VERSION "dbc-export 1 2025.20.8"

NS_ :

BS_:

BU_: APP APS DAS EPAS3S ESP GTW IBST PARK RADC RCM RCM3 TPMS USM

BO_ 586 DAS_visualDebug: 8 DAS
 SG_ DAS_autosteerVehiclesUsage : 4|2@1+ (1,0) [0|3] "" Vector__XXX
 SG_ DAS_autosteerHPPUsage : 6|2@1+ (1,0) [0|3] "" Vector__XXX
 SG_ DAS_autosteerNavigationUsage : 8|2@1+ (1,0) [0|3] "" Vector__XXX
 SG_ DAS_autosteerModelUsage : 10|2@1+ (1,0) [0|3] "" Vector__XXX
 SG_ DAS_autosteerBottsDotsUsage : 12|2@1+ (1,0) [0|3] "" Vector__XXX
 SG_ DAS_offsetSide : 14|2@1+ (1,0) [0|3] "" Vector__XXX
 SG_ DAS_roadSurfaceType : 16|2@1+ (1,0) [1|3] "" Vector__XXX
 SG_ DAS_autosteerHealthAnomalyLevel : 18|3@1+ (1,0) [0|7] "" Vector__XXX
 SG_ DAS_autosteerHealthState : 21|3@1+ (1,0) [0|7] "" Vector__XXX
 SG_ DAS_lastLinePreferenceReason : 24|4@1+ (1,0) [0|15] "" Vector__XXX
 SG_ DAS_plannerState : 28|4@1+ (1,0) [0|15] "" Vector__XXX
 SG_ DAS_lastAutosteerAbortReason : 32|6@1+ (1,0) [0|63] "" Vector__XXX
 SG_ DAS_devAppInterfaceEnabled : 38|1@1+ (1,0) [0|1] "" Vector__XXX
 SG_ DAS_navAvailable : 39|1@1+ (1,0) [0|1] "" Vector__XXX
 SG_ DAS_navDistance : 40|8@1+ (100,0) [0|25500] "km" Vector__XXX
 SG_ DAS_accSmartSpeedActive : 48|1@1+ (1,0) [0|1] "" Vector__XXX
 SG_ DAS_accSmartSpeedState : 49|3@1+ (1,0) [0|6] "" Vector__XXX
 SG_ DAS_ulcInProgress : 52|1@1+ (1,0) [0|1] "" Vector__XXX
 SG_ DAS_trafficAwareSetSpeedInUse : 53|1@1+ (1,0) [0|1] "" Vector__XXX
 SG_ DAS_isaSystemState : 54|2@1+ (1,0) [0|3] "" Vector__XXX
 SG_ DAS_behaviorType : 56|2@1+ (1,0) [0|3] "" Vector__XXX
 SG_ DAS_ulcType : 58|2@1+ (1,0) [0|3] "" Vector__XXX
 SG_ DAS_rearVehDetectedThisCycle : 60|1@1+ (1,0) [0|1] "" Vector__XXX
 SG_ DAS_rearLeftVehDetectedCurrent : 61|1@1+ (1,0) [0|1] "" Vector__XXX
 SG_ DAS_rearRightVehDetectedTrip : 62|1@1+ (1,0) [0|1] "" Vector__XXX
 SG_ DAS_rearLeftVehDetectedTrip : 63|1@1+ (1,0) [0|1] "" Vector__XXX

BO_ 810 DAS_warningMatrix0: 8 DAS
 SG_ DAS_w002_ldwDisabled : 1|1@1+ (1,0) [0|1] "" Vector__XXX
 SG_ DAS_w003_isaDisabled : 2|1@1+ (1,0) [0|1] "" Vector__XXX
 SG_ DAS_w004_accDisabled : 3|1@1+ (1,0) [0|1] "" Vector__XXX
 SG_ DAS_w005_fcwCancelled : 4|1@1+ (1,0) [0|1] "" Vector__XXX
 SG_ DAS_w006_aebCancelled : 5|1@1+ (1,0) [0|1] "" Vector__XXX
 SG_ DAS_w007_ahlbDisabled : 6|1@1+ (1,0) [0|1] "" Vector__XXX
 SG_ DAS_w008_parkDisabled : 7|1@1+ (1,0) [0|1] "" Vector__XXX
 SG_ DAS_w009_aebFault : 8|1@1+ (1,0) [0|1] "" Vector__XXX
 SG_ DAS_w010_radcCalibIssue : 9|1@1+ (1,0) [0|1] "" Vector__XXX
 SG_ DAS_w011_scaEvent : 10|1@1+ (1,0) [0|1] "" Vector__XXX
 SG_ DAS_w012_Cam_BootFailure : 11|1@1+ (1,0) [0|1] "" Vector__XXX
 SG_ DAS_w013_Cam_Watchdog : 12|1@1+ (1,0) [0|1] "" Vector__XXX
 SG_ DAS_w014_swAssert : 13|1@1+ (1,0) [0|1] "" Vector__XXX
 SG_ DAS_w015_Camera_Failsafes : 14|1@1+ (1,0) [0|1] "" Vector__XXX
 SG_ DAS_w016_aeb_e_event : 15|1@1+ (1,0) [0|1] "" Vector__XXX
 SG_ DAS_w017_Cam_Msg_MIA : 16|1@1+ (1,0) [0|1] "" Vector__XXX
 SG_ DAS_w018_ECU_Power_Issue : 17|1@1+ (1,0) [0|1] "" Vector__XXX
 SG_ DAS_w019_ECU_Stack_Overflow : 18|1@1+ (1,0) [0|1] "" Vector__XXX
 SG_ DAS_w020_ECU_checkstopError : 19|1@1+ (1,0) [0|1] "" Vector__XXX
 SG_ DAS_w021_ECU_Temperature_Issue : 20|1@1+ (1,0) [0|1] "" Vector__XXX
 SG_ DAS_w022_ECU_EEPROM_Failure : 21|1@1+ (1,0) [0|1] "" Vector__XXX
 SG_ DAS_w023_ECU_Cam_Statemismatc : 22|1@1+ (1,0) [0|1] "" Vector__XXX
 SG_ DAS_w024_ECU_Watchdog_Reset : 23|1@1+ (1,0) [0|1] "" Vector__XXX
 SG_ DAS_w025_LC_Steering_Override : 24|1@1+ (1,0) [0|1] "" Vector__XXX
 SG_ DAS_w026_ECU_timingIssue : 25|1@1+ (1,0) [0|1] "" Vector__XXX
 SG_ DAS_w027_ECU_Reset_Fault : 26|1@1+ (1,0) [0|1] "" Vector__XXX
 SG_ DAS_w028_spi_rx_error : 27|1@1+ (1,0) [0|1] "" Vector__XXX
 SG_ DAS_w029_spi_tx_error : 28|1@1+ (1,0) [0|1] "" Vector__XXX
 SG_ DAS_w030_Heater_Issue : 29|1@1+ (1,0) [0|1] "" Vector__XXX
 SG_ DAS_w031_canRxError : 30|1@1+ (1,0) [0|1] "" Vector__XXX
 SG_ DAS_w032_canTxError : 31|1@1+ (1,0) [0|1] "" Vector__XXX
 SG_ DAS_w033_gtwMia : 32|1@1+ (1,0) [0|1] "" Vector__XXX
 SG_ DAS_w034_sccmMia : 33|1@1+ (1,0) [0|1] "" Vector__XXX
 SG_ DAS_w035_espMia : 34|1@1+ (1,0) [0|1] "" Vector__XXX
 SG_ DAS_w036_bdyMia : 35|1@1+ (1,0) [0|1] "" Vector__XXX
 SG_ DAS_w037_camTacIssue : 36|1@1+ (1,0) [0|1] "" Vector__XXX
 SG_ DAS_w038_camFailure : 37|1@1+ (1,0) [0|1] "" Vector__XXX
 SG_ DAS_w039_sdm_rcm_Mia : 38|1@1+ (1,0) [0|1] "" Vector__XXX
 SG_ DAS_w040_autopilotAngleSaturated : 39|1@1+ (1,0) [0|1] "" Vector__XXX
 SG_ DAS_w041_autopilotRateSaturated : 40|1@1+ (1,0) [0|1] "" Vector__XXX
 SG_ DAS_w042_autopilotAborting : 41|1@1+ (1,0) [0|1] "" Vector__XXX
 SG_ DAS_w043_camLongRunTime : 42|1@1+ (1,0) [0|1] "" Vector__XXX
 SG_ DAS_w044_appMobileyeFailure : 43|1@1+ (1,0) [0|1] "" Vector__XXX
 SG_ DAS_w045_radMia : 44|1@1+ (1,0) [0|1] "" Vector__XXX
 SG_ DAS_w046_eepromRecordAbsent : 45|1@1+ (1,0) [0|1] "" Vector__XXX
 SG_ DAS_w047_edrEvent : 46|1@1+ (1,0) [0|1] "" Vector__XXX
 SG_ DAS_w048_DAS_Features_Disabled : 47|1@1+ (1,0) [0|1] "" Vector__XXX
 SG_ DAS_w049_eyeqVersionMismatch : 48|1@1+ (1,0) [0|1] "" Vector__XXX
 SG_ DAS_w050_aeb_event : 49|1@1+ (1,0) [0|1] "" Vector__XXX
 SG_ DAS_w051_radcEcuIssue : 50|1@1+ (1,0) [0|1] "" Vector__XXX
 SG_ DAS_w052_radcSensorIssue : 51|1@1+ (1,0) [0|1] "" Vector__XXX
 SG_ DAS_w053_radcCommIssue : 52|1@1+ (1,0) [0|1] "" Vector__XXX
 SG_ DAS_w054_camAutofix : 53|1@1+ (1,0) [0|1] "" Vector__XXX
 SG_ DAS_w055_radcVersionMismatch : 54|1@1+ (1,0) [0|1] "" Vector__XXX
 SG_ DAS_w056_diMia : 55|1@1+ (1,0) [0|1] "" Vector__XXX
 SG_ DAS_w057_mcuMia : 56|1@1+ (1,0) [0|1] "" Vector__XXX
 SG_ DAS_w058_epbMia : 57|1@1+ (1,0) [0|1] "" Vector__XXX
 SG_ DAS_w059_parkMia : 58|1@1+ (1,0) [0|1] "" Vector__XXX
 SG_ DAS_w060_fcw_event : 59|1@1+ (1,0) [0|1] "" Vector__XXX
 SG_ DAS_w061_airSuspensionMia : 60|1@1+ (1,0) [0|1] "" Vector__XXX
 SG_ DAS_w062_radcAlignment : 61|1@1+ (1,0) [0|1] "" Vector__XXX
 SG_ DAS_w063_parkVersionMismatch : 62|1@1+ (1,0) [0|1] "" Vector__XXX
 SG_ DAS_w064_epasMia : 63|1@1+ (1,0) [0|1] "" Vector__XXX

BO_ 874 DAS_warningMatrix1: 8 DAS
 SG_ DAS_w065_deserializerOvercurrent : 0|1@1+ (1,0) [0|1] "" Vector__XXX
 SG_ DAS_w066_deserializerLockLost : 1|1@1+ (1,0) [0|1] "" Vector__XXX
 SG_ DAS_w067_steeringAlignment : 2|1@1+ (1,0) [0|1] "" Vector__XXX
 SG_ DAS_w068_vlInconsistency : 3|1@1+ (1,0) [0|1] "" Vector__XXX
 SG_ DAS_w069_apcSpaceMasked : 4|1@1+ (1,0) [0|1] "" Vector__XXX
 SG_ DAS_w070_apcIncompleteCal : 5|1@1+ (1,0) [0|1] "" Vector__XXX
 SG_ DAS_w071_selfparkStarted : 6|1@1+ (1,0) [0|1] "" Vector__XXX
 SG_ DAS_w072_selfparkComplete : 7|1@1+ (1,0) [0|1] "" Vector__XXX
 SG_ DAS_w073_issueEscalatedLDW : 8|1@1+ (1,0) [0|1] "" Vector__XXX
 SG_ DAS_w074_inPathStationaryObst : 9|1@1+ (1,0) [0|1] "" Vector__XXX
 SG_ DAS_w075_scMia : 10|1@1+ (1,0) [0|1] "" Vector__XXX
 SG_ DAS_w076_mobilEyeSetC : 11|1@1+ (1,0) [0|1] "" Vector__XXX
 SG_ DAS_w077_pmmActive : 12|1@1+ (1,0) [0|1] "" Vector__XXX
 SG_ DAS_w078_pmmActive2 : 13|1@1+ (1,0) [0|1] "" Vector__XXX
 SG_ DAS_w079_edrAvailable : 14|1@1+ (1,0) [0|1] "" Vector__XXX
 SG_ DAS_w080_accFailedActivation : 15|1@1+ (1,0) [0|1] "" Vector__XXX
 SG_ DAS_w081_pmmActiveBraking : 16|1@1+ (1,0) [0|1] "" Vector__XXX
 SG_ DAS_w082_inPathFSviolation : 17|1@1+ (1,0) [0|1] "" Vector__XXX
 SG_ DAS_w083_inPathRADObject : 18|1@1+ (1,0) [0|1] "" Vector__XXX
 SG_ DAS_w084_pmmIPSO : 19|1@1+ (1,0) [0|1] "" Vector__XXX
 SG_ DAS_w085_pmmSteering : 20|1@1+ (1,0) [0|1] "" Vector__XXX
 SG_ DAS_w086_robCollision : 21|1@1+ (1,0) [0|1] "" Vector__XXX
 SG_ DAS_w087_DEPRECATED : 22|1@1+ (1,0) [0|1] "" Vector__XXX
 SG_ DAS_w088_DEPRECATED : 23|1@1+ (1,0) [0|1] "" Vector__XXX
 SG_ DAS_w089_DEPRECATED : 24|1@1+ (1,0) [0|1] "" Vector__XXX
 SG_ DAS_w090_DEPRECATED : 25|1@1+ (1,0) [0|1] "" Vector__XXX
 SG_ DAS_w091_DEPRECATED : 26|1@1+ (1,0) [0|1] "" Vector__XXX
 SG_ DAS_w092_DEPRECATED : 27|1@1+ (1,0) [0|1] "" Vector__XXX
 SG_ DAS_w093_DEPRECATED : 28|1@1+ (1,0) [0|1] "" Vector__XXX
 SG_ DAS_w094_DEPRECATED : 29|1@1+ (1,0) [0|1] "" Vector__XXX
 SG_ DAS_w095_DEPRECATED : 30|1@1+ (1,0) [0|1] "" Vector__XXX
 SG_ DAS_w096_DEPRECATED : 31|1@1+ (1,0) [0|1] "" Vector__XXX
 SG_ DAS_w097_DEPRECATED : 32|1@1+ (1,0) [0|1] "" Vector__XXX
 SG_ DAS_w098_DEPRECATED : 33|1@1+ (1,0) [0|1] "" Vector__XXX
 SG_ DAS_w099_DEPRECATED : 34|1@1+ (1,0) [0|1] "" Vector__XXX
 SG_ DAS_w100_DEPRECATED : 35|1@1+ (1,0) [0|1] "" Vector__XXX
 SG_ DAS_w101_DEPRECATED : 36|1@1+ (1,0) [0|1] "" Vector__XXX
 SG_ DAS_w102_DEPRECATED : 37|1@1+ (1,0) [0|1] "" Vector__XXX
 SG_ DAS_w103_robExperimentalAEB : 38|1@1+ (1,0) [0|1] "" Vector__XXX
 SG_ DAS_w104_DEPRECATED : 39|1@1+ (1,0) [0|1] "" Vector__XXX
 SG_ DAS_w105_DEPRECATED : 40|1@1+ (1,0) [0|1] "" Vector__XXX
 SG_ DAS_w106_torsionBarCalibrated : 41|1@1+ (1,0) [0|1] "" Vector__XXX

BO_ 841 DAS_warningMatrix2: 8 DAS
 SG_ DAS_w129_mainCamExtNotCal : 0|1@1+ (1,0) [0|1] "" Vector__XXX
 SG_ DAS_w130_narrowCamExtNotCal : 1|1@1+ (1,0) [0|1] "" Vector__XXX
 SG_ DAS_w131_mainCamCalSaved : 2|1@1+ (1,0) [0|1] "" Vector__XXX
 SG_ DAS_w132_narrowCamCalSaved : 3|1@1+ (1,0) [0|1] "" Vector__XXX
 SG_ DAS_w133_mainCamInitFault : 4|1@1+ (1,0) [0|1] "" Vector__XXX
 SG_ DAS_w134_narrowCamInitFault : 5|1@1+ (1,0) [0|1] "" Vector__XXX
 SG_ DAS_w135_fisheyeCamInitFault : 6|1@1+ (1,0) [0|1] "" Vector__XXX
 SG_ DAS_w136_lPillarCamInitFault : 7|1@1+ (1,0) [0|1] "" Vector__XXX
 SG_ DAS_w137_rPillarCamInitFault : 8|1@1+ (1,0) [0|1] "" Vector__XXX
 SG_ DAS_w138_lRepeatCamInitFault : 9|1@1+ (1,0) [0|1] "" Vector__XXX
 SG_ DAS_w139_rRepeatCamInitFault : 10|1@1+ (1,0) [0|1] "" Vector__XXX
 SG_ DAS_w140_backupCamInitFault : 11|1@1+ (1,0) [0|1] "" Vector__XXX
 SG_ DAS_w141_ECU_Thermal_Issue : 12|1@1+ (1,0) [0|1] "" Vector__XXX
 SG_ DAS_w142_fwdCamPitchProblem : 13|1@1+ (1,0) [0|1] "" Vector__XXX
 SG_ DAS_w143_IDF_event : 14|1@1+ (1,0) [0|1] "" Vector__XXX
 SG_ DAS_w144_selfieCamInitFault : 15|1@1+ (1,0) [0|1] "" Vector__XXX
 SG_ DAS_w171_fisheyeCamExtNotCal : 42|1@1+ (1,0) [0|1] "" Vector__XXX
 SG_ DAS_w172_lPillarCamExtNotCal : 43|1@1+ (1,0) [0|1] "" Vector__XXX
 SG_ DAS_w173_rPillarCamExtNotCal : 44|1@1+ (1,0) [0|1] "" Vector__XXX
 SG_ DAS_w174_lRepeatCamExtNotCal : 45|1@1+ (1,0) [0|1] "" Vector__XXX
 SG_ DAS_w175_rRepeatCamExtNotCal : 46|1@1+ (1,0) [0|1] "" Vector__XXX
 SG_ DAS_w177_fisheyeCamCalSaved : 48|1@1+ (1,0) [0|1] "" Vector__XXX
 SG_ DAS_w178_lPillarCamCalSaved : 49|1@1+ (1,0) [0|1] "" Vector__XXX
 SG_ DAS_w179_rPillarCamCalSaved : 50|1@1+ (1,0) [0|1] "" Vector__XXX
 SG_ DAS_w180_lRepeatCamCalSaved : 51|1@1+ (1,0) [0|1] "" Vector__XXX
 SG_ DAS_w181_rRepeatCamCalSaved : 52|1@1+ (1,0) [0|1] "" Vector__XXX

BO_ 1082 DAS_warningMatrix3: 8 DAS
 SG_ DAS_w193_camWindshieldUnclean : 0|1@1+ (1,0) [0|1] "" Vector__XXX
 SG_ DAS_w194_accDriverResumeRqrd : 1|1@1+ (1,0) [0|1] "" Vector__XXX
 SG_ DAS_w195_scwUnavailable : 2|1@1+ (1,0) [0|1] "" Vector__XXX
 SG_ DAS_w196_stopSignWarning : 3|1@1+ (1,0) [0|1] "" Vector__XXX
 SG_ DAS_w197_redLightWarning : 4|1@1+ (1,0) [0|1] "" Vector__XXX
 SG_ DAS_w198_tsrUnavailable : 5|1@1+ (1,0) [0|1] "" Vector__XXX
 SG_ DAS_w199_apcAbort : 6|1@1+ (1,0) [0|1] "" Vector__XXX
 SG_ DAS_w200_lcSlowdown : 7|1@1+ (1,0) [0|1] "" Vector__XXX
 SG_ DAS_w201_lcAborting : 8|1@1+ (1,0) [0|1] "" Vector__XXX
 SG_ DAS_w202_scwNoisyEnvironment : 9|1@1+ (1,0) [0|1] "" Vector__XXX
 SG_ DAS_w203_apcActivation : 10|1@1+ (1,0) [0|1] "" Vector__XXX
 SG_ DAS_w204_apcFinalFront : 11|1@1+ (1,0) [0|1] "" Vector__XXX
 SG_ DAS_w205_apcFinalRear : 12|1@1+ (1,0) [0|1] "" Vector__XXX
 SG_ DAS_w206_autosteerNotEnabled : 13|1@1+ (1,0) [0|1] "" Vector__XXX
 SG_ DAS_w207_autosteerUnavailable : 14|1@1+ (1,0) [0|1] "" Vector__XXX
 SG_ DAS_w208_rackDetected : 15|1@1+ (1,0) [0|1] "" Vector__XXX
 SG_ DAS_w209_autoSummonRequest : 16|1@1+ (1,0) [0|1] "" Vector__XXX
 SG_ DAS_w210_camObstrcted : 17|1@1+ (1,0) [0|1] "" Vector__XXX
 SG_ DAS_w211_accNoSeatBelt : 18|1@1+ (1,0) [0|1] "" Vector__XXX
 SG_ DAS_w212_lcUnavailableStrikeOut : 19|1@1+ (1,0) [0|1] "" Vector__XXX
 SG_ DAS_w213_autosteerStruckOut : 20|1@1+ (1,0) [0|1] "" Vector__XXX
 SG_ DAS_w214_driverNotIntracting : 21|1@1+ (1,0) [0|1] "" Vector__XXX
 SG_ DAS_w215_contDriverNotIntracting : 22|1@1+ (1,0) [0|1] "" Vector__XXX
 SG_ DAS_w216_driverOverriding : 23|1@1+ (1,0) [0|1] "" Vector__XXX
 SG_ DAS_w217_lcUnavailableSpeeding : 24|1@1+ (1,0) [0|1] "" Vector__XXX
 SG_ DAS_w218_lcSpeedExceededLimit : 25|1@1+ (1,0) [0|1] "" Vector__XXX
 SG_ DAS_w219_lcTempUnavailableSpeed : 26|1@1+ (1,0) [0|1] "" Vector__XXX
 SG_ DAS_w220_lcTempUnavailableRoad : 27|1@1+ (1,0) [0|1] "" Vector__XXX
 SG_ DAS_w221_accRadarBlind : 28|1@1+ (1,0) [0|1] "" Vector__XXX
 SG_ DAS_w222_accCameraBlind : 29|1@1+ (1,0) [0|1] "" Vector__XXX
 SG_ DAS_w223_accObjectInPath : 30|1@1+ (1,0) [0|1] "" Vector__XXX
 SG_ DAS_w224_accCameraCalibration : 31|1@1+ (1,0) [0|1] "" Vector__XXX
 SG_ DAS_w225_lcDegradedVisSpeedLmt : 32|1@1+ (1,0) [0|1] "" Vector__XXX
 SG_ DAS_w226_lcCamCalNeededSpeedLmt : 33|1@1+ (1,0) [0|1] "" Vector__XXX
 SG_ DAS_w227_virtualWallBlocked : 34|1@1+ (1,0) [0|1] "" Vector__XXX
 SG_ DAS_w228_DEPRECATED : 35|1@1+ (1,0) [0|1] "" Vector__XXX
 SG_ DAS_w229_alcUltrasoundDamaged : 36|1@1+ (1,0) [0|1] "" Vector__XXX
 SG_ DAS_w230_alcUltrasoundBlocked : 37|1@1+ (1,0) [0|1] "" Vector__XXX
 SG_ DAS_w231_idfEvent : 38|1@1+ (1,0) [0|1] "" Vector__XXX
 SG_ DAS_w232_laneChangeRequested : 39|1@1+ (1,0) [0|1] "" Vector__XXX

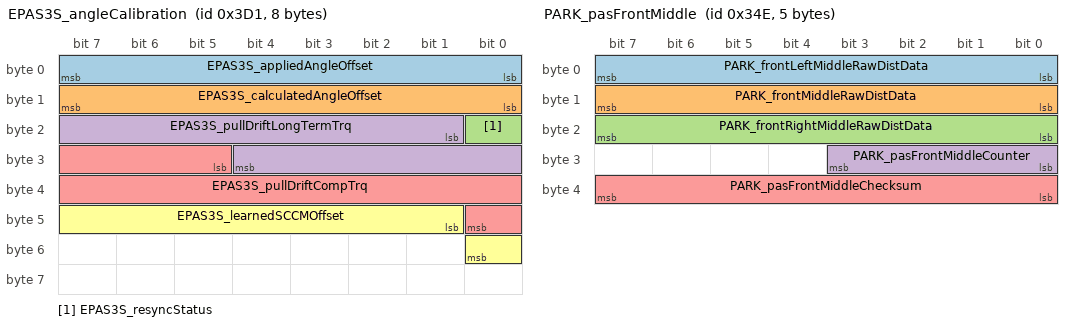
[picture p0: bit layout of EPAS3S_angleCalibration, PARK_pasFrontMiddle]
BO_ 977 EPAS3S_angleCalibration: 8 EPAS3S
 SG_ EPAS3S_appliedAngleOffset : 0|8@1+ (0.1,-12.8) [-12.8|12.7] "deg" Vector__XXX
 SG_ EPAS3S_calculatedAngleOffset : 8|8@1+ (0.1,-12.8) [-12.8|12.7] "deg" Vector__XXX
 SG_ EPAS3S_resyncStatus : 16|1@1+ (1,0) [0|1] "" Vector__XXX
 SG_ EPAS3S_pullDriftLongTermTrq : 17|12@1+ (0.01,-10) [-10|10] "Nm" Vector__XXX
 SG_ EPAS3S_pullDriftCompTrq : 29|12@1+ (0.01,-10) [-10|10] "Nm" Vector__XXX
 SG_ EPAS3S_learnedSCCMOffset : 41|8@1+ (0.1,-12.8) [-12.8|12.7] "deg" Vector__XXX

BO_ 785 EPAS3S_info: 8 EPAS3S
 SG_ EPAS3S_infoIndex M : 0|8@1+ (1,0) [0|255] "" Vector__XXX
 SG_ EPAS3S_infoBuildType m10 : 8|8@1+ (1,0) [0|255] "" Vector__XXX
 SG_ EPAS3S_infoComponentID m10 : 48|16@1+ (1,0) [0|65535] "" Vector__XXX
 SG_ EPAS3S_infoPcbaID m11 : 16|8@1+ (1,0) [0|255] "" Vector__XXX
 SG_ EPAS3S_infoAssemblyID m11 : 24|8@1+ (1,0) [0|255] "" Vector__XXX
 SG_ EPAS3S_infoUsageID m11 : 32|16@1+ (1,0) [0|65535] "" Vector__XXX
 SG_ EPAS3S_infoApplicationCRC m13 : 32|32@1+ (1,0) [0|4294967295] "" Vector__XXX
 SG_ EPAS3S_infoBootUdsProtoVersion m20 : 8|8@1+ (1,0) [0|255] "" Vector__XXX
 SG_ EPAS3S_infoBootloaderCRC m20 : 32|32@1+ (1,0) [0|4294967295] "" Vector__XXX
 SG_ EPAS3S_infoSubcomponent2 m23 : 32|32@1+ (1,0) [0|4294967295] "" Vector__XXX

BO_ 805 ESP_info: 8 ESP
 SG_ ESP_infoIndex M : 0|8@1+ (1,0) [0|255] "" Vector__XXX
 SG_ ESP_infoBuildType m10 : 8|8@1+ (1,0) [0|255] "" Vector__XXX
 SG_ ESP_vehFlashMode m10 : 24|1@1+ (1,0) [0|1] "" Vector__XXX
 SG_ ESP_infoComponentID m10 : 48|16@1+ (1,0) [0|65535] "" Vector__XXX
 SG_ ESP_infoPcbaID m11 : 16|8@1+ (1,0) [0|255] "" Vector__XXX
 SG_ ESP_infoAssemblyID m11 : 24|8@1+ (1,0) [0|255] "" Vector__XXX
 SG_ ESP_infoUsageID m11 : 32|16@1+ (1,0) [0|65535] "" Vector__XXX
 SG_ ESP_infoSubUsageID m11 : 48|16@1+ (1,0) [0|65535] "" Vector__XXX
 SG_ ESP_infoApplicationCRC m13 : 39|32@0+ (1,0) [0|4294967295] "" Vector__XXX
 SG_ ESP_infoVehicleVariant m16 : 16|8@1+ (1,0) [0|255] "" Vector__XXX
 SG_ ESP_infoSubcomponent1 m16 : 32|32@1+ (1,0) [0|4294967295] "" Vector__XXX
 SG_ ESP_infoBootUdsProtoVersion m20 : 8|8@1+ (1,0) [0|255] "" Vector__XXX
 SG_ ESP_infoBootloaderCRC m20 : 32|32@1+ (1,0) [0|4294967295] "" Vector__XXX
 SG_ ESP_infoVariantCRC m22 : 39|32@0+ (1,0) [0|4294967295] "" Vector__XXX

BO_ 813 IBST_info: 8 IBST
 SG_ IBST_infoIndex M : 0|8@1+ (1,0) [0|255] "" Vector__XXX
 SG_ IBST_infoBuildType m10 : 8|8@1+ (1,0) [0|255] "" Vector__XXX
 SG_ IBST_infoComponentID m10 : 55|16@0+ (1,0) [0|65535] "" Vector__XXX
 SG_ IBST_infoPcbaID m11 : 16|8@1+ (1,0) [0|255] "" Vector__XXX
 SG_ IBST_infoAssemblyID m11 : 24|8@1+ (1,0) [0|255] "" Vector__XXX
 SG_ IBST_infoUsageID m11 : 32|16@1+ (1,0) [0|65535] "" Vector__XXX
 SG_ IBST_infoSubUsageID m11 : 48|16@1+ (1,0) [0|65535] "" Vector__XXX
 SG_ IBST_infoApplicationCRC m13 : 32|32@1+ (1,0) [0|4294967295] "" Vector__XXX
 SG_ IBST_infoBootUdsProtoVersion m20 : 8|8@1+ (1,0) [0|255] "" Vector__XXX
 SG_ IBST_infoBootloaderCRC m20 : 32|32@1+ (1,0) [0|4294967295] "" Vector__XXX
 SG_ IBST_infoVariantCRC m22 : 32|32@1+ (1,0) [0|4294967295] "" Vector__XXX

BO_ 1486 PARK_alertLog: 8 PARK
 SG_ PARK_alertID M : 0|7@1+ (1,0) [0|127] "" Vector__XXX
 SG_ PARK_alertState : 15|1@1+ (1,0) [0|1] "" Vector__XXX
 SG_ PARK_sw001_sensorTemperature m1 : 16|16@1+ (0.1,-40) [-40|6513.5] "deg" Vector__XXX
 SG_ PARK_sw002_membraneDisconct m2 : 16|1@1+ (1,0) [0|1] "" Vector__XXX
 SG_ PARK_sw002_dampResistorFail m2 : 17|1@1+ (1,0) [0|1] "" Vector__XXX
 SG_ PARK_sw002_resonanceDrift m2 : 18|1@1+ (1,0) [0|1] "" Vector__XXX
 SG_ PARK_sw002_sensorCRC m2 : 19|1@1+ (1,0) [0|1] "" Vector__XXX
 SG_ PARK_sw002_recieveFailure m2 : 20|1@1+ (1,0) [0|1] "" Vector__XXX
 SG_ PARK_sw002_diagnosticTransferErr m2 : 21|1@1+ (1,0) [0|1] "" Vector__XXX
 SG_ PARK_sw003_linError m3 : 16|1@1+ (1,0) [0|1] "" Vector__XXX
 SG_ PARK_sw003_linBusError m3 : 17|1@1+ (1,0) [0|1] "" Vector__XXX
 SG_ PARK_sw003_linFrameCountError m3 : 18|1@1+ (1,0) [0|1] "" Vector__XXX
 SG_ PARK_sw004_reverbPeriod m4 : 16|16@1+ (1,0) [0|65535] "microseconds" Vector__XXX
 SG_ PARK_sw004_reverbTime m4 : 32|16@1+ (1,0) [0|65535] "microseconds" Vector__XXX
 SG_ PARK_sw004_highAttenTime m4 : 48|1@1+ (1,0) [0|1] "" Vector__XXX
 SG_ PARK_sw004_closeConstEcho m4 : 49|1@1+ (1,0) [0|1] "" Vector__XXX
 SG_ PARK_sw004_lowAttenTime m4 : 50|1@1+ (1,0) [0|1] "" Vector__XXX
 SG_ PARK_sw004_attenTimeJitter m4 : 51|1@1+ (1,0) [0|1] "" Vector__XXX
 SG_ PARK_sw004_reverbFreqJitter m4 : 52|1@1+ (1,0) [0|1] "" Vector__XXX
 SG_ PARK_sw006_sensorTemperature m6 : 16|16@1+ (0.1,-40) [-40|6513.5] "deg" Vector__XXX
 SG_ PARK_sw007_membraneDisconct m7 : 16|1@1+ (1,0) [0|1] "" Vector__XXX
 SG_ PARK_sw007_dampResistorFail m7 : 17|1@1+ (1,0) [0|1] "" Vector__XXX
 SG_ PARK_sw007_resonanceDrift m7 : 18|1@1+ (1,0) [0|1] "" Vector__XXX
 SG_ PARK_sw007_sensorCRC m7 : 19|1@1+ (1,0) [0|1] "" Vector__XXX
 SG_ PARK_sw007_recieveFailure m7 : 20|1@1+ (1,0) [0|1] "" Vector__XXX
 SG_ PARK_sw007_diagnosticTransferErr m7 : 21|1@1+ (1,0) [0|1] "" Vector__XXX
 SG_ PARK_sw008_linError m8 : 16|1@1+ (1,0) [0|1] "" Vector__XXX
 SG_ PARK_sw008_linBusError m8 : 17|1@1+ (1,0) [0|1] "" Vector__XXX
 SG_ PARK_sw008_linFrameCountError m8 : 18|1@1+ (1,0) [0|1] "" Vector__XXX
 SG_ PARK_sw009_reverbPeriod m9 : 16|16@1+ (1,0) [0|65535] "microseconds" Vector__XXX
 SG_ PARK_sw009_reverbTime m9 : 32|16@1+ (1,0) [0|65535] "microseconds" Vector__XXX
 SG_ PARK_sw009_highAttenTime m9 : 48|1@1+ (1,0) [0|1] "" Vector__XXX
 SG_ PARK_sw009_closeConstEcho m9 : 49|1@1+ (1,0) [0|1] "" Vector__XXX
 SG_ PARK_sw009_lowAttenTime m9 : 50|1@1+ (1,0) [0|1] "" Vector__XXX
 SG_ PARK_sw009_attenTimeJitter m9 : 51|1@1+ (1,0) [0|1] "" Vector__XXX
 SG_ PARK_sw009_reverbFreqJitter m9 : 52|1@1+ (1,0) [0|1] "" Vector__XXX
 SG_ PARK_sw011_sensorTemperature m11 : 16|16@1+ (0.1,-40) [-40|6513.5] "deg" Vector__XXX
 SG_ PARK_sw012_membraneDisconct m12 : 16|1@1+ (1,0) [0|1] "" Vector__XXX
 SG_ PARK_sw012_dampResistorFail m12 : 17|1@1+ (1,0) [0|1] "" Vector__XXX
 SG_ PARK_sw012_resonanceDrift m12 : 18|1@1+ (1,0) [0|1] "" Vector__XXX
 SG_ PARK_sw012_sensorCRC m12 : 19|1@1+ (1,0) [0|1] "" Vector__XXX
 SG_ PARK_sw012_recieveFailure m12 : 20|1@1+ (1,0) [0|1] "" Vector__XXX
 SG_ PARK_sw012_diagnosticTransferErr m12 : 21|1@1+ (1,0) [0|1] "" Vector__XXX
 SG_ PARK_sw013_linError m13 : 16|1@1+ (1,0) [0|1] "" Vector__XXX
 SG_ PARK_sw013_linBusError m13 : 17|1@1+ (1,0) [0|1] "" Vector__XXX
 SG_ PARK_sw013_linFrameCountError m13 : 18|1@1+ (1,0) [0|1] "" Vector__XXX
 SG_ PARK_sw014_reverbPeriod m14 : 16|16@1+ (1,0) [0|65535] "microseconds" Vector__XXX
 SG_ PARK_sw014_reverbTime m14 : 32|16@1+ (1,0) [0|65535] "microseconds" Vector__XXX
 SG_ PARK_sw014_highAttenTime m14 : 48|1@1+ (1,0) [0|1] "" Vector__XXX
 SG_ PARK_sw014_closeConstEcho m14 : 49|1@1+ (1,0) [0|1] "" Vector__XXX
 SG_ PARK_sw014_lowAttenTime m14 : 50|1@1+ (1,0) [0|1] "" Vector__XXX
 SG_ PARK_sw014_attenTimeJitter m14 : 51|1@1+ (1,0) [0|1] "" Vector__XXX
 SG_ PARK_sw014_reverbFreqJitter m14 : 52|1@1+ (1,0) [0|1] "" Vector__XXX
 SG_ PARK_sw016_sensorTemperature m16 : 16|16@1+ (0.1,-40) [-40|6513.5] "deg" Vector__XXX
 SG_ PARK_sw017_membraneDisconct m17 : 16|1@1+ (1,0) [0|1] "" Vector__XXX
 SG_ PARK_sw017_dampResistorFail m17 : 17|1@1+ (1,0) [0|1] "" Vector__XXX
 SG_ PARK_sw017_resonanceDrift m17 : 18|1@1+ (1,0) [0|1] "" Vector__XXX
 SG_ PARK_sw017_sensorCRC m17 : 19|1@1+ (1,0) [0|1] "" Vector__XXX
 SG_ PARK_sw017_recieveFailure m17 : 20|1@1+ (1,0) [0|1] "" Vector__XXX
 SG_ PARK_sw017_diagnosticTransferErr m17 : 21|1@1+ (1,0) [0|1] "" Vector__XXX
 SG_ PARK_sw018_linError m18 : 16|1@1+ (1,0) [0|1] "" Vector__XXX
 SG_ PARK_sw018_linBusError m18 : 17|1@1+ (1,0) [0|1] "" Vector__XXX
 SG_ PARK_sw018_linFrameCountError m18 : 18|1@1+ (1,0) [0|1] "" Vector__XXX
 SG_ PARK_sw019_reverbPeriod m19 : 16|16@1+ (1,0) [0|65535] "microseconds" Vector__XXX
 SG_ PARK_sw019_reverbTime m19 : 32|16@1+ (1,0) [0|65535] "microseconds" Vector__XXX
 SG_ PARK_sw019_highAttenTime m19 : 48|1@1+ (1,0) [0|1] "" Vector__XXX
 SG_ PARK_sw019_closeConstEcho m19 : 49|1@1+ (1,0) [0|1] "" Vector__XXX
 SG_ PARK_sw019_lowAttenTime m19 : 50|1@1+ (1,0) [0|1] "" Vector__XXX
 SG_ PARK_sw019_attenTimeJitter m19 : 51|1@1+ (1,0) [0|1] "" Vector__XXX
 SG_ PARK_sw019_reverbFreqJitter m19 : 52|1@1+ (1,0) [0|1] "" Vector__XXX
 SG_ PARK_sw021_sensorTemperature m21 : 16|16@1+ (0.1,-40) [-40|6513.5] "deg" Vector__XXX
 SG_ PARK_sw022_membraneDisconct m22 : 16|1@1+ (1,0) [0|1] "" Vector__XXX
 SG_ PARK_sw022_dampResistorFail m22 : 17|1@1+ (1,0) [0|1] "" Vector__XXX
 SG_ PARK_sw022_resonanceDrift m22 : 18|1@1+ (1,0) [0|1] "" Vector__XXX
 SG_ PARK_sw022_sensorCRC m22 : 19|1@1+ (1,0) [0|1] "" Vector__XXX
 SG_ PARK_sw022_recieveFailure m22 : 20|1@1+ (1,0) [0|1] "" Vector__XXX
 SG_ PARK_sw022_diagnosticTransferErr m22 : 21|1@1+ (1,0) [0|1] "" Vector__XXX
 SG_ PARK_sw023_linError m23 : 16|1@1+ (1,0) [0|1] "" Vector__XXX
 SG_ PARK_sw023_linBusError m23 : 17|1@1+ (1,0) [0|1] "" Vector__XXX
 SG_ PARK_sw023_linFrameCountError m23 : 18|1@1+ (1,0) [0|1] "" Vector__XXX
 SG_ PARK_sw024_reverbPeriod m24 : 16|16@1+ (1,0) [0|65535] "microseconds" Vector__XXX
 SG_ PARK_sw024_reverbTime m24 : 32|16@1+ (1,0) [0|65535] "microseconds" Vector__XXX
 SG_ PARK_sw024_highAttenTime m24 : 48|1@1+ (1,0) [0|1] "" Vector__XXX
 SG_ PARK_sw024_closeConstEcho m24 : 49|1@1+ (1,0) [0|1] "" Vector__XXX
 SG_ PARK_sw024_lowAttenTime m24 : 50|1@1+ (1,0) [0|1] "" Vector__XXX
 SG_ PARK_sw024_attenTimeJitter m24 : 51|1@1+ (1,0) [0|1] "" Vector__XXX
 SG_ PARK_sw024_reverbFreqJitter m24 : 52|1@1+ (1,0) [0|1] "" Vector__XXX
 SG_ PARK_sw026_sensorTemperature m26 : 16|16@1+ (0.1,-40) [-40|6513.5] "deg" Vector__XXX
 SG_ PARK_sw027_membraneDisconct m27 : 16|1@1+ (1,0) [0|1] "" Vector__XXX
 SG_ PARK_sw027_dampResistorFail m27 : 17|1@1+ (1,0) [0|1] "" Vector__XXX
 SG_ PARK_sw027_resonanceDrift m27 : 18|1@1+ (1,0) [0|1] "" Vector__XXX
 SG_ PARK_sw027_sensorCRC m27 : 19|1@1+ (1,0) [0|1] "" Vector__XXX
 SG_ PARK_sw027_recieveFailure m27 : 20|1@1+ (1,0) [0|1] "" Vector__XXX
 SG_ PARK_sw027_diagnosticTransferErr m27 : 21|1@1+ (1,0) [0|1] "" Vector__XXX
 SG_ PARK_sw028_linError m28 : 16|1@1+ (1,0) [0|1] "" Vector__XXX
 SG_ PARK_sw028_linBusError m28 : 17|1@1+ (1,0) [0|1] "" Vector__XXX
 SG_ PARK_sw028_linFrameCountError m28 : 18|1@1+ (1,0) [0|1] "" Vector__XXX
 SG_ PARK_sw029_reverbPeriod m29 : 16|16@1+ (1,0) [0|65535] "microseconds" Vector__XXX
 SG_ PARK_sw029_reverbTime m29 : 32|16@1+ (1,0) [0|65535] "microseconds" Vector__XXX
 SG_ PARK_sw029_highAttenTime m29 : 48|1@1+ (1,0) [0|1] "" Vector__XXX
 SG_ PARK_sw029_closeConstEcho m29 : 49|1@1+ (1,0) [0|1] "" Vector__XXX
 SG_ PARK_sw029_lowAttenTime m29 : 50|1@1+ (1,0) [0|1] "" Vector__XXX
 SG_ PARK_sw029_attenTimeJitter m29 : 51|1@1+ (1,0) [0|1] "" Vector__XXX
 SG_ PARK_sw029_reverbFreqJitter m29 : 52|1@1+ (1,0) [0|1] "" Vector__XXX
 SG_ PARK_sw031_sensorTemperature m31 : 16|16@1+ (0.1,-40) [-40|6513.5] "deg" Vector__XXX
 SG_ PARK_sw032_membraneDisconct m32 : 16|1@1+ (1,0) [0|1] "" Vector__XXX
 SG_ PARK_sw032_dampResistorFail m32 : 17|1@1+ (1,0) [0|1] "" Vector__XXX
 SG_ PARK_sw032_resonanceDrift m32 : 18|1@1+ (1,0) [0|1] "" Vector__XXX
 SG_ PARK_sw032_sensorCRC m32 : 19|1@1+ (1,0) [0|1] "" Vector__XXX
 SG_ PARK_sw032_recieveFailure m32 : 20|1@1+ (1,0) [0|1] "" Vector__XXX
 SG_ PARK_sw032_diagnosticTransferErr m32 : 21|1@1+ (1,0) [0|1] "" Vector__XXX
 SG_ PARK_sw033_linError m33 : 16|1@1+ (1,0) [0|1] "" Vector__XXX
 SG_ PARK_sw033_linBusError m33 : 17|1@1+ (1,0) [0|1] "" Vector__XXX
 SG_ PARK_sw033_linFrameCountError m33 : 18|1@1+ (1,0) [0|1] "" Vector__XXX
 SG_ PARK_sw034_reverbPeriod m34 : 16|16@1+ (1,0) [0|65535] "microseconds" Vector__XXX
 SG_ PARK_sw034_reverbTime m34 : 32|16@1+ (1,0) [0|65535] "microseconds" Vector__XXX
 SG_ PARK_sw034_highAttenTime m34 : 48|1@1+ (1,0) [0|1] "" Vector__XXX
 SG_ PARK_sw034_closeConstEcho m34 : 49|1@1+ (1,0) [0|1] "" Vector__XXX
 SG_ PARK_sw034_lowAttenTime m34 : 50|1@1+ (1,0) [0|1] "" Vector__XXX
 SG_ PARK_sw034_attenTimeJitter m34 : 51|1@1+ (1,0) [0|1] "" Vector__XXX
 SG_ PARK_sw034_reverbFreqJitter m34 : 52|1@1+ (1,0) [0|1] "" Vector__XXX
 SG_ PARK_sw036_sensorTemperature m36 : 16|16@1+ (0.1,-40) [-40|6513.5] "deg" Vector__XXX
 SG_ PARK_sw037_membraneDisconct m37 : 16|1@1+ (1,0) [0|1] "" Vector__XXX
 SG_ PARK_sw037_dampResistorFail m37 : 17|1@1+ (1,0) [0|1] "" Vector__XXX
 SG_ PARK_sw037_resonanceDrift m37 : 18|1@1+ (1,0) [0|1] "" Vector__XXX
 SG_ PARK_sw037_sensorCRC m37 : 19|1@1+ (1,0) [0|1] "" Vector__XXX
 SG_ PARK_sw037_recieveFailure m37 : 20|1@1+ (1,0) [0|1] "" Vector__XXX
 SG_ PARK_sw037_diagnosticTransferErr m37 : 21|1@1+ (1,0) [0|1] "" Vector__XXX
 SG_ PARK_sw038_linError m38 : 16|1@1+ (1,0) [0|1] "" Vector__XXX
 SG_ PARK_sw038_linBusError m38 : 17|1@1+ (1,0) [0|1] "" Vector__XXX
 SG_ PARK_sw038_linFrameCountError m38 : 18|1@1+ (1,0) [0|1] "" Vector__XXX
 SG_ PARK_sw039_reverbPeriod m39 : 16|16@1+ (1,0) [0|65535] "microseconds" Vector__XXX
 SG_ PARK_sw039_reverbTime m39 : 32|16@1+ (1,0) [0|65535] "microseconds" Vector__XXX
 SG_ PARK_sw039_highAttenTime m39 : 48|1@1+ (1,0) [0|1] "" Vector__XXX
 SG_ PARK_sw039_closeConstEcho m39 : 49|1@1+ (1,0) [0|1] "" Vector__XXX
 SG_ PARK_sw039_lowAttenTime m39 : 50|1@1+ (1,0) [0|1] "" Vector__XXX
 SG_ PARK_sw039_attenTimeJitter m39 : 51|1@1+ (1,0) [0|1] "" Vector__XXX
 SG_ PARK_sw039_reverbFreqJitter m39 : 52|1@1+ (1,0) [0|1] "" Vector__XXX
 SG_ PARK_sw041_sensorTemperature m41 : 16|16@1+ (0.1,-40) [-40|6513.5] "deg" Vector__XXX
 SG_ PARK_sw042_membraneDisconct m42 : 16|1@1+ (1,0) [0|1] "" Vector__XXX
 SG_ PARK_sw042_dampResistorFail m42 : 17|1@1+ (1,0) [0|1] "" Vector__XXX
 SG_ PARK_sw042_resonanceDrift m42 : 18|1@1+ (1,0) [0|1] "" Vector__XXX
 SG_ PARK_sw042_sensorCRC m42 : 19|1@1+ (1,0) [0|1] "" Vector__XXX
 SG_ PARK_sw042_recieveFailure m42 : 20|1@1+ (1,0) [0|1] "" Vector__XXX
 SG_ PARK_sw042_diagnosticTransferErr m42 : 21|1@1+ (1,0) [0|1] "" Vector__XXX
 SG_ PARK_sw043_linError m43 : 16|1@1+ (1,0) [0|1] "" Vector__XXX
 SG_ PARK_sw043_linBusError m43 : 17|1@1+ (1,0) [0|1] "" Vector__XXX
 SG_ PARK_sw043_linFrameCountError m43 : 18|1@1+ (1,0) [0|1] "" Vector__XXX
 SG_ PARK_sw044_reverbPeriod m44 : 16|16@1+ (1,0) [0|65535] "microseconds" Vector__XXX
 SG_ PARK_sw044_reverbTime m44 : 32|16@1+ (1,0) [0|65535] "microseconds" Vector__XXX
 SG_ PARK_sw044_highAttenTime m44 : 48|1@1+ (1,0) [0|1] "" Vector__XXX
 SG_ PARK_sw044_closeConstEcho m44 : 49|1@1+ (1,0) [0|1] "" Vector__XXX
 SG_ PARK_sw044_lowAttenTime m44 : 50|1@1+ (1,0) [0|1] "" Vector__XXX
 SG_ PARK_sw044_attenTimeJitter m44 : 51|1@1+ (1,0) [0|1] "" Vector__XXX
 SG_ PARK_sw044_reverbFreqJitter m44 : 52|1@1+ (1,0) [0|1] "" Vector__XXX
 SG_ PARK_sw046_sensorTemperature m46 : 16|16@1+ (0.1,-40) [-40|6513.5] "deg" Vector__XXX
 SG_ PARK_sw047_membraneDisconct m47 : 16|1@1+ (1,0) [0|1] "" Vector__XXX
 SG_ PARK_sw047_dampResistorFail m47 : 17|1@1+ (1,0) [0|1] "" Vector__XXX
 SG_ PARK_sw047_resonanceDrift m47 : 18|1@1+ (1,0) [0|1] "" Vector__XXX
 SG_ PARK_sw047_sensorCRC m47 : 19|1@1+ (1,0) [0|1] "" Vector__XXX
 SG_ PARK_sw047_recieveFailure m47 : 20|1@1+ (1,0) [0|1] "" Vector__XXX
 SG_ PARK_sw047_diagnosticTransferErr m47 : 21|1@1+ (1,0) [0|1] "" Vector__XXX
 SG_ PARK_sw048_linError m48 : 16|1@1+ (1,0) [0|1] "" Vector__XXX
 SG_ PARK_sw048_linBusError m48 : 17|1@1+ (1,0) [0|1] "" Vector__XXX
 SG_ PARK_sw048_linFrameCountError m48 : 18|1@1+ (1,0) [0|1] "" Vector__XXX
 SG_ PARK_sw049_reverbPeriod m49 : 16|16@1+ (1,0) [0|65535] "microseconds" Vector__XXX
 SG_ PARK_sw049_reverbTime m49 : 32|16@1+ (1,0) [0|65535] "microseconds" Vector__XXX
 SG_ PARK_sw049_highAttenTime m49 : 48|1@1+ (1,0) [0|1] "" Vector__XXX
 SG_ PARK_sw049_closeConstEcho m49 : 49|1@1+ (1,0) [0|1] "" Vector__XXX
 SG_ PARK_sw049_lowAttenTime m49 : 50|1@1+ (1,0) [0|1] "" Vector__XXX
 SG_ PARK_sw049_attenTimeJitter m49 : 51|1@1+ (1,0) [0|1] "" Vector__XXX
 SG_ PARK_sw049_reverbFreqJitter m49 : 52|1@1+ (1,0) [0|1] "" Vector__XXX
 SG_ PARK_sw051_sensorTemperature m51 : 16|16@1+ (0.1,-40) [-40|6513.5] "deg" Vector__XXX
 SG_ PARK_sw052_membraneDisconct m52 : 16|1@1+ (1,0) [0|1] "" Vector__XXX
 SG_ PARK_sw052_dampResistorFail m52 : 17|1@1+ (1,0) [0|1] "" Vector__XXX
 SG_ PARK_sw052_resonanceDrift m52 : 18|1@1+ (1,0) [0|1] "" Vector__XXX
 SG_ PARK_sw052_sensorCRC m52 : 19|1@1+ (1,0) [0|1] "" Vector__XXX
 SG_ PARK_sw052_recieveFailure m52 : 20|1@1+ (1,0) [0|1] "" Vector__XXX
 SG_ PARK_sw052_diagnosticTransferErr m52 : 21|1@1+ (1,0) [0|1] "" Vector__XXX
 SG_ PARK_sw053_linError m53 : 16|1@1+ (1,0) [0|1] "" Vector__XXX
 SG_ PARK_sw053_linBusError m53 : 17|1@1+ (1,0) [0|1] "" Vector__XXX
 SG_ PARK_sw053_linFrameCountError m53 : 18|1@1+ (1,0) [0|1] "" Vector__XXX
 SG_ PARK_sw054_reverbPeriod m54 : 16|16@1+ (1,0) [0|65535] "microseconds" Vector__XXX
 SG_ PARK_sw054_reverbTime m54 : 32|16@1+ (1,0) [0|65535] "microseconds" Vector__XXX
 SG_ PARK_sw054_highAttenTime m54 : 48|1@1+ (1,0) [0|1] "" Vector__XXX
 SG_ PARK_sw054_closeConstEcho m54 : 49|1@1+ (1,0) [0|1] "" Vector__XXX
 SG_ PARK_sw054_lowAttenTime m54 : 50|1@1+ (1,0) [0|1] "" Vector__XXX
 SG_ PARK_sw054_attenTimeJitter m54 : 51|1@1+ (1,0) [0|1] "" Vector__XXX
 SG_ PARK_sw054_reverbFreqJitter m54 : 52|1@1+ (1,0) [0|1] "" Vector__XXX
 SG_ PARK_sw056_sensorTemperature m56 : 16|16@1+ (0.1,-40) [-40|6513.5] "deg" Vector__XXX
 SG_ PARK_sw057_membraneDisconct m57 : 16|1@1+ (1,0) [0|1] "" Vector__XXX
 SG_ PARK_sw057_dampResistorFail m57 : 17|1@1+ (1,0) [0|1] "" Vector__XXX
 SG_ PARK_sw057_resonanceDrift m57 : 18|1@1+ (1,0) [0|1] "" Vector__XXX
 SG_ PARK_sw057_sensorCRC m57 : 19|1@1+ (1,0) [0|1] "" Vector__XXX
 SG_ PARK_sw057_recieveFailure m57 : 20|1@1+ (1,0) [0|1] "" Vector__XXX
 SG_ PARK_sw057_diagnosticTransferErr m57 : 21|1@1+ (1,0) [0|1] "" Vector__XXX
 SG_ PARK_sw058_linError m58 : 16|1@1+ (1,0) [0|1] "" Vector__XXX
 SG_ PARK_sw058_linBusError m58 : 17|1@1+ (1,0) [0|1] "" Vector__XXX
 SG_ PARK_sw058_linFrameCountError m58 : 18|1@1+ (1,0) [0|1] "" Vector__XXX
 SG_ PARK_sw059_reverbPeriod m59 : 16|16@1+ (1,0) [0|65535] "microseconds" Vector__XXX
 SG_ PARK_sw059_reverbTime m59 : 32|16@1+ (1,0) [0|65535] "microseconds" Vector__XXX
 SG_ PARK_sw059_highAttenTime m59 : 48|1@1+ (1,0) [0|1] "" Vector__XXX
 SG_ PARK_sw059_closeConstEcho m59 : 49|1@1+ (1,0) [0|1] "" Vector__XXX
 SG_ PARK_sw059_lowAttenTime m59 : 50|1@1+ (1,0) [0|1] "" Vector__XXX
 SG_ PARK_sw059_attenTimeJitter m59 : 51|1@1+ (1,0) [0|1] "" Vector__XXX
 SG_ PARK_sw059_reverbFreqJitter m59 : 52|1@1+ (1,0) [0|1] "" Vector__XXX
 SG_ PARK_sw061_voltage m61 : 16|16@1+ (0.1,0) [0|6553.5] "volts" Vector__XXX
 SG_ PARK_sw063_voltage m63 : 16|16@1+ (0.1,0) [0|6553.5] "volts" Vector__XXX
 SG_ PARK_sw064_faultCode m64 : 16|8@1+ (1,0) [0|255] "" Vector__XXX
 SG_ PARK_sw065_expectedCRC m65 : 16|16@1+ (1,0) [0|65535] "" Vector__XXX
 SG_ PARK_sw065_calculatedCRC m65 : 32|16@1+ (1,0) [0|65535] "" Vector__XXX
 SG_ PARK_sw066_placeHolder m66 : 16|1@1+ (1,0) [0|1] "" Vector__XXX
 SG_ PARK_sw068_placeHolder m68 : 16|1@1+ (1,0) [0|1] "" Vector__XXX
 SG_ PARK_sw069_messageID m69 : 16|16@1+ (1,0) [0|65535] "" Vector__XXX
 SG_ PARK_sw070_messageID m70 : 16|16@1+ (1,0) [0|65535] "" Vector__XXX
 SG_ PARK_sw071_messageID m71 : 16|16@1+ (1,0) [0|65535] "" Vector__XXX
 SG_ PARK_sw072_messageID m72 : 16|16@1+ (1,0) [0|65535] "" Vector__XXX
 SG_ PARK_sw073_messageID m73 : 16|16@1+ (1,0) [0|65535] "" Vector__XXX
 SG_ PARK_sw074_messageID m74 : 16|16@1+ (1,0) [0|65535] "" Vector__XXX
 SG_ PARK_sw075_messageID m75 : 16|16@1+ (1,0) [0|65535] "" Vector__XXX
 SG_ PARK_sw076_messageID m76 : 16|16@1+ (1,0) [0|65535] "" Vector__XXX
 SG_ PARK_sw077_errorExp m77 : 16|8@1+ (1,0) [0|255] "" Vector__XXX
 SG_ PARK_sw077_errorRx m77 : 24|8@1+ (1,0) [0|255] "" Vector__XXX
 SG_ PARK_sw077_messageID m77 : 32|12@1+ (1,0) [0|4095] "" Vector__XXX
 SG_ PARK_sw077_errorType m77 : 44|3@1+ (1,0) [0|7] "" Vector__XXX
 SG_ PARK_sw078_errorExp m78 : 16|8@1+ (1,0) [0|255] "" Vector__XXX
 SG_ PARK_sw078_errorRx m78 : 24|8@1+ (1,0) [0|255] "" Vector__XXX
 SG_ PARK_sw078_messageID m78 : 32|12@1+ (1,0) [0|4095] "" Vector__XXX
 SG_ PARK_sw078_errorType m78 : 44|3@1+ (1,0) [0|7] "" Vector__XXX
 SG_ PARK_sw079_errorExp m79 : 16|8@1+ (1,0) [0|255] "" Vector__XXX
 SG_ PARK_sw079_errorRx m79 : 24|8@1+ (1,0) [0|255] "" Vector__XXX
 SG_ PARK_sw079_messageID m79 : 32|12@1+ (1,0) [0|4095] "" Vector__XXX
 SG_ PARK_sw079_errorType m79 : 44|3@1+ (1,0) [0|7] "" Vector__XXX
 SG_ PARK_sw080_errorExp m80 : 16|8@1+ (1,0) [0|255] "" Vector__XXX
 SG_ PARK_sw080_errorRx m80 : 24|8@1+ (1,0) [0|255] "" Vector__XXX
 SG_ PARK_sw080_messageID m80 : 32|12@1+ (1,0) [0|4095] "" Vector__XXX
 SG_ PARK_sw080_errorType m80 : 44|3@1+ (1,0) [0|7] "" Vector__XXX
 SG_ PARK_sw081_errorExp m81 : 16|8@1+ (1,0) [0|255] "" Vector__XXX
 SG_ PARK_sw081_errorRx m81 : 24|8@1+ (1,0) [0|255] "" Vector__XXX
 SG_ PARK_sw081_messageID m81 : 32|12@1+ (1,0) [0|4095] "" Vector__XXX
 SG_ PARK_sw081_errorType m81 : 44|3@1+ (1,0) [0|7] "" Vector__XXX
 SG_ PARK_sw082_errorExp m82 : 16|8@1+ (1,0) [0|255] "" Vector__XXX
 SG_ PARK_sw082_errorRx m82 : 24|8@1+ (1,0) [0|255] "" Vector__XXX
 SG_ PARK_sw082_messageID m82 : 32|12@1+ (1,0) [0|4095] "" Vector__XXX
 SG_ PARK_sw082_errorType m82 : 44|3@1+ (1,0) [0|7] "" Vector__XXX
 SG_ PARK_sw083_errorExp m83 : 16|8@1+ (1,0) [0|255] "" Vector__XXX
 SG_ PARK_sw083_errorRx m83 : 24|8@1+ (1,0) [0|255] "" Vector__XXX
 SG_ PARK_sw083_messageID m83 : 32|12@1+ (1,0) [0|4095] "" Vector__XXX
 SG_ PARK_sw083_errorType m83 : 44|3@1+ (1,0) [0|7] "" Vector__XXX
 SG_ PARK_sw084_errorExp m84 : 16|8@1+ (1,0) [0|255] "" Vector__XXX
 SG_ PARK_sw084_errorRx m84 : 24|8@1+ (1,0) [0|255] "" Vector__XXX
 SG_ PARK_sw084_messageID m84 : 32|12@1+ (1,0) [0|4095] "" Vector__XXX
 SG_ PARK_sw084_errorType m84 : 44|3@1+ (1,0) [0|7] "" Vector__XXX
 SG_ PARK_sw086_writeRetryCounter m86 : 16|8@1+ (1,0) [0|255] "" Vector__XXX
 SG_ PARK_sw086_readRetryCounter m86 : 24|8@1+ (1,0) [0|255] "" Vector__XXX
 SG_ PARK_sw086_currentErrorCode m86 : 32|8@1+ (1,0) [0|255] "" Vector__XXX
 SG_ PARK_sw087_s1_sensorType m87 : 16|2@1+ (1,0) [0|2] "" Vector__XXX
 SG_ PARK_sw087_s2_sensorType m87 : 18|2@1+ (1,0) [0|2] "" Vector__XXX
 SG_ PARK_sw087_s3_sensorType m87 : 20|2@1+ (1,0) [0|2] "" Vector__XXX
 SG_ PARK_sw087_s4_sensorType m87 : 22|2@1+ (1,0) [0|2] "" Vector__XXX
 SG_ PARK_sw087_s5_sensorType m87 : 24|2@1+ (1,0) [0|2] "" Vector__XXX
 SG_ PARK_sw087_s6_sensorType m87 : 26|2@1+ (1,0) [0|2] "" Vector__XXX
 SG_ PARK_sw087_s7_sensorType m87 : 28|2@1+ (1,0) [0|2] "" Vector__XXX
 SG_ PARK_sw087_s8_sensorType m87 : 30|2@1+ (1,0) [0|2] "" Vector__XXX
 SG_ PARK_sw087_s9_sensorType m87 : 32|2@1+ (1,0) [0|2] "" Vector__XXX
 SG_ PARK_sw087_s10_sensorType m87 : 34|2@1+ (1,0) [0|2] "" Vector__XXX
 SG_ PARK_sw087_s11_sensorType m87 : 36|2@1+ (1,0) [0|2] "" Vector__XXX
 SG_ PARK_sw087_s12_sensorType m87 : 38|2@1+ (1,0) [0|2] "" Vector__XXX

BO_ 806 PARK_info: 8 PARK
 SG_ PARK_infoIndex M : 0|8@1+ (1,0) [0|255] "" Vector__XXX
 SG_ PARK_infoBuildType m10 : 8|8@1+ (1,0) [0|255] "" Vector__XXX
 SG_ PARK_infoComponentID m10 : 48|16@1+ (1,0) [0|65535] "" Vector__XXX
 SG_ PARK_infoPcbaID m11 : 16|8@1+ (1,0) [0|255] "" Vector__XXX
 SG_ PARK_infoAssemblyID m11 : 24|8@1+ (1,0) [0|255] "" Vector__XXX
 SG_ PARK_infoUsageID m11 : 32|16@1+ (1,0) [0|65535] "" Vector__XXX
 SG_ PARK_infoApplicationCRC m13 : 32|32@1+ (1,0) [0|4294967295] "" Vector__XXX
 SG_ PARK_infoBootUdsProtoVersion m20 : 8|8@1+ (1,0) [0|255] "" Vector__XXX
 SG_ PARK_infoBootloaderCRC m20 : 32|32@1+ (1,0) [0|4294967295] "" Vector__XXX

BO_ 846 PARK_pasFrontMiddle: 5 PARK
 SG_ PARK_frontLeftMiddleRawDistData : 0|8@1+ (1,0) [0|254] "cm" Vector__XXX
 SG_ PARK_frontMiddleRawDistData : 8|8@1+ (1,0) [0|254] "cm" Vector__XXX
 SG_ PARK_frontRightMiddleRawDistData : 16|8@1+ (1,0) [0|254] "cm" Vector__XXX
 SG_ PARK_pasFrontMiddleCounter : 24|4@1+ (1,0) [0|15] "" Vector__XXX
 SG_ PARK_pasFrontMiddleChecksum : 32|8@1+ (1,0) [0|255] "" Vector__XXX

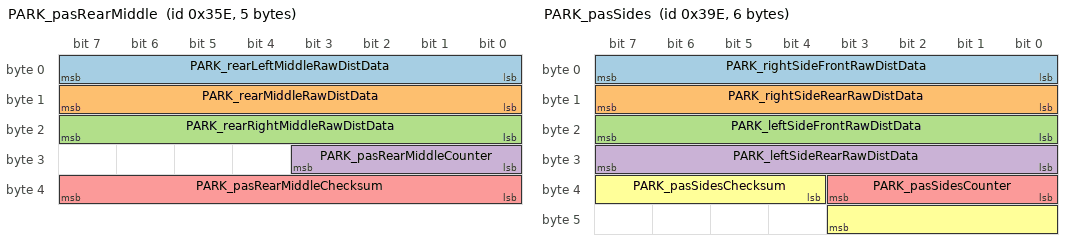
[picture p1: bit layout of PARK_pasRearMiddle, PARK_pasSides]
BO_ 862 PARK_pasRearMiddle: 5 PARK
 SG_ PARK_rearLeftMiddleRawDistData : 0|8@1+ (1,0) [0|254] "cm" Vector__XXX
 SG_ PARK_rearMiddleRawDistData : 8|8@1+ (1,0) [0|254] "cm" Vector__XXX
 SG_ PARK_rearRightMiddleRawDistData : 16|8@1+ (1,0) [0|254] "cm" Vector__XXX
 SG_ PARK_pasRearMiddleCounter : 24|4@1+ (1,0) [0|15] "" Vector__XXX
 SG_ PARK_pasRearMiddleChecksum : 32|8@1+ (1,0) [0|255] "" Vector__XXX

BO_ 926 PARK_pasSides: 6 PARK
 SG_ PARK_rightSideFrontRawDistData : 0|8@1+ (1,0) [0|254] "cm" Vector__XXX
 SG_ PARK_rightSideRearRawDistData : 8|8@1+ (1,0) [0|254] "cm" Vector__XXX
 SG_ PARK_leftSideFrontRawDistData : 16|8@1+ (1,0) [0|254] "cm" Vector__XXX
 SG_ PARK_leftSideRearRawDistData : 24|8@1+ (1,0) [0|254] "cm" Vector__XXX
 SG_ PARK_pasSidesCounter : 32|4@1+ (1,0) [0|15] "" Vector__XXX
 SG_ PARK_pasSidesChecksum : 36|8@1+ (1,0) [0|255] "" Vector__XXX

BO_ 606 PARK_pscEnvSlot: 8 PARK
 SG_ PARK_pscEnvSlotType M : 0|2@1+ (1,0) [0|3] "" Vector__XXX
 SG_ PARK_pscLeftParallelObj1X m0 : 3|11@1+ (2,-2048) [-2048|2044] "cm" Vector__XXX
 SG_ PARK_pscLeftParallelObj1Y m0 : 14|11@1+ (2,-2048) [-2048|2044] "cm" Vector__XXX
 SG_ PARK_pscLeftParallelObj1Alpha m0 : 25|7@1+ (2,-128) [-128|124] "deg" Vector__XXX
 SG_ PARK_pscLeftParallelObj2Y m0 : 35|11@1+ (2,-2048) [-2048|2044] "cm" Vector__XXX
 SG_ PARK_pscLeftParallelObj2X m0 : 46|11@1+ (2,-2048) [-2048|2044] "cm" Vector__XXX
 SG_ PARK_pscLeftParallelObj2Alpha m0 : 57|7@1+ (2,-128) [-128|124] "deg" Vector__XXX
 SG_ PARK_pscLeftCrossObj1X m1 : 3|11@1+ (2,-2048) [-2048|2044] "cm" Vector__XXX
 SG_ PARK_pscLeftCrossObj1Y m1 : 14|11@1+ (2,-2048) [-2048|2044] "cm" Vector__XXX
 SG_ PARK_pscLeftCrossObj1Alpha m1 : 25|7@1+ (2,-128) [-128|124] "deg" Vector__XXX
 SG_ PARK_pscLeftCrossObj2Y m1 : 35|11@1+ (2,-2048) [-2048|2044] "cm" Vector__XXX
 SG_ PARK_pscLeftCrossObj2X m1 : 46|11@1+ (2,-2048) [-2048|2044] "cm" Vector__XXX
 SG_ PARK_pscLeftCrossObj2Alpha m1 : 57|7@1+ (2,-128) [-128|124] "deg" Vector__XXX
 SG_ PARK_pscRightParallelObj1X m2 : 3|11@1+ (2,-2048) [-2048|2044] "cm" Vector__XXX
 SG_ PARK_pscRightParallelObj1Y m2 : 14|11@1+ (2,-2048) [-2048|2044] "cm" Vector__XXX
 SG_ PARK_pscRightParallelObj1Alpha m2 : 25|7@1+ (2,-128) [-128|124] "deg" Vector__XXX
 SG_ PARK_pscRightParallelObj2Y m2 : 35|11@1+ (2,-2048) [-2048|2044] "cm" Vector__XXX
 SG_ PARK_pscRightParallelObj2X m2 : 46|11@1+ (2,-2048) [-2048|2044] "cm" Vector__XXX
 SG_ PARK_pscRightParallelObj2Alpha m2 : 57|7@1+ (2,-128) [-128|124] "deg" Vector__XXX
 SG_ PARK_pscRightCrossObj1X m3 : 3|11@1+ (2,-2048) [-2048|2044] "cm" Vector__XXX
 SG_ PARK_pscRightCrossObj1Y m3 : 14|11@1+ (2,-2048) [-2048|2044] "cm" Vector__XXX
 SG_ PARK_pscRightCrossObj1Alpha m3 : 25|7@1+ (2,-128) [-128|124] "deg" Vector__XXX
 SG_ PARK_pscRightCrossObj2Y m3 : 35|11@1+ (2,-2048) [-2048|2044] "cm" Vector__XXX
 SG_ PARK_pscRightCrossObj2X m3 : 46|11@1+ (2,-2048) [-2048|2044] "cm" Vector__XXX
 SG_ PARK_pscRightCrossObj2Alpha m3 : 57|7@1+ (2,-128) [-128|124] "deg" Vector__XXX

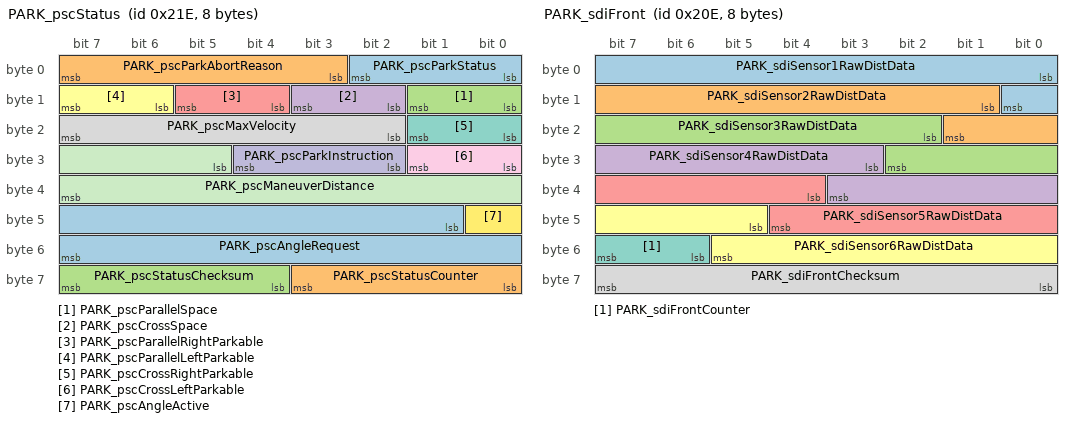
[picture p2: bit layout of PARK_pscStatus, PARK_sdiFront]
BO_ 542 PARK_pscStatus: 8 PARK
 SG_ PARK_pscParkStatus : 0|3@1+ (1,0) [0|6] "" Vector__XXX
 SG_ PARK_pscParkAbortReason : 3|5@1+ (1,0) [0|30] "" Vector__XXX
 SG_ PARK_pscParallelSpace : 8|2@1+ (1,0) [0|3] "" Vector__XXX
 SG_ PARK_pscCrossSpace : 10|2@1+ (1,0) [0|3] "" Vector__XXX
 SG_ PARK_pscParallelRightParkable : 12|2@1+ (1,0) [0|2] "" Vector__XXX
 SG_ PARK_pscParallelLeftParkable : 14|2@1+ (1,0) [0|2] "" Vector__XXX
 SG_ PARK_pscCrossRightParkable : 16|2@1+ (1,0) [0|2] "" Vector__XXX
 SG_ PARK_pscMaxVelocity : 18|6@1+ (0.1,0) [0|6.2] "kph" Vector__XXX
 SG_ PARK_pscCrossLeftParkable : 24|2@1+ (1,0) [0|2] "" Vector__XXX
 SG_ PARK_pscParkInstruction : 26|3@1+ (1,0) [0|6] "" Vector__XXX
 SG_ PARK_pscManeuverDistance : 29|11@1+ (1,0) [0|2046] "cm" Vector__XXX
 SG_ PARK_pscAngleActive : 40|1@1+ (1,0) [0|1] "" Vector__XXX
 SG_ PARK_pscAngleRequest : 41|15@1+ (0.1,-1638.4) [-1638.4|1638.3] "deg" Vector__XXX
 SG_ PARK_pscStatusCounter : 56|4@1+ (1,0) [0|15] "" Vector__XXX
 SG_ PARK_pscStatusChecksum : 60|4@1+ (1,0) [0|15] "" Vector__XXX

BO_ 590 PARK_pscVehSlot: 8 PARK
 SG_ PARK_pscVehSlotType M : 0|2@1+ (1,0) [0|3] "" Vector__XXX
 SG_ PARK_pscLeftParallelVehX m0 : 5|11@1+ (2,-2048) [-2048|2044] "cm" Vector__XXX
 SG_ PARK_pscLeftParallelVehY m0 : 16|11@1+ (2,-2048) [-2048|2044] "cm" Vector__XXX
 SG_ PARK_pscLeftParallelPsi m0 : 32|13@1+ (0.0009765625,0) [0|7.998046875] "radians" Vector__XXX
 SG_ PARK_pscLeftParallelSizeX m0 : 48|8@1+ (4,0) [0|1016] "cm" Vector__XXX
 SG_ PARK_pscLeftParallelSizeY m0 : 56|8@1+ (4,0) [0|1016] "cm" Vector__XXX
 SG_ PARK_pscLeftCrossVehX m1 : 5|11@1+ (2,-2048) [-2048|2044] "cm" Vector__XXX
 SG_ PARK_pscLeftCrossVehY m1 : 16|11@1+ (2,-2048) [-2048|2044] "cm" Vector__XXX
 SG_ PARK_pscLeftCrossPsi m1 : 32|13@1+ (0.0009765625,0) [0|7.998046875] "radians" Vector__XXX
 SG_ PARK_pscLeftCrossSizeX m1 : 48|8@1+ (4,0) [0|1016] "cm" Vector__XXX
 SG_ PARK_pscLeftCrossSizeY m1 : 56|8@1+ (4,0) [0|1016] "cm" Vector__XXX
 SG_ PARK_pscRightParallelVehX m2 : 5|11@1+ (2,-2048) [-2048|2044] "cm" Vector__XXX
 SG_ PARK_pscRightParallelVehY m2 : 16|11@1+ (2,-2048) [-2048|2044] "cm" Vector__XXX
 SG_ PARK_pscRightParallelPsi m2 : 32|13@1+ (0.0009765625,0) [0|7.998046875] "radians" Vector__XXX
 SG_ PARK_pscRightParallelSizeX m2 : 48|8@1+ (4,0) [0|1016] "cm" Vector__XXX
 SG_ PARK_pscRightParallelSizeY m2 : 56|8@1+ (4,0) [0|1016] "cm" Vector__XXX
 SG_ PARK_pscRightCrossVehX m3 : 5|11@1+ (2,-2048) [-2048|2044] "cm" Vector__XXX
 SG_ PARK_pscRightCrossVehY m3 : 16|11@1+ (2,-2048) [-2048|2044] "cm" Vector__XXX
 SG_ PARK_pscRightCrossPsi m3 : 32|13@1+ (0.0009765625,0) [0|7.998046875] "radians" Vector__XXX
 SG_ PARK_pscRightCrossSizeX m3 : 48|8@1+ (4,0) [0|1016] "cm" Vector__XXX
 SG_ PARK_pscRightCrossSizeY m3 : 56|8@1+ (4,0) [0|1016] "cm" Vector__XXX

BO_ 526 PARK_sdiFront: 8 PARK
 SG_ PARK_sdiSensor1RawDistData : 0|9@1+ (1,0) [0|510] "cm" Vector__XXX
 SG_ PARK_sdiSensor2RawDistData : 9|9@1+ (1,0) [0|510] "cm" Vector__XXX
 SG_ PARK_sdiSensor3RawDistData : 18|9@1+ (1,0) [0|510] "cm" Vector__XXX
 SG_ PARK_sdiSensor4RawDistData : 27|9@1+ (1,0) [0|510] "cm" Vector__XXX
 SG_ PARK_sdiSensor5RawDistData : 36|9@1+ (1,0) [0|510] "cm" Vector__XXX
 SG_ PARK_sdiSensor6RawDistData : 45|9@1+ (1,0) [0|510] "cm" Vector__XXX
 SG_ PARK_sdiFrontCounter : 54|2@1+ (1,0) [0|3] "" Vector__XXX
 SG_ PARK_sdiFrontChecksum : 56|8@1+ (1,0) [0|255] "" Vector__XXX

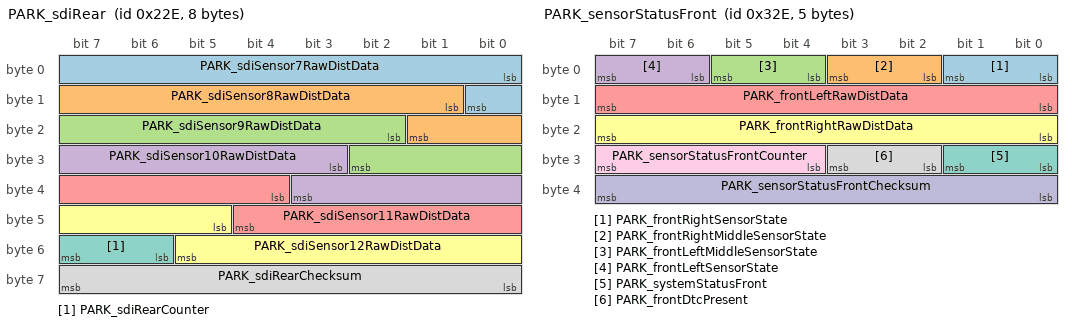
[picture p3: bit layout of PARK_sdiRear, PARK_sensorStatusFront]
BO_ 558 PARK_sdiRear: 8 PARK
 SG_ PARK_sdiSensor7RawDistData : 0|9@1+ (1,0) [0|510] "cm" Vector__XXX
 SG_ PARK_sdiSensor8RawDistData : 9|9@1+ (1,0) [0|510] "cm" Vector__XXX
 SG_ PARK_sdiSensor9RawDistData : 18|9@1+ (1,0) [0|510] "cm" Vector__XXX
 SG_ PARK_sdiSensor10RawDistData : 27|9@1+ (1,0) [0|510] "cm" Vector__XXX
 SG_ PARK_sdiSensor11RawDistData : 36|9@1+ (1,0) [0|510] "cm" Vector__XXX
 SG_ PARK_sdiSensor12RawDistData : 45|9@1+ (1,0) [0|510] "cm" Vector__XXX
 SG_ PARK_sdiRearCounter : 54|2@1+ (1,0) [0|3] "" Vector__XXX
 SG_ PARK_sdiRearChecksum : 56|8@1+ (1,0) [0|255] "" Vector__XXX

BO_ 814 PARK_sensorStatusFront: 5 PARK
 SG_ PARK_frontRightSensorState : 0|2@1+ (1,0) [0|2] "" Vector__XXX
 SG_ PARK_frontRightMiddleSensorState : 2|2@1+ (1,0) [0|2] "" Vector__XXX
 SG_ PARK_frontLeftMiddleSensorState : 4|2@1+ (1,0) [0|2] "" Vector__XXX
 SG_ PARK_frontLeftSensorState : 6|2@1+ (1,0) [0|2] "" Vector__XXX
 SG_ PARK_frontLeftRawDistData : 8|8@1+ (1,0) [0|254] "cm" Vector__XXX
 SG_ PARK_frontRightRawDistData : 16|8@1+ (1,0) [0|254] "cm" Vector__XXX
 SG_ PARK_systemStatusFront : 24|2@1+ (1,0) [0|2] "" Vector__XXX
 SG_ PARK_frontDtcPresent : 26|2@1+ (1,0) [0|2] "" Vector__XXX
 SG_ PARK_sensorStatusFrontCounter : 28|4@1+ (1,0) [0|15] "" Vector__XXX
 SG_ PARK_sensorStatusFrontChecksum : 32|8@1+ (1,0) [0|255] "" Vector__XXX

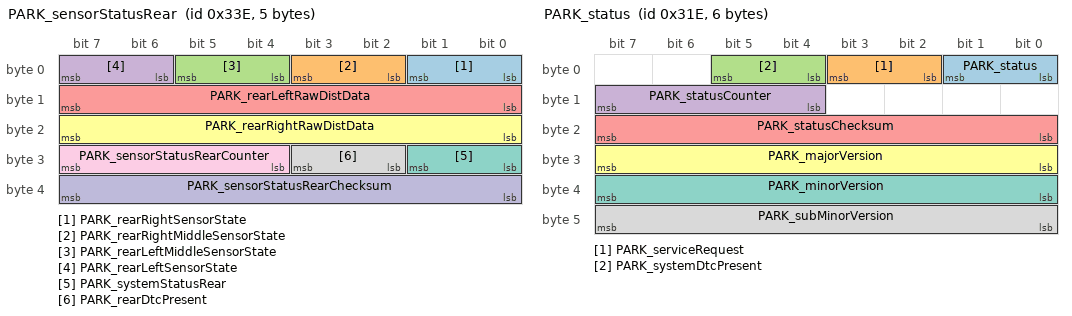
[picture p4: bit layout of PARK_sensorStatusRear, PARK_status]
BO_ 830 PARK_sensorStatusRear: 5 PARK
 SG_ PARK_rearRightSensorState : 0|2@1+ (1,0) [0|2] "" Vector__XXX
 SG_ PARK_rearRightMiddleSensorState : 2|2@1+ (1,0) [0|2] "" Vector__XXX
 SG_ PARK_rearLeftMiddleSensorState : 4|2@1+ (1,0) [0|2] "" Vector__XXX
 SG_ PARK_rearLeftSensorState : 6|2@1+ (1,0) [0|2] "" Vector__XXX
 SG_ PARK_rearLeftRawDistData : 8|8@1+ (1,0) [0|254] "cm" Vector__XXX
 SG_ PARK_rearRightRawDistData : 16|8@1+ (1,0) [0|254] "cm" Vector__XXX
 SG_ PARK_systemStatusRear : 24|2@1+ (1,0) [0|2] "" Vector__XXX
 SG_ PARK_rearDtcPresent : 26|2@1+ (1,0) [0|2] "" Vector__XXX
 SG_ PARK_sensorStatusRearCounter : 28|4@1+ (1,0) [0|15] "" Vector__XXX
 SG_ PARK_sensorStatusRearChecksum : 32|8@1+ (1,0) [0|255] "" Vector__XXX

BO_ 798 PARK_status: 6 PARK
 SG_ PARK_status : 0|2@1+ (1,0) [0|2] "" Vector__XXX
 SG_ PARK_serviceRequest : 2|2@1+ (1,0) [0|2] "" Vector__XXX
 SG_ PARK_systemDtcPresent : 4|2@1+ (1,0) [0|2] "" Vector__XXX
 SG_ PARK_statusCounter : 12|4@1+ (1,0) [0|15] "" Vector__XXX
 SG_ PARK_statusChecksum : 16|8@1+ (1,0) [0|255] "" Vector__XXX
 SG_ PARK_majorVersion : 24|8@1+ (1,0) [0|254] "" Vector__XXX
 SG_ PARK_minorVersion : 32|8@1+ (1,0) [0|254] "" Vector__XXX
 SG_ PARK_subMinorVersion : 40|8@1+ (1,0) [0|254] "" Vector__XXX

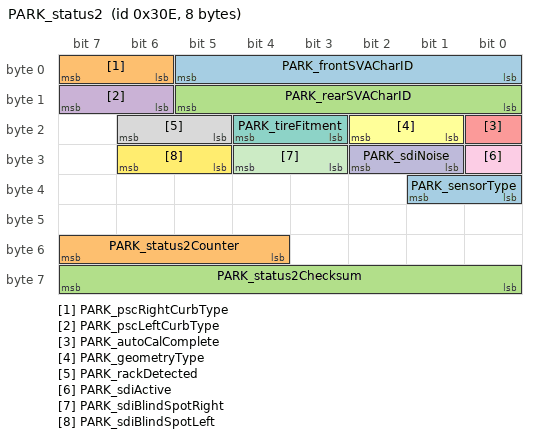
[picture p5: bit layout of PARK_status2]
BO_ 782 PARK_status2: 8 PARK
 SG_ PARK_frontSVACharID : 0|6@1+ (1,0) [0|63] "" Vector__XXX
 SG_ PARK_pscRightCurbType : 6|2@1+ (1,0) [0|3] "" Vector__XXX
 SG_ PARK_rearSVACharID : 8|6@1+ (1,0) [0|63] "" Vector__XXX
 SG_ PARK_pscLeftCurbType : 14|2@1+ (1,0) [0|3] "" Vector__XXX
 SG_ PARK_autoCalComplete : 16|1@1+ (1,0) [0|1] "" Vector__XXX
 SG_ PARK_geometryType : 17|2@1+ (1,0) [0|3] "" Vector__XXX
 SG_ PARK_tireFitment : 19|2@1+ (1,0) [0|2] "" Vector__XXX
 SG_ PARK_rackDetected : 21|2@1+ (1,0) [0|2] "" Vector__XXX
 SG_ PARK_sdiActive : 24|1@1+ (1,0) [0|1] "" Vector__XXX
 SG_ PARK_sdiNoise : 25|2@1+ (1,0) [0|2] "" Vector__XXX
 SG_ PARK_sdiBlindSpotRight : 27|2@1+ (1,0) [0|2] "" Vector__XXX
 SG_ PARK_sdiBlindSpotLeft : 29|2@1+ (1,0) [0|2] "" Vector__XXX
 SG_ PARK_sensorType : 32|2@1+ (1,0) [0|2] "" Vector__XXX
 SG_ PARK_status2Counter : 52|4@1+ (1,0) [0|15] "" Vector__XXX
 SG_ PARK_status2Checksum : 56|8@1+ (1,0) [0|255] "" Vector__XXX

BO_ 894 PARK_warningMatrix: 8 PARK
 SG_ PARK_matrixIndex M : 0|4@1+ (1,0) [0|15] "" Vector__XXX
 SG_ PARK_a001_s1_overTemp m0 : 4|1@1+ (1,0) [0|1] "" Vector__XXX
 SG_ PARK_a002_s1_internalFail m0 : 5|1@1+ (1,0) [0|1] "" Vector__XXX
 SG_ PARK_a003_s1_linCommError m0 : 6|1@1+ (1,0) [0|1] "" Vector__XXX
 SG_ PARK_a004_s1_blocked m0 : 7|1@1+ (1,0) [0|1] "" Vector__XXX
 SG_ PARK_a005_s1_crossTalk m0 : 8|1@1+ (1,0) [0|1] "" Vector__XXX
 SG_ PARK_a006_s2_overTemp m0 : 9|1@1+ (1,0) [0|1] "" Vector__XXX
 SG_ PARK_a007_s2_internalFail m0 : 10|1@1+ (1,0) [0|1] "" Vector__XXX
 SG_ PARK_a008_s2_linCommError m0 : 11|1@1+ (1,0) [0|1] "" Vector__XXX
 SG_ PARK_a009_s2_blocked m0 : 12|1@1+ (1,0) [0|1] "" Vector__XXX
 SG_ PARK_a010_s2_crossTalk m0 : 13|1@1+ (1,0) [0|1] "" Vector__XXX
 SG_ PARK_a011_s3_overTemp m0 : 14|1@1+ (1,0) [0|1] "" Vector__XXX
 SG_ PARK_a012_s3_internalFail m0 : 15|1@1+ (1,0) [0|1] "" Vector__XXX
 SG_ PARK_a013_s3_linCommError m0 : 16|1@1+ (1,0) [0|1] "" Vector__XXX
 SG_ PARK_a014_s3_blocked m0 : 17|1@1+ (1,0) [0|1] "" Vector__XXX
 SG_ PARK_a015_s3_crossTalk m0 : 18|1@1+ (1,0) [0|1] "" Vector__XXX
 SG_ PARK_a016_s4_overTemp m0 : 19|1@1+ (1,0) [0|1] "" Vector__XXX
 SG_ PARK_a017_s4_internalFail m0 : 20|1@1+ (1,0) [0|1] "" Vector__XXX
 SG_ PARK_a018_s4_linCommError m0 : 21|1@1+ (1,0) [0|1] "" Vector__XXX
 SG_ PARK_a019_s4_blocked m0 : 22|1@1+ (1,0) [0|1] "" Vector__XXX
 SG_ PARK_a020_s4_crossTalk m0 : 23|1@1+ (1,0) [0|1] "" Vector__XXX
 SG_ PARK_a021_s5_overTemp m0 : 24|1@1+ (1,0) [0|1] "" Vector__XXX
 SG_ PARK_a022_s5_internalFail m0 : 25|1@1+ (1,0) [0|1] "" Vector__XXX
 SG_ PARK_a023_s5_linCommError m0 : 26|1@1+ (1,0) [0|1] "" Vector__XXX
 SG_ PARK_a024_s5_blocked m0 : 27|1@1+ (1,0) [0|1] "" Vector__XXX
 SG_ PARK_a025_s5_crossTalk m0 : 28|1@1+ (1,0) [0|1] "" Vector__XXX
 SG_ PARK_a026_s6_overTemp m0 : 29|1@1+ (1,0) [0|1] "" Vector__XXX
 SG_ PARK_a027_s6_internalFail m0 : 30|1@1+ (1,0) [0|1] "" Vector__XXX
 SG_ PARK_a028_s6_linCommError m0 : 31|1@1+ (1,0) [0|1] "" Vector__XXX
 SG_ PARK_a029_s6_blocked m0 : 32|1@1+ (1,0) [0|1] "" Vector__XXX
 SG_ PARK_a030_s6_crossTalk m0 : 33|1@1+ (1,0) [0|1] "" Vector__XXX
 SG_ PARK_a031_s7_overTemp m0 : 34|1@1+ (1,0) [0|1] "" Vector__XXX
 SG_ PARK_a032_s7_internalFail m0 : 35|1@1+ (1,0) [0|1] "" Vector__XXX
 SG_ PARK_a033_s7_linCommError m0 : 36|1@1+ (1,0) [0|1] "" Vector__XXX
 SG_ PARK_a034_s7_blocked m0 : 37|1@1+ (1,0) [0|1] "" Vector__XXX
 SG_ PARK_a035_s7_crossTalk m0 : 38|1@1+ (1,0) [0|1] "" Vector__XXX
 SG_ PARK_a036_s8_overTemp m0 : 39|1@1+ (1,0) [0|1] "" Vector__XXX
 SG_ PARK_a037_s8_internalFail m0 : 40|1@1+ (1,0) [0|1] "" Vector__XXX
 SG_ PARK_a038_s8_linCommError m0 : 41|1@1+ (1,0) [0|1] "" Vector__XXX
 SG_ PARK_a039_s8_blocked m0 : 42|1@1+ (1,0) [0|1] "" Vector__XXX
 SG_ PARK_a040_s8_crossTalk m0 : 43|1@1+ (1,0) [0|1] "" Vector__XXX
 SG_ PARK_a041_s9_overTemp m0 : 44|1@1+ (1,0) [0|1] "" Vector__XXX
 SG_ PARK_a042_s9_internalFail m0 : 45|1@1+ (1,0) [0|1] "" Vector__XXX
 SG_ PARK_a043_s9_linCommError m0 : 46|1@1+ (1,0) [0|1] "" Vector__XXX
 SG_ PARK_a044_s9_blocked m0 : 47|1@1+ (1,0) [0|1] "" Vector__XXX
 SG_ PARK_a045_s9_crossTalk m0 : 48|1@1+ (1,0) [0|1] "" Vector__XXX
 SG_ PARK_a046_s10_overTemp m0 : 49|1@1+ (1,0) [0|1] "" Vector__XXX
 SG_ PARK_a047_s10_internalFail m0 : 50|1@1+ (1,0) [0|1] "" Vector__XXX
 SG_ PARK_a048_s10_linCommError m0 : 51|1@1+ (1,0) [0|1] "" Vector__XXX
 SG_ PARK_a049_s10_blocked m0 : 52|1@1+ (1,0) [0|1] "" Vector__XXX
 SG_ PARK_a050_s10_crossTalk m0 : 53|1@1+ (1,0) [0|1] "" Vector__XXX
 SG_ PARK_a051_s11_overTemp m0 : 54|1@1+ (1,0) [0|1] "" Vector__XXX
 SG_ PARK_a052_s11_internalFail m0 : 55|1@1+ (1,0) [0|1] "" Vector__XXX
 SG_ PARK_a053_s11_linCommError m0 : 56|1@1+ (1,0) [0|1] "" Vector__XXX
 SG_ PARK_a054_s11_blocked m0 : 57|1@1+ (1,0) [0|1] "" Vector__XXX
 SG_ PARK_a055_s11_crossTalk m0 : 58|1@1+ (1,0) [0|1] "" Vector__XXX
 SG_ PARK_a056_s12_overTemp m0 : 59|1@1+ (1,0) [0|1] "" Vector__XXX
 SG_ PARK_a057_s12_internalFail m0 : 60|1@1+ (1,0) [0|1] "" Vector__XXX
 SG_ PARK_a058_s12_linCommError m0 : 61|1@1+ (1,0) [0|1] "" Vector__XXX
 SG_ PARK_a059_s12_blocked m0 : 62|1@1+ (1,0) [0|1] "" Vector__XXX
 SG_ PARK_a060_s12_crossTalk m0 : 63|1@1+ (1,0) [0|1] "" Vector__XXX
 SG_ PARK_a061_ecuUnderVoltage m1 : 4|1@1+ (1,0) [0|1] "" Vector__XXX
 SG_ PARK_a062_ecuOverVoltage m1 : 5|1@1+ (1,0) [0|1] "" Vector__XXX
 SG_ PARK_a063_sensorVoltage m1 : 6|1@1+ (1,0) [0|1] "" Vector__XXX
 SG_ PARK_a064_ecuFault m1 : 7|1@1+ (1,0) [0|1] "" Vector__XXX
 SG_ PARK_a065_crcFault m1 : 8|1@1+ (1,0) [0|1] "" Vector__XXX
 SG_ PARK_a066_calibrationMissing m1 : 9|1@1+ (1,0) [0|1] "" Vector__XXX
 SG_ PARK_a067_privateCANBusOff m1 : 10|1@1+ (1,0) [0|1] "" Vector__XXX
 SG_ PARK_a068_hardwareWatchDog m1 : 11|1@1+ (1,0) [0|1] "" Vector__XXX
 SG_ PARK_a069_dasMia m1 : 12|1@1+ (1,0) [0|1] "" Vector__XXX
 SG_ PARK_a070_sccmMia m1 : 13|1@1+ (1,0) [0|1] "" Vector__XXX
 SG_ PARK_a071_diMia m1 : 14|1@1+ (1,0) [0|1] "" Vector__XXX
 SG_ PARK_a072_epasMia m1 : 15|1@1+ (1,0) [0|1] "" Vector__XXX
 SG_ PARK_a073_epbMia m1 : 16|1@1+ (1,0) [0|1] "" Vector__XXX
 SG_ PARK_a074_espMia m1 : 17|1@1+ (1,0) [0|1] "" Vector__XXX
 SG_ PARK_a075_rcmMia m1 : 18|1@1+ (1,0) [0|1] "" Vector__XXX
 SG_ PARK_a076_vcFrontMia m1 : 19|1@1+ (1,0) [0|1] "" Vector__XXX
 SG_ PARK_a077_dasError m1 : 20|1@1+ (1,0) [0|1] "" Vector__XXX
 SG_ PARK_a078_diError m1 : 21|1@1+ (1,0) [0|1] "" Vector__XXX
 SG_ PARK_a079_epasError m1 : 22|1@1+ (1,0) [0|1] "" Vector__XXX
 SG_ PARK_a080_epbError m1 : 23|1@1+ (1,0) [0|1] "" Vector__XXX
 SG_ PARK_a081_espError m1 : 24|1@1+ (1,0) [0|1] "" Vector__XXX
 SG_ PARK_a082_rcmError m1 : 25|1@1+ (1,0) [0|1] "" Vector__XXX
 SG_ PARK_a083_vcFrontError m1 : 26|1@1+ (1,0) [0|1] "" Vector__XXX
 SG_ PARK_a084_sccmError m1 : 27|1@1+ (1,0) [0|1] "" Vector__XXX
 SG_ PARK_a085_watchdogReset m1 : 28|1@1+ (1,0) [0|1] "" Vector__XXX
 SG_ PARK_a086_nvmFault m1 : 29|1@1+ (1,0) [0|1] "" Vector__XXX
 SG_ PARK_a087_sensorMismatchError m1 : 30|1@1+ (1,0) [0|1] "" Vector__XXX

BO_TX_BU_ 586 : DAS;
BO_TX_BU_ 810 : DAS;
BO_TX_BU_ 874 : DAS;
BO_TX_BU_ 841 : DAS;
BO_TX_BU_ 1082 : DAS;
BO_TX_BU_ 977 : EPAS3S;
BO_TX_BU_ 785 : EPAS3S;
BO_TX_BU_ 805 : ESP;
BO_TX_BU_ 813 : IBST;
BO_TX_BU_ 1486 : PARK;
BO_TX_BU_ 806 : PARK;
BO_TX_BU_ 846 : PARK;
BO_TX_BU_ 862 : PARK;
BO_TX_BU_ 926 : PARK;
BO_TX_BU_ 606 : PARK;
BO_TX_BU_ 542 : PARK;
BO_TX_BU_ 590 : PARK;
BO_TX_BU_ 526 : PARK;
BO_TX_BU_ 558 : PARK;
BO_TX_BU_ 814 : PARK;
BO_TX_BU_ 830 : PARK;
BO_TX_BU_ 798 : PARK;
BO_TX_BU_ 782 : PARK;
BO_TX_BU_ 894 : PARK;
CM_ BO_ 586 "Driver assistance computer message: visual debug; frame length from the layout, not yet observed on a vehicle bus";
CM_ SG_ 586 DAS_autosteerVehiclesUsage "Driver assistance computer: autosteer vehicles usage";
CM_ SG_ 586 DAS_autosteerHPPUsage "Driver assistance computer: autosteer HPP usage";
CM_ SG_ 586 DAS_autosteerNavigationUsage "Driver assistance computer: autosteer navigation usage";
CM_ SG_ 586 DAS_autosteerModelUsage "Driver assistance computer: autosteer model usage";
CM_ SG_ 586 DAS_autosteerBottsDotsUsage "Driver assistance computer: autosteer botts dots usage";
CM_ SG_ 586 DAS_offsetSide "Driver assistance computer: offset side";
CM_ SG_ 586 DAS_roadSurfaceType "Driver assistance computer: road surface type; raw 0 = signal not available (SNA)";
CM_ SG_ 586 DAS_autosteerHealthAnomalyLevel "Driver assistance computer: autosteer health anomaly level";
CM_ SG_ 586 DAS_autosteerHealthState "Driver assistance computer: autosteer health state";
CM_ SG_ 586 DAS_lastLinePreferenceReason "Driver assistance computer: last line preference reason";
CM_ SG_ 586 DAS_plannerState "Driver assistance computer: planner state";
CM_ SG_ 586 DAS_lastAutosteerAbortReason "Driver assistance computer: last autosteer abort reason";
CM_ SG_ 586 DAS_devAppInterfaceEnabled "Driver assistance computer: dev app interface enabled";
CM_ SG_ 586 DAS_navAvailable "Driver assistance computer: nav available";
CM_ SG_ 586 DAS_navDistance "Driver assistance computer: nav distance";
CM_ SG_ 586 DAS_accSmartSpeedActive "Driver assistance computer: acc smart speed active";
CM_ SG_ 586 DAS_accSmartSpeedState "Driver assistance computer: acc smart speed state; raw 7 = signal not available (SNA)";
CM_ SG_ 586 DAS_ulcInProgress "Reports active lane changes that were not commanded.";
CM_ SG_ 586 DAS_trafficAwareSetSpeedInUse "Indicates that autopilot is using cruise set speed based on flow of traffic";
CM_ SG_ 586 DAS_isaSystemState "ISA system state";
CM_ SG_ 586 DAS_behaviorType "Driver assistance computer: behavior type";
CM_ SG_ 586 DAS_ulcType "Reports the underlying reason for the uncommanded lane change, whether for speed or route.";
CM_ SG_ 586 DAS_rearVehDetectedThisCycle "Driver assistance computer: rear veh detected this cycle";
CM_ SG_ 586 DAS_rearLeftVehDetectedCurrent "Driver assistance computer: rear left veh detected current";
CM_ SG_ 586 DAS_rearRightVehDetectedTrip "Driver assistance computer: rear right veh detected trip";
CM_ SG_ 586 DAS_rearLeftVehDetectedTrip "Driver assistance computer: rear left veh detected trip";
CM_ BO_ 810 "Driver assistance computer message: warning matrix0; frame length from the layout, not yet observed on a vehicle bus";
CM_ SG_ 810 DAS_w002_ldwDisabled "Driver assistance computer: w002 ldw disabled";
CM_ SG_ 810 DAS_w003_isaDisabled "Driver assistance computer: w003 isa disabled";
CM_ SG_ 810 DAS_w004_accDisabled "Driver assistance computer: w004 acc disabled";
CM_ SG_ 810 DAS_w005_fcwCancelled "Driver assistance computer: w005 fcw cancelled";
CM_ SG_ 810 DAS_w006_aebCancelled "Driver assistance computer: w006 aeb cancelled";
CM_ SG_ 810 DAS_w007_ahlbDisabled "Driver assistance computer: w007 ahlb disabled";
CM_ SG_ 810 DAS_w008_parkDisabled "Driver assistance computer: w008 park disabled";
CM_ SG_ 810 DAS_w009_aebFault "Driver assistance computer: w009 aeb fault";
CM_ SG_ 810 DAS_w010_radcCalibIssue "Driver assistance computer: w010 radc calib issue";
CM_ SG_ 810 DAS_w011_scaEvent "Driver assistance computer: w011 sca event";
CM_ SG_ 810 DAS_w012_Cam_BootFailure "Driver assistance computer: w012 cam boot failure";
CM_ SG_ 810 DAS_w013_Cam_Watchdog "Driver assistance computer: w013 cam watchdog";
CM_ SG_ 810 DAS_w014_swAssert "Driver assistance computer: w014 sw assert";
CM_ SG_ 810 DAS_w015_Camera_Failsafes "Driver assistance computer: w015 camera failsafes";
CM_ SG_ 810 DAS_w016_aeb_e_event "Driver assistance computer: w016 aeb e event";
CM_ SG_ 810 DAS_w017_Cam_Msg_MIA "Driver assistance computer: w017 cam msg MIA";
CM_ SG_ 810 DAS_w018_ECU_Power_Issue "Driver assistance computer: w018 ECU power issue";
CM_ SG_ 810 DAS_w019_ECU_Stack_Overflow "Driver assistance computer: w019 ECU stack overflow";
CM_ SG_ 810 DAS_w020_ECU_checkstopError "Driver assistance computer: w020 ECU checkstop error";
CM_ SG_ 810 DAS_w021_ECU_Temperature_Issue "Driver assistance computer: w021 ECU temperature issue";
CM_ SG_ 810 DAS_w022_ECU_EEPROM_Failure "Driver assistance computer: w022 ECU EEPROM failure";
CM_ SG_ 810 DAS_w023_ECU_Cam_Statemismatc "Driver assistance computer: w023 ECU cam statemismatc";
CM_ SG_ 810 DAS_w024_ECU_Watchdog_Reset "Driver assistance computer: w024 ECU watchdog reset";
CM_ SG_ 810 DAS_w025_LC_Steering_Override "Driver assistance computer: w025 LC steering override";
CM_ SG_ 810 DAS_w026_ECU_timingIssue "Driver assistance computer: w026 ECU timing issue";
CM_ SG_ 810 DAS_w027_ECU_Reset_Fault "Driver assistance computer: w027 ECU reset fault";
CM_ SG_ 810 DAS_w028_spi_rx_error "Driver assistance computer: w028 spi rx error";
CM_ SG_ 810 DAS_w029_spi_tx_error "Driver assistance computer: w029 spi tx error";
CM_ SG_ 810 DAS_w030_Heater_Issue "Driver assistance computer: w030 heater issue";
CM_ SG_ 810 DAS_w031_canRxError "Driver assistance computer: w031 can rx error";
CM_ SG_ 810 DAS_w032_canTxError "Driver assistance computer: w032 can tx error";
CM_ SG_ 810 DAS_w033_gtwMia "Driver assistance computer: w033 gtw mia";
CM_ SG_ 810 DAS_w034_sccmMia "Driver assistance computer: w034 sccm mia";
CM_ SG_ 810 DAS_w035_espMia "Driver assistance computer: w035 esp mia";
CM_ SG_ 810 DAS_w036_bdyMia "Driver assistance computer: w036 bdy mia";
CM_ SG_ 810 DAS_w037_camTacIssue "Driver assistance computer: w037 cam tac issue";
CM_ SG_ 810 DAS_w038_camFailure "Driver assistance computer: w038 cam failure";
CM_ SG_ 810 DAS_w039_sdm_rcm_Mia "Driver assistance computer: w039 sdm rcm mia";
CM_ SG_ 810 DAS_w040_autopilotAngleSaturated "Driver assistance computer: w040 autopilot angle saturated";
CM_ SG_ 810 DAS_w041_autopilotRateSaturated "Driver assistance computer: w041 autopilot rate saturated";
CM_ SG_ 810 DAS_w042_autopilotAborting "Driver assistance computer: w042 autopilot aborting";
CM_ SG_ 810 DAS_w043_camLongRunTime "Driver assistance computer: w043 cam long run time";
CM_ SG_ 810 DAS_w044_appMobileyeFailure "Driver assistance computer: w044 app mobileye failure";
CM_ SG_ 810 DAS_w045_radMia "Driver assistance computer: w045 rad mia";
CM_ SG_ 810 DAS_w046_eepromRecordAbsent "Driver assistance computer: w046 eeprom record absent";
CM_ SG_ 810 DAS_w047_edrEvent "Driver assistance computer: w047 edr event";
CM_ SG_ 810 DAS_w048_DAS_Features_Disabled "Driver assistance computer: w048 DAS features disabled";
CM_ SG_ 810 DAS_w049_eyeqVersionMismatch "Driver assistance computer: w049 eyeq version mismatch";
CM_ SG_ 810 DAS_w050_aeb_event "Driver assistance computer: w050 aeb event";
CM_ SG_ 810 DAS_w051_radcEcuIssue "Driver assistance computer: w051 radc ecu issue";
CM_ SG_ 810 DAS_w052_radcSensorIssue "Driver assistance computer: w052 radc sensor issue";
CM_ SG_ 810 DAS_w053_radcCommIssue "Driver assistance computer: w053 radc comm issue";
CM_ SG_ 810 DAS_w054_camAutofix "Driver assistance computer: w054 cam autofix";
CM_ SG_ 810 DAS_w055_radcVersionMismatch "Driver assistance computer: w055 radc version mismatch";
CM_ SG_ 810 DAS_w056_diMia "Driver assistance computer: w056 di mia";
CM_ SG_ 810 DAS_w057_mcuMia "Driver assistance computer: w057 mcu mia";
CM_ SG_ 810 DAS_w058_epbMia "Driver assistance computer: w058 epb mia";
CM_ SG_ 810 DAS_w059_parkMia "Driver assistance computer: w059 park mia";
CM_ SG_ 810 DAS_w060_fcw_event "Driver assistance computer: w060 fcw event";
CM_ SG_ 810 DAS_w061_airSuspensionMia "Driver assistance computer: w061 air suspension mia";
CM_ SG_ 810 DAS_w062_radcAlignment "Driver assistance computer: w062 radc alignment";
CM_ SG_ 810 DAS_w063_parkVersionMismatch "Driver assistance computer: w063 park version mismatch";
CM_ SG_ 810 DAS_w064_epasMia "Driver assistance computer: w064 epas mia";
CM_ BO_ 874 "Driver assistance computer message: warning matrix1; frame length from the layout, not yet observed on a vehicle bus";
CM_ SG_ 874 DAS_w065_deserializerOvercurrent "Driver assistance computer: w065 deserializer overcurrent";
CM_ SG_ 874 DAS_w066_deserializerLockLost "Driver assistance computer: w066 deserializer lock lost";
CM_ SG_ 874 DAS_w067_steeringAlignment "Driver assistance computer: w067 steering alignment";
CM_ SG_ 874 DAS_w068_vlInconsistency "Driver assistance computer: w068 vl inconsistency";
CM_ SG_ 874 DAS_w069_apcSpaceMasked "Driver assistance computer: w069 apc space masked";
CM_ SG_ 874 DAS_w070_apcIncompleteCal "Driver assistance computer: w070 apc incomplete cal";
CM_ SG_ 874 DAS_w071_selfparkStarted "Driver assistance computer: w071 selfpark started";
CM_ SG_ 874 DAS_w072_selfparkComplete "Driver assistance computer: w072 selfpark complete";
CM_ SG_ 874 DAS_w073_issueEscalatedLDW "Driver assistance computer: w073 issue escalated LDW";
CM_ SG_ 874 DAS_w074_inPathStationaryObst "Driver assistance computer: w074 in path stationary obst";
CM_ SG_ 874 DAS_w075_scMia "Driver assistance computer: w075 sc mia";
CM_ SG_ 874 DAS_w076_mobilEyeSetC "Driver assistance computer: w076 mobil eye set c";
CM_ SG_ 874 DAS_w077_pmmActive "Driver assistance computer: w077 pmm active";
CM_ SG_ 874 DAS_w078_pmmActive2 "Driver assistance computer: w078 pmm active2";
CM_ SG_ 874 DAS_w079_edrAvailable "Driver assistance computer: w079 edr available";
CM_ SG_ 874 DAS_w080_accFailedActivation "Driver assistance computer: w080 acc failed activation";
CM_ SG_ 874 DAS_w081_pmmActiveBraking "Driver assistance computer: w081 pmm active braking";
CM_ SG_ 874 DAS_w082_inPathFSviolation "Driver assistance computer: w082 in path f sviolation";
CM_ SG_ 874 DAS_w083_inPathRADObject "Driver assistance computer: w083 in path RAD object";
CM_ SG_ 874 DAS_w084_pmmIPSO "Driver assistance computer: w084 pmm IPSO";
CM_ SG_ 874 DAS_w085_pmmSteering "Driver assistance computer: w085 pmm steering";
CM_ SG_ 874 DAS_w086_robCollision "Driver assistance computer: w086 rob collision";
CM_ SG_ 874 DAS_w087_DEPRECATED "Driver assistance computer: w087 DEPRECATED";
CM_ SG_ 874 DAS_w088_DEPRECATED "Driver assistance computer: w088 DEPRECATED";
CM_ SG_ 874 DAS_w089_DEPRECATED "Driver assistance computer: w089 DEPRECATED";
CM_ SG_ 874 DAS_w090_DEPRECATED "Driver assistance computer: w090 DEPRECATED";
CM_ SG_ 874 DAS_w091_DEPRECATED "Driver assistance computer: w091 DEPRECATED";
CM_ SG_ 874 DAS_w092_DEPRECATED "Driver assistance computer: w092 DEPRECATED";
CM_ SG_ 874 DAS_w093_DEPRECATED "Driver assistance computer: w093 DEPRECATED";
CM_ SG_ 874 DAS_w094_DEPRECATED "Driver assistance computer: w094 DEPRECATED";
CM_ SG_ 874 DAS_w095_DEPRECATED "Driver assistance computer: w095 DEPRECATED";
CM_ SG_ 874 DAS_w096_DEPRECATED "Driver assistance computer: w096 DEPRECATED";
CM_ SG_ 874 DAS_w097_DEPRECATED "Driver assistance computer: w097 DEPRECATED";
CM_ SG_ 874 DAS_w098_DEPRECATED "Driver assistance computer: w098 DEPRECATED";
CM_ SG_ 874 DAS_w099_DEPRECATED "Driver assistance computer: w099 DEPRECATED";
CM_ SG_ 874 DAS_w100_DEPRECATED "Driver assistance computer: w100 DEPRECATED";
CM_ SG_ 874 DAS_w101_DEPRECATED "Driver assistance computer: w101 DEPRECATED";
CM_ SG_ 874 DAS_w102_DEPRECATED "Driver assistance computer: w102 DEPRECATED";
CM_ SG_ 874 DAS_w103_robExperimentalAEB "Driver assistance computer: w103 rob experimental AEB";
CM_ SG_ 874 DAS_w104_DEPRECATED "Driver assistance computer: w104 DEPRECATED";
CM_ SG_ 874 DAS_w105_DEPRECATED "Driver assistance computer: w105 DEPRECATED";
CM_ SG_ 874 DAS_w106_torsionBarCalibrated "Driver assistance computer: w106 torsion bar calibrated";
CM_ BO_ 841 "Driver assistance computer message: warning matrix2; frame length from the layout, not yet observed on a vehicle bus";
CM_ SG_ 841 DAS_w129_mainCamExtNotCal "Driver assistance computer: w129 main cam ext not cal";
CM_ SG_ 841 DAS_w130_narrowCamExtNotCal "Driver assistance computer: w130 narrow cam ext not cal";
CM_ SG_ 841 DAS_w131_mainCamCalSaved "Driver assistance computer: w131 main cam cal saved";
CM_ SG_ 841 DAS_w132_narrowCamCalSaved "Driver assistance computer: w132 narrow cam cal saved";
CM_ SG_ 841 DAS_w133_mainCamInitFault "Driver assistance computer: w133 main cam init fault";
CM_ SG_ 841 DAS_w134_narrowCamInitFault "Driver assistance computer: w134 narrow cam init fault";
CM_ SG_ 841 DAS_w135_fisheyeCamInitFault "Driver assistance computer: w135 fisheye cam init fault";
CM_ SG_ 841 DAS_w136_lPillarCamInitFault "Driver assistance computer: w136 l pillar cam init fault";
CM_ SG_ 841 DAS_w137_rPillarCamInitFault "Driver assistance computer: w137 r pillar cam init fault";
CM_ SG_ 841 DAS_w138_lRepeatCamInitFault "Driver assistance computer: w138 l repeat cam init fault";
CM_ SG_ 841 DAS_w139_rRepeatCamInitFault "Driver assistance computer: w139 r repeat cam init fault";
CM_ SG_ 841 DAS_w140_backupCamInitFault "Driver assistance computer: w140 backup cam init fault";
CM_ SG_ 841 DAS_w141_ECU_Thermal_Issue "Driver assistance computer: w141 ECU thermal issue";
CM_ SG_ 841 DAS_w142_fwdCamPitchProblem "Driver assistance computer: w142 fwd cam pitch problem";
CM_ SG_ 841 DAS_w143_IDF_event "Driver assistance computer: w143 IDF event";
CM_ SG_ 841 DAS_w144_selfieCamInitFault "Driver assistance computer: w144 selfie cam init fault";
CM_ SG_ 841 DAS_w171_fisheyeCamExtNotCal "Driver assistance computer: w171 fisheye cam ext not cal";
CM_ SG_ 841 DAS_w172_lPillarCamExtNotCal "Driver assistance computer: w172 l pillar cam ext not cal";
CM_ SG_ 841 DAS_w173_rPillarCamExtNotCal "Driver assistance computer: w173 r pillar cam ext not cal";
CM_ SG_ 841 DAS_w174_lRepeatCamExtNotCal "Driver assistance computer: w174 l repeat cam ext not cal";
CM_ SG_ 841 DAS_w175_rRepeatCamExtNotCal "Driver assistance computer: w175 r repeat cam ext not cal";
CM_ SG_ 841 DAS_w177_fisheyeCamCalSaved "Driver assistance computer: w177 fisheye cam cal saved";
CM_ SG_ 841 DAS_w178_lPillarCamCalSaved "Driver assistance computer: w178 l pillar cam cal saved";
CM_ SG_ 841 DAS_w179_rPillarCamCalSaved "Driver assistance computer: w179 r pillar cam cal saved";
CM_ SG_ 841 DAS_w180_lRepeatCamCalSaved "Driver assistance computer: w180 l repeat cam cal saved";
CM_ SG_ 841 DAS_w181_rRepeatCamCalSaved "Driver assistance computer: w181 r repeat cam cal saved";
CM_ BO_ 1082 "Driver assistance computer message: warning matrix3; frame length from the layout, not yet observed on a vehicle bus";
CM_ SG_ 1082 DAS_w193_camWindshieldUnclean "Driver assistance computer: w193 cam windshield unclean";
CM_ SG_ 1082 DAS_w194_accDriverResumeRqrd "Driver assistance computer: w194 acc driver resume rqrd";
CM_ SG_ 1082 DAS_w195_scwUnavailable "Driver assistance computer: w195 scw unavailable";
CM_ SG_ 1082 DAS_w196_stopSignWarning "Driver assistance computer: w196 stop sign warning";
CM_ SG_ 1082 DAS_w197_redLightWarning "Driver assistance computer: w197 red light warning";
CM_ SG_ 1082 DAS_w198_tsrUnavailable "Driver assistance computer: w198 tsr unavailable";
CM_ SG_ 1082 DAS_w199_apcAbort "Driver assistance computer: w199 apc abort";
CM_ SG_ 1082 DAS_w200_lcSlowdown "Driver assistance computer: w200 lc slowdown";
CM_ SG_ 1082 DAS_w201_lcAborting "Driver assistance computer: w201 lc aborting";
CM_ SG_ 1082 DAS_w202_scwNoisyEnvironment "Driver assistance computer: w202 scw noisy environment";
CM_ SG_ 1082 DAS_w203_apcActivation "Driver assistance computer: w203 apc activation";
CM_ SG_ 1082 DAS_w204_apcFinalFront "Driver assistance computer: w204 apc final front";
CM_ SG_ 1082 DAS_w205_apcFinalRear "Driver assistance computer: w205 apc final rear";
CM_ SG_ 1082 DAS_w206_autosteerNotEnabled "Driver assistance computer: w206 autosteer not enabled";
CM_ SG_ 1082 DAS_w207_autosteerUnavailable "Driver assistance computer: w207 autosteer unavailable";
CM_ SG_ 1082 DAS_w208_rackDetected "Driver assistance computer: w208 rack detected";
CM_ SG_ 1082 DAS_w209_autoSummonRequest "Driver assistance computer: w209 auto summon request";
CM_ SG_ 1082 DAS_w210_camObstrcted "Driver assistance computer: w210 cam obstrcted";
CM_ SG_ 1082 DAS_w211_accNoSeatBelt "Driver assistance computer: w211 acc no seat belt";
CM_ SG_ 1082 DAS_w212_lcUnavailableStrikeOut "Driver assistance computer: w212 lc unavailable strike out";
CM_ SG_ 1082 DAS_w213_autosteerStruckOut "Driver assistance computer: w213 autosteer struck out";
CM_ SG_ 1082 DAS_w214_driverNotIntracting "Driver assistance computer: w214 driver not intracting";
CM_ SG_ 1082 DAS_w215_contDriverNotIntracting "Driver assistance computer: w215 cont driver not intracting";
CM_ SG_ 1082 DAS_w216_driverOverriding "Driver assistance computer: w216 driver overriding";
CM_ SG_ 1082 DAS_w217_lcUnavailableSpeeding "Driver assistance computer: w217 lc unavailable speeding";
CM_ SG_ 1082 DAS_w218_lcSpeedExceededLimit "Driver assistance computer: w218 lc speed exceeded limit";
CM_ SG_ 1082 DAS_w219_lcTempUnavailableSpeed "Driver assistance computer: w219 lc temp unavailable speed";
CM_ SG_ 1082 DAS_w220_lcTempUnavailableRoad "Driver assistance computer: w220 lc temp unavailable road";
CM_ SG_ 1082 DAS_w221_accRadarBlind "Driver assistance computer: w221 acc radar blind";
CM_ SG_ 1082 DAS_w222_accCameraBlind "Driver assistance computer: w222 acc camera blind";
CM_ SG_ 1082 DAS_w223_accObjectInPath "Driver assistance computer: w223 acc object in path";
CM_ SG_ 1082 DAS_w224_accCameraCalibration "Driver assistance computer: w224 acc camera calibration";
CM_ SG_ 1082 DAS_w225_lcDegradedVisSpeedLmt "Driver assistance computer: w225 lc degraded vis speed lmt";
CM_ SG_ 1082 DAS_w226_lcCamCalNeededSpeedLmt "Driver assistance computer: w226 lc cam cal needed speed lmt";
CM_ SG_ 1082 DAS_w227_virtualWallBlocked "Driver assistance computer: w227 virtual wall blocked";
CM_ SG_ 1082 DAS_w228_DEPRECATED "Driver assistance computer: w228 DEPRECATED";
CM_ SG_ 1082 DAS_w229_alcUltrasoundDamaged "Driver assistance computer: w229 alc ultrasound damaged";
CM_ SG_ 1082 DAS_w230_alcUltrasoundBlocked "Driver assistance computer: w230 alc ultrasound blocked";
CM_ SG_ 1082 DAS_w231_idfEvent "Driver assistance computer: w231 idf event";
CM_ SG_ 1082 DAS_w232_laneChangeRequested "Driver assistance computer: w232 lane change requested";
CM_ BO_ 977 "Electric power steering (secondary) message: angle calibration; frame length from the layout, not yet observed on a vehicle bus";
CM_ SG_ 977 EPAS3S_appliedAngleOffset "This represents the angle delta between the absolute steering angle reference and what EPAS estimates to be straight ahead. The steering angle offset can change up to 5deg at the beginning of each drive cycle.";
CM_ SG_ 977 EPAS3S_calculatedAngleOffset "Reports the calculated steering angle offset learned between the Steering Column Control Module (SCCM) and the Electronic Power Assist Steering (EPAS) steering angle.";
CM_ SG_ 977 EPAS3S_resyncStatus "Electric power steering (secondary): resync status";
CM_ SG_ 977 EPAS3S_pullDriftLongTermTrq "The learned, long term pull drift or road crown compensation torque that the rack is applying to the steering wheel.";
CM_ SG_ 977 EPAS3S_pullDriftCompTrq "The current pull drift or road crown compensation torque that the rack is applying to the steering wheel.";
CM_ SG_ 977 EPAS3S_learnedSCCMOffset "Electric power steering (secondary): learned SCCM offset";
CM_ BO_ 785 "Electric power steering (secondary) message: info; frame length from the layout, not yet observed on a vehicle bus";
CM_ SG_ 785 EPAS3S_infoIndex "Electric power steering (secondary): info index";
CM_ SG_ 785 EPAS3S_infoBuildType "Electric power steering (secondary): info build type";
CM_ SG_ 785 EPAS3S_infoComponentID "Electric power steering (secondary): info component ID";
CM_ SG_ 785 EPAS3S_infoPcbaID "Electric power steering (secondary): info pcba ID";
CM_ SG_ 785 EPAS3S_infoAssemblyID "Electric power steering (secondary): info assembly ID";
CM_ SG_ 785 EPAS3S_infoUsageID "Electric power steering (secondary): info usage ID";
CM_ SG_ 785 EPAS3S_infoApplicationCRC "Electric power steering (secondary): info application CRC";
CM_ SG_ 785 EPAS3S_infoBootUdsProtoVersion "Electric power steering (secondary): info boot uds proto version";
CM_ SG_ 785 EPAS3S_infoBootloaderCRC "Electric power steering (secondary): info bootloader CRC";
CM_ SG_ 785 EPAS3S_infoSubcomponent2 "Electric power steering (secondary): info subcomponent2";
CM_ BO_ 805 "Electronic stability control message: info; frame length from the layout, not yet observed on a vehicle bus";
CM_ SG_ 805 ESP_infoIndex "Electronic stability control: info index";
CM_ SG_ 805 ESP_infoBuildType "Electronic stability control: info build type";
CM_ SG_ 805 ESP_vehFlashMode "Electronic stability control: veh flash mode";
CM_ SG_ 805 ESP_infoComponentID "Electronic stability control: info component ID";
CM_ SG_ 805 ESP_infoPcbaID "Electronic stability control: info pcba ID";
CM_ SG_ 805 ESP_infoAssemblyID "Electronic stability control: info assembly ID";
CM_ SG_ 805 ESP_infoUsageID "Electronic stability control: info usage ID";
CM_ SG_ 805 ESP_infoSubUsageID "Electronic stability control: info sub usage ID";
CM_ SG_ 805 ESP_infoApplicationCRC "Indicating the Application CRC value of firmware running in system.";
CM_ SG_ 805 ESP_infoVehicleVariant "Electronic stability control: info vehicle variant";
CM_ SG_ 805 ESP_infoSubcomponent1 "Electronic stability control: info subcomponent1";
CM_ SG_ 805 ESP_infoBootUdsProtoVersion "Electronic stability control: info boot uds proto version";
CM_ SG_ 805 ESP_infoBootloaderCRC "Electronic stability control: info bootloader CRC";
CM_ SG_ 805 ESP_infoVariantCRC "Indicating the Calibration CRC value of firmware running in system.";
CM_ BO_ 813 "Electric brake booster message: info; frame length from the layout, not yet observed on a vehicle bus";
CM_ SG_ 813 IBST_infoIndex "Electric brake booster: info index";
CM_ SG_ 813 IBST_infoBuildType "Electric brake booster: info build type";
CM_ SG_ 813 IBST_infoComponentID "Electric brake booster: info component ID";
CM_ SG_ 813 IBST_infoPcbaID "Electric brake booster: info pcba ID";
CM_ SG_ 813 IBST_infoAssemblyID "Electric brake booster: info assembly ID";
CM_ SG_ 813 IBST_infoUsageID "Electric brake booster: info usage ID";
CM_ SG_ 813 IBST_infoSubUsageID "Electric brake booster: info sub usage ID";
CM_ SG_ 813 IBST_infoApplicationCRC "Indicating the Application CRC value of firmware running in system.";
CM_ SG_ 813 IBST_infoBootUdsProtoVersion "Electric brake booster: info boot uds proto version";
CM_ SG_ 813 IBST_infoBootloaderCRC "Electric brake booster: info bootloader CRC";
CM_ SG_ 813 IBST_infoVariantCRC "Indicating the Calibration CRC value of firmware running in system.";
CM_ BO_ 1486 "Parking assist sensors message: alert log; frame length from the layout, not yet observed on a vehicle bus";
CM_ SG_ 1486 PARK_alertID "Parking assist sensors: alert ID";
CM_ SG_ 1486 PARK_alertState "Parking assist sensors: alert state";
CM_ SG_ 1486 PARK_sw001_sensorTemperature "Parking assist sensors: sw001 sensor temperature";
CM_ SG_ 1486 PARK_sw002_membraneDisconct "Parking assist sensors: sw002 membrane disconct";
CM_ SG_ 1486 PARK_sw002_dampResistorFail "Parking assist sensors: sw002 damp resistor fail";
CM_ SG_ 1486 PARK_sw002_resonanceDrift "Parking assist sensors: sw002 resonance drift";
CM_ SG_ 1486 PARK_sw002_sensorCRC "Parking assist sensors: sw002 sensor CRC";
CM_ SG_ 1486 PARK_sw002_recieveFailure "Parking assist sensors: sw002 recieve failure";
CM_ SG_ 1486 PARK_sw002_diagnosticTransferErr "Parking assist sensors: sw002 diagnostic transfer error";
CM_ SG_ 1486 PARK_sw003_linError "Parking assist sensors: sw003 lin error";
CM_ SG_ 1486 PARK_sw003_linBusError "Parking assist sensors: sw003 lin bus error";
CM_ SG_ 1486 PARK_sw003_linFrameCountError "Parking assist sensors: sw003 lin frame count error";
CM_ SG_ 1486 PARK_sw004_reverbPeriod "Parking assist sensors: sw004 reverb period";
CM_ SG_ 1486 PARK_sw004_reverbTime "Parking assist sensors: sw004 reverb time";
CM_ SG_ 1486 PARK_sw004_highAttenTime "Parking assist sensors: sw004 high atten time";
CM_ SG_ 1486 PARK_sw004_closeConstEcho "Parking assist sensors: sw004 close const echo";
CM_ SG_ 1486 PARK_sw004_lowAttenTime "Parking assist sensors: sw004 low atten time";
CM_ SG_ 1486 PARK_sw004_attenTimeJitter "Parking assist sensors: sw004 atten time jitter";
CM_ SG_ 1486 PARK_sw004_reverbFreqJitter "Parking assist sensors: sw004 reverb freq jitter";
CM_ SG_ 1486 PARK_sw006_sensorTemperature "Parking assist sensors: sw006 sensor temperature";
CM_ SG_ 1486 PARK_sw007_membraneDisconct "Parking assist sensors: sw007 membrane disconct";
CM_ SG_ 1486 PARK_sw007_dampResistorFail "Parking assist sensors: sw007 damp resistor fail";
CM_ SG_ 1486 PARK_sw007_resonanceDrift "Parking assist sensors: sw007 resonance drift";
CM_ SG_ 1486 PARK_sw007_sensorCRC "Parking assist sensors: sw007 sensor CRC";
CM_ SG_ 1486 PARK_sw007_recieveFailure "Parking assist sensors: sw007 recieve failure";
CM_ SG_ 1486 PARK_sw007_diagnosticTransferErr "Parking assist sensors: sw007 diagnostic transfer error";
CM_ SG_ 1486 PARK_sw008_linError "Parking assist sensors: sw008 lin error";
CM_ SG_ 1486 PARK_sw008_linBusError "Parking assist sensors: sw008 lin bus error";
CM_ SG_ 1486 PARK_sw008_linFrameCountError "Parking assist sensors: sw008 lin frame count error";
CM_ SG_ 1486 PARK_sw009_reverbPeriod "Parking assist sensors: sw009 reverb period";
CM_ SG_ 1486 PARK_sw009_reverbTime "Parking assist sensors: sw009 reverb time";
CM_ SG_ 1486 PARK_sw009_highAttenTime "Parking assist sensors: sw009 high atten time";
CM_ SG_ 1486 PARK_sw009_closeConstEcho "Parking assist sensors: sw009 close const echo";
CM_ SG_ 1486 PARK_sw009_lowAttenTime "Parking assist sensors: sw009 low atten time";
CM_ SG_ 1486 PARK_sw009_attenTimeJitter "Parking assist sensors: sw009 atten time jitter";
CM_ SG_ 1486 PARK_sw009_reverbFreqJitter "Parking assist sensors: sw009 reverb freq jitter";
CM_ SG_ 1486 PARK_sw011_sensorTemperature "Parking assist sensors: sw011 sensor temperature";
CM_ SG_ 1486 PARK_sw012_membraneDisconct "Parking assist sensors: sw012 membrane disconct";
CM_ SG_ 1486 PARK_sw012_dampResistorFail "Parking assist sensors: sw012 damp resistor fail";
CM_ SG_ 1486 PARK_sw012_resonanceDrift "Parking assist sensors: sw012 resonance drift";
CM_ SG_ 1486 PARK_sw012_sensorCRC "Parking assist sensors: sw012 sensor CRC";
CM_ SG_ 1486 PARK_sw012_recieveFailure "Parking assist sensors: sw012 recieve failure";
CM_ SG_ 1486 PARK_sw012_diagnosticTransferErr "Parking assist sensors: sw012 diagnostic transfer error";
CM_ SG_ 1486 PARK_sw013_linError "Parking assist sensors: sw013 lin error";
CM_ SG_ 1486 PARK_sw013_linBusError "Parking assist sensors: sw013 lin bus error";
CM_ SG_ 1486 PARK_sw013_linFrameCountError "Parking assist sensors: sw013 lin frame count error";
CM_ SG_ 1486 PARK_sw014_reverbPeriod "Parking assist sensors: sw014 reverb period";
CM_ SG_ 1486 PARK_sw014_reverbTime "Parking assist sensors: sw014 reverb time";
CM_ SG_ 1486 PARK_sw014_highAttenTime "Parking assist sensors: sw014 high atten time";
CM_ SG_ 1486 PARK_sw014_closeConstEcho "Parking assist sensors: sw014 close const echo";
CM_ SG_ 1486 PARK_sw014_lowAttenTime "Parking assist sensors: sw014 low atten time";
CM_ SG_ 1486 PARK_sw014_attenTimeJitter "Parking assist sensors: sw014 atten time jitter";
CM_ SG_ 1486 PARK_sw014_reverbFreqJitter "Parking assist sensors: sw014 reverb freq jitter";
CM_ SG_ 1486 PARK_sw016_sensorTemperature "Parking assist sensors: sw016 sensor temperature";
CM_ SG_ 1486 PARK_sw017_membraneDisconct "Parking assist sensors: sw017 membrane disconct";
CM_ SG_ 1486 PARK_sw017_dampResistorFail "Parking assist sensors: sw017 damp resistor fail";
CM_ SG_ 1486 PARK_sw017_resonanceDrift "Parking assist sensors: sw017 resonance drift";
CM_ SG_ 1486 PARK_sw017_sensorCRC "Parking assist sensors: sw017 sensor CRC";
CM_ SG_ 1486 PARK_sw017_recieveFailure "Parking assist sensors: sw017 recieve failure";
CM_ SG_ 1486 PARK_sw017_diagnosticTransferErr "Parking assist sensors: sw017 diagnostic transfer error";
CM_ SG_ 1486 PARK_sw018_linError "Parking assist sensors: sw018 lin error";
CM_ SG_ 1486 PARK_sw018_linBusError "Parking assist sensors: sw018 lin bus error";
CM_ SG_ 1486 PARK_sw018_linFrameCountError "Parking assist sensors: sw018 lin frame count error";
CM_ SG_ 1486 PARK_sw019_reverbPeriod "Parking assist sensors: sw019 reverb period";
CM_ SG_ 1486 PARK_sw019_reverbTime "Parking assist sensors: sw019 reverb time";
CM_ SG_ 1486 PARK_sw019_highAttenTime "Parking assist sensors: sw019 high atten time";
CM_ SG_ 1486 PARK_sw019_closeConstEcho "Parking assist sensors: sw019 close const echo";
CM_ SG_ 1486 PARK_sw019_lowAttenTime "Parking assist sensors: sw019 low atten time";
CM_ SG_ 1486 PARK_sw019_attenTimeJitter "Parking assist sensors: sw019 atten time jitter";
CM_ SG_ 1486 PARK_sw019_reverbFreqJitter "Parking assist sensors: sw019 reverb freq jitter";
CM_ SG_ 1486 PARK_sw021_sensorTemperature "Parking assist sensors: sw021 sensor temperature";
CM_ SG_ 1486 PARK_sw022_membraneDisconct "Parking assist sensors: sw022 membrane disconct";
CM_ SG_ 1486 PARK_sw022_dampResistorFail "Parking assist sensors: sw022 damp resistor fail";
CM_ SG_ 1486 PARK_sw022_resonanceDrift "Parking assist sensors: sw022 resonance drift";
CM_ SG_ 1486 PARK_sw022_sensorCRC "Parking assist sensors: sw022 sensor CRC";
CM_ SG_ 1486 PARK_sw022_recieveFailure "Parking assist sensors: sw022 recieve failure";
CM_ SG_ 1486 PARK_sw022_diagnosticTransferErr "Parking assist sensors: sw022 diagnostic transfer error";
CM_ SG_ 1486 PARK_sw023_linError "Parking assist sensors: sw023 lin error";
CM_ SG_ 1486 PARK_sw023_linBusError "Parking assist sensors: sw023 lin bus error";
CM_ SG_ 1486 PARK_sw023_linFrameCountError "Parking assist sensors: sw023 lin frame count error";
CM_ SG_ 1486 PARK_sw024_reverbPeriod "Parking assist sensors: sw024 reverb period";
CM_ SG_ 1486 PARK_sw024_reverbTime "Parking assist sensors: sw024 reverb time";
CM_ SG_ 1486 PARK_sw024_highAttenTime "Parking assist sensors: sw024 high atten time";
CM_ SG_ 1486 PARK_sw024_closeConstEcho "Parking assist sensors: sw024 close const echo";
CM_ SG_ 1486 PARK_sw024_lowAttenTime "Parking assist sensors: sw024 low atten time";
CM_ SG_ 1486 PARK_sw024_attenTimeJitter "Parking assist sensors: sw024 atten time jitter";
CM_ SG_ 1486 PARK_sw024_reverbFreqJitter "Parking assist sensors: sw024 reverb freq jitter";
CM_ SG_ 1486 PARK_sw026_sensorTemperature "Parking assist sensors: sw026 sensor temperature";
CM_ SG_ 1486 PARK_sw027_membraneDisconct "Parking assist sensors: sw027 membrane disconct";
CM_ SG_ 1486 PARK_sw027_dampResistorFail "Parking assist sensors: sw027 damp resistor fail";
CM_ SG_ 1486 PARK_sw027_resonanceDrift "Parking assist sensors: sw027 resonance drift";
CM_ SG_ 1486 PARK_sw027_sensorCRC "Parking assist sensors: sw027 sensor CRC";
CM_ SG_ 1486 PARK_sw027_recieveFailure "Parking assist sensors: sw027 recieve failure";
CM_ SG_ 1486 PARK_sw027_diagnosticTransferErr "Parking assist sensors: sw027 diagnostic transfer error";
CM_ SG_ 1486 PARK_sw028_linError "Parking assist sensors: sw028 lin error";
CM_ SG_ 1486 PARK_sw028_linBusError "Parking assist sensors: sw028 lin bus error";
CM_ SG_ 1486 PARK_sw028_linFrameCountError "Parking assist sensors: sw028 lin frame count error";
CM_ SG_ 1486 PARK_sw029_reverbPeriod "Parking assist sensors: sw029 reverb period";
CM_ SG_ 1486 PARK_sw029_reverbTime "Parking assist sensors: sw029 reverb time";
CM_ SG_ 1486 PARK_sw029_highAttenTime "Parking assist sensors: sw029 high atten time";
CM_ SG_ 1486 PARK_sw029_closeConstEcho "Parking assist sensors: sw029 close const echo";
CM_ SG_ 1486 PARK_sw029_lowAttenTime "Parking assist sensors: sw029 low atten time";
CM_ SG_ 1486 PARK_sw029_attenTimeJitter "Parking assist sensors: sw029 atten time jitter";
CM_ SG_ 1486 PARK_sw029_reverbFreqJitter "Parking assist sensors: sw029 reverb freq jitter";
CM_ SG_ 1486 PARK_sw031_sensorTemperature "Parking assist sensors: sw031 sensor temperature";
CM_ SG_ 1486 PARK_sw032_membraneDisconct "Parking assist sensors: sw032 membrane disconct";
CM_ SG_ 1486 PARK_sw032_dampResistorFail "Parking assist sensors: sw032 damp resistor fail";
CM_ SG_ 1486 PARK_sw032_resonanceDrift "Parking assist sensors: sw032 resonance drift";
CM_ SG_ 1486 PARK_sw032_sensorCRC "Parking assist sensors: sw032 sensor CRC";
CM_ SG_ 1486 PARK_sw032_recieveFailure "Parking assist sensors: sw032 recieve failure";
CM_ SG_ 1486 PARK_sw032_diagnosticTransferErr "Parking assist sensors: sw032 diagnostic transfer error";
CM_ SG_ 1486 PARK_sw033_linError "Parking assist sensors: sw033 lin error";
CM_ SG_ 1486 PARK_sw033_linBusError "Parking assist sensors: sw033 lin bus error";
CM_ SG_ 1486 PARK_sw033_linFrameCountError "Parking assist sensors: sw033 lin frame count error";
CM_ SG_ 1486 PARK_sw034_reverbPeriod "Parking assist sensors: sw034 reverb period";
CM_ SG_ 1486 PARK_sw034_reverbTime "Parking assist sensors: sw034 reverb time";
CM_ SG_ 1486 PARK_sw034_highAttenTime "Parking assist sensors: sw034 high atten time";
CM_ SG_ 1486 PARK_sw034_closeConstEcho "Parking assist sensors: sw034 close const echo";
CM_ SG_ 1486 PARK_sw034_lowAttenTime "Parking assist sensors: sw034 low atten time";
CM_ SG_ 1486 PARK_sw034_attenTimeJitter "Parking assist sensors: sw034 atten time jitter";
CM_ SG_ 1486 PARK_sw034_reverbFreqJitter "Parking assist sensors: sw034 reverb freq jitter";
CM_ SG_ 1486 PARK_sw036_sensorTemperature "Parking assist sensors: sw036 sensor temperature";
CM_ SG_ 1486 PARK_sw037_membraneDisconct "Parking assist sensors: sw037 membrane disconct";
CM_ SG_ 1486 PARK_sw037_dampResistorFail "Parking assist sensors: sw037 damp resistor fail";
CM_ SG_ 1486 PARK_sw037_resonanceDrift "Parking assist sensors: sw037 resonance drift";
CM_ SG_ 1486 PARK_sw037_sensorCRC "Parking assist sensors: sw037 sensor CRC";
CM_ SG_ 1486 PARK_sw037_recieveFailure "Parking assist sensors: sw037 recieve failure";
CM_ SG_ 1486 PARK_sw037_diagnosticTransferErr "Parking assist sensors: sw037 diagnostic transfer error";
CM_ SG_ 1486 PARK_sw038_linError "Parking assist sensors: sw038 lin error";
CM_ SG_ 1486 PARK_sw038_linBusError "Parking assist sensors: sw038 lin bus error";
CM_ SG_ 1486 PARK_sw038_linFrameCountError "Parking assist sensors: sw038 lin frame count error";
CM_ SG_ 1486 PARK_sw039_reverbPeriod "Parking assist sensors: sw039 reverb period";
CM_ SG_ 1486 PARK_sw039_reverbTime "Parking assist sensors: sw039 reverb time";
CM_ SG_ 1486 PARK_sw039_highAttenTime "Parking assist sensors: sw039 high atten time";
CM_ SG_ 1486 PARK_sw039_closeConstEcho "Parking assist sensors: sw039 close const echo";
CM_ SG_ 1486 PARK_sw039_lowAttenTime "Parking assist sensors: sw039 low atten time";
CM_ SG_ 1486 PARK_sw039_attenTimeJitter "Parking assist sensors: sw039 atten time jitter";
CM_ SG_ 1486 PARK_sw039_reverbFreqJitter "Parking assist sensors: sw039 reverb freq jitter";
CM_ SG_ 1486 PARK_sw041_sensorTemperature "Parking assist sensors: sw041 sensor temperature";
CM_ SG_ 1486 PARK_sw042_membraneDisconct "Parking assist sensors: sw042 membrane disconct";
CM_ SG_ 1486 PARK_sw042_dampResistorFail "Parking assist sensors: sw042 damp resistor fail";
CM_ SG_ 1486 PARK_sw042_resonanceDrift "Parking assist sensors: sw042 resonance drift";
CM_ SG_ 1486 PARK_sw042_sensorCRC "Parking assist sensors: sw042 sensor CRC";
CM_ SG_ 1486 PARK_sw042_recieveFailure "Parking assist sensors: sw042 recieve failure";
CM_ SG_ 1486 PARK_sw042_diagnosticTransferErr "Parking assist sensors: sw042 diagnostic transfer error";
CM_ SG_ 1486 PARK_sw043_linError "Parking assist sensors: sw043 lin error";
CM_ SG_ 1486 PARK_sw043_linBusError "Parking assist sensors: sw043 lin bus error";
CM_ SG_ 1486 PARK_sw043_linFrameCountError "Parking assist sensors: sw043 lin frame count error";
CM_ SG_ 1486 PARK_sw044_reverbPeriod "Parking assist sensors: sw044 reverb period";
CM_ SG_ 1486 PARK_sw044_reverbTime "Parking assist sensors: sw044 reverb time";
CM_ SG_ 1486 PARK_sw044_highAttenTime "Parking assist sensors: sw044 high atten time";
CM_ SG_ 1486 PARK_sw044_closeConstEcho "Parking assist sensors: sw044 close const echo";
CM_ SG_ 1486 PARK_sw044_lowAttenTime "Parking assist sensors: sw044 low atten time";
CM_ SG_ 1486 PARK_sw044_attenTimeJitter "Parking assist sensors: sw044 atten time jitter";
CM_ SG_ 1486 PARK_sw044_reverbFreqJitter "Parking assist sensors: sw044 reverb freq jitter";
CM_ SG_ 1486 PARK_sw046_sensorTemperature "Parking assist sensors: sw046 sensor temperature";
CM_ SG_ 1486 PARK_sw047_membraneDisconct "Parking assist sensors: sw047 membrane disconct";
CM_ SG_ 1486 PARK_sw047_dampResistorFail "Parking assist sensors: sw047 damp resistor fail";
CM_ SG_ 1486 PARK_sw047_resonanceDrift "Parking assist sensors: sw047 resonance drift";
CM_ SG_ 1486 PARK_sw047_sensorCRC "Parking assist sensors: sw047 sensor CRC";
CM_ SG_ 1486 PARK_sw047_recieveFailure "Parking assist sensors: sw047 recieve failure";
CM_ SG_ 1486 PARK_sw047_diagnosticTransferErr "Parking assist sensors: sw047 diagnostic transfer error";
CM_ SG_ 1486 PARK_sw048_linError "Parking assist sensors: sw048 lin error";
CM_ SG_ 1486 PARK_sw048_linBusError "Parking assist sensors: sw048 lin bus error";
CM_ SG_ 1486 PARK_sw048_linFrameCountError "Parking assist sensors: sw048 lin frame count error";
CM_ SG_ 1486 PARK_sw049_reverbPeriod "Parking assist sensors: sw049 reverb period";
CM_ SG_ 1486 PARK_sw049_reverbTime "Parking assist sensors: sw049 reverb time";
CM_ SG_ 1486 PARK_sw049_highAttenTime "Parking assist sensors: sw049 high atten time";
CM_ SG_ 1486 PARK_sw049_closeConstEcho "Parking assist sensors: sw049 close const echo";
CM_ SG_ 1486 PARK_sw049_lowAttenTime "Parking assist sensors: sw049 low atten time";
CM_ SG_ 1486 PARK_sw049_attenTimeJitter "Parking assist sensors: sw049 atten time jitter";
CM_ SG_ 1486 PARK_sw049_reverbFreqJitter "Parking assist sensors: sw049 reverb freq jitter";
CM_ SG_ 1486 PARK_sw051_sensorTemperature "Parking assist sensors: sw051 sensor temperature";
CM_ SG_ 1486 PARK_sw052_membraneDisconct "Parking assist sensors: sw052 membrane disconct";
CM_ SG_ 1486 PARK_sw052_dampResistorFail "Parking assist sensors: sw052 damp resistor fail";
CM_ SG_ 1486 PARK_sw052_resonanceDrift "Parking assist sensors: sw052 resonance drift";
CM_ SG_ 1486 PARK_sw052_sensorCRC "Parking assist sensors: sw052 sensor CRC";
CM_ SG_ 1486 PARK_sw052_recieveFailure "Parking assist sensors: sw052 recieve failure";
CM_ SG_ 1486 PARK_sw052_diagnosticTransferErr "Parking assist sensors: sw052 diagnostic transfer error";
CM_ SG_ 1486 PARK_sw053_linError "Parking assist sensors: sw053 lin error";
CM_ SG_ 1486 PARK_sw053_linBusError "Parking assist sensors: sw053 lin bus error";
CM_ SG_ 1486 PARK_sw053_linFrameCountError "Parking assist sensors: sw053 lin frame count error";
CM_ SG_ 1486 PARK_sw054_reverbPeriod "Parking assist sensors: sw054 reverb period";
CM_ SG_ 1486 PARK_sw054_reverbTime "Parking assist sensors: sw054 reverb time";
CM_ SG_ 1486 PARK_sw054_highAttenTime "Parking assist sensors: sw054 high atten time";
CM_ SG_ 1486 PARK_sw054_closeConstEcho "Parking assist sensors: sw054 close const echo";
CM_ SG_ 1486 PARK_sw054_lowAttenTime "Parking assist sensors: sw054 low atten time";
CM_ SG_ 1486 PARK_sw054_attenTimeJitter "Parking assist sensors: sw054 atten time jitter";
CM_ SG_ 1486 PARK_sw054_reverbFreqJitter "Parking assist sensors: sw054 reverb freq jitter";
CM_ SG_ 1486 PARK_sw056_sensorTemperature "Parking assist sensors: sw056 sensor temperature";
CM_ SG_ 1486 PARK_sw057_membraneDisconct "Parking assist sensors: sw057 membrane disconct";
CM_ SG_ 1486 PARK_sw057_dampResistorFail "Parking assist sensors: sw057 damp resistor fail";
CM_ SG_ 1486 PARK_sw057_resonanceDrift "Parking assist sensors: sw057 resonance drift";
CM_ SG_ 1486 PARK_sw057_sensorCRC "Parking assist sensors: sw057 sensor CRC";
CM_ SG_ 1486 PARK_sw057_recieveFailure "Parking assist sensors: sw057 recieve failure";
CM_ SG_ 1486 PARK_sw057_diagnosticTransferErr "Parking assist sensors: sw057 diagnostic transfer error";
CM_ SG_ 1486 PARK_sw058_linError "Parking assist sensors: sw058 lin error";
CM_ SG_ 1486 PARK_sw058_linBusError "Parking assist sensors: sw058 lin bus error";
CM_ SG_ 1486 PARK_sw058_linFrameCountError "Parking assist sensors: sw058 lin frame count error";
CM_ SG_ 1486 PARK_sw059_reverbPeriod "Parking assist sensors: sw059 reverb period";
CM_ SG_ 1486 PARK_sw059_reverbTime "Parking assist sensors: sw059 reverb time";
CM_ SG_ 1486 PARK_sw059_highAttenTime "Parking assist sensors: sw059 high atten time";
CM_ SG_ 1486 PARK_sw059_closeConstEcho "Parking assist sensors: sw059 close const echo";
CM_ SG_ 1486 PARK_sw059_lowAttenTime "Parking assist sensors: sw059 low atten time";
CM_ SG_ 1486 PARK_sw059_attenTimeJitter "Parking assist sensors: sw059 atten time jitter";
CM_ SG_ 1486 PARK_sw059_reverbFreqJitter "Parking assist sensors: sw059 reverb freq jitter";
CM_ SG_ 1486 PARK_sw061_voltage "Parking assist sensors: sw061 voltage";
CM_ SG_ 1486 PARK_sw063_voltage "Parking assist sensors: sw063 voltage";
CM_ SG_ 1486 PARK_sw064_faultCode "Parking assist sensors: sw064 fault code";
CM_ SG_ 1486 PARK_sw065_expectedCRC "Parking assist sensors: sw065 expected CRC";
CM_ SG_ 1486 PARK_sw065_calculatedCRC "Parking assist sensors: sw065 calculated CRC";
CM_ SG_ 1486 PARK_sw066_placeHolder "Parking assist sensors: sw066 place holder";
CM_ SG_ 1486 PARK_sw068_placeHolder "Parking assist sensors: sw068 place holder";
CM_ SG_ 1486 PARK_sw069_messageID "Parking assist sensors: sw069 message ID";
CM_ SG_ 1486 PARK_sw070_messageID "Parking assist sensors: sw070 message ID";
CM_ SG_ 1486 PARK_sw071_messageID "Parking assist sensors: sw071 message ID";
CM_ SG_ 1486 PARK_sw072_messageID "Parking assist sensors: sw072 message ID";
CM_ SG_ 1486 PARK_sw073_messageID "Parking assist sensors: sw073 message ID";
CM_ SG_ 1486 PARK_sw074_messageID "Parking assist sensors: sw074 message ID";
CM_ SG_ 1486 PARK_sw075_messageID "Parking assist sensors: sw075 message ID";
CM_ SG_ 1486 PARK_sw076_messageID "Parking assist sensors: sw076 message ID";
CM_ SG_ 1486 PARK_sw077_errorExp "Parking assist sensors: sw077 error exp";
CM_ SG_ 1486 PARK_sw077_errorRx "Parking assist sensors: sw077 error rx";
CM_ SG_ 1486 PARK_sw077_messageID "Parking assist sensors: sw077 message ID";
CM_ SG_ 1486 PARK_sw077_errorType "Parking assist sensors: sw077 error type";
CM_ SG_ 1486 PARK_sw078_errorExp "Parking assist sensors: sw078 error exp";
CM_ SG_ 1486 PARK_sw078_errorRx "Parking assist sensors: sw078 error rx";
CM_ SG_ 1486 PARK_sw078_messageID "Parking assist sensors: sw078 message ID";
CM_ SG_ 1486 PARK_sw078_errorType "Parking assist sensors: sw078 error type";
CM_ SG_ 1486 PARK_sw079_errorExp "Parking assist sensors: sw079 error exp";
CM_ SG_ 1486 PARK_sw079_errorRx "Parking assist sensors: sw079 error rx";
CM_ SG_ 1486 PARK_sw079_messageID "Parking assist sensors: sw079 message ID";
CM_ SG_ 1486 PARK_sw079_errorType "Parking assist sensors: sw079 error type";
CM_ SG_ 1486 PARK_sw080_errorExp "Parking assist sensors: sw080 error exp";
CM_ SG_ 1486 PARK_sw080_errorRx "Parking assist sensors: sw080 error rx";
CM_ SG_ 1486 PARK_sw080_messageID "Parking assist sensors: sw080 message ID";
CM_ SG_ 1486 PARK_sw080_errorType "Parking assist sensors: sw080 error type";
CM_ SG_ 1486 PARK_sw081_errorExp "Parking assist sensors: sw081 error exp";
CM_ SG_ 1486 PARK_sw081_errorRx "Parking assist sensors: sw081 error rx";
CM_ SG_ 1486 PARK_sw081_messageID "Parking assist sensors: sw081 message ID";
CM_ SG_ 1486 PARK_sw081_errorType "Parking assist sensors: sw081 error type";
CM_ SG_ 1486 PARK_sw082_errorExp "Parking assist sensors: sw082 error exp";
CM_ SG_ 1486 PARK_sw082_errorRx "Parking assist sensors: sw082 error rx";
CM_ SG_ 1486 PARK_sw082_messageID "Parking assist sensors: sw082 message ID";
CM_ SG_ 1486 PARK_sw082_errorType "Parking assist sensors: sw082 error type";
CM_ SG_ 1486 PARK_sw083_errorExp "Parking assist sensors: sw083 error exp";
CM_ SG_ 1486 PARK_sw083_errorRx "Parking assist sensors: sw083 error rx";
CM_ SG_ 1486 PARK_sw083_messageID "Parking assist sensors: sw083 message ID";
CM_ SG_ 1486 PARK_sw083_errorType "Parking assist sensors: sw083 error type";
CM_ SG_ 1486 PARK_sw084_errorExp "Parking assist sensors: sw084 error exp";
CM_ SG_ 1486 PARK_sw084_errorRx "Parking assist sensors: sw084 error rx";
CM_ SG_ 1486 PARK_sw084_messageID "Parking assist sensors: sw084 message ID";
CM_ SG_ 1486 PARK_sw084_errorType "Parking assist sensors: sw084 error type";
CM_ SG_ 1486 PARK_sw086_writeRetryCounter "Parking assist sensors: sw086 write retry counter";
CM_ SG_ 1486 PARK_sw086_readRetryCounter "Parking assist sensors: sw086 read retry counter";
CM_ SG_ 1486 PARK_sw086_currentErrorCode "Parking assist sensors: sw086 current error code";
CM_ SG_ 1486 PARK_sw087_s1_sensorType "Parking assist sensors: sw087 s1 sensor type; raw 3 = signal not available (SNA)";
CM_ SG_ 1486 PARK_sw087_s2_sensorType "Parking assist sensors: sw087 s2 sensor type; raw 3 = signal not available (SNA)";
CM_ SG_ 1486 PARK_sw087_s3_sensorType "Parking assist sensors: sw087 s3 sensor type; raw 3 = signal not available (SNA)";
CM_ SG_ 1486 PARK_sw087_s4_sensorType "Parking assist sensors: sw087 s4 sensor type; raw 3 = signal not available (SNA)";
CM_ SG_ 1486 PARK_sw087_s5_sensorType "Parking assist sensors: sw087 s5 sensor type; raw 3 = signal not available (SNA)";
CM_ SG_ 1486 PARK_sw087_s6_sensorType "Parking assist sensors: sw087 s6 sensor type; raw 3 = signal not available (SNA)";
CM_ SG_ 1486 PARK_sw087_s7_sensorType "Parking assist sensors: sw087 s7 sensor type; raw 3 = signal not available (SNA)";
CM_ SG_ 1486 PARK_sw087_s8_sensorType "Parking assist sensors: sw087 s8 sensor type; raw 3 = signal not available (SNA)";
CM_ SG_ 1486 PARK_sw087_s9_sensorType "Parking assist sensors: sw087 s9 sensor type; raw 3 = signal not available (SNA)";
CM_ SG_ 1486 PARK_sw087_s10_sensorType "Parking assist sensors: sw087 s10 sensor type; raw 3 = signal not available (SNA)";
CM_ SG_ 1486 PARK_sw087_s11_sensorType "Parking assist sensors: sw087 s11 sensor type; raw 3 = signal not available (SNA)";
CM_ SG_ 1486 PARK_sw087_s12_sensorType "Parking assist sensors: sw087 s12 sensor type; raw 3 = signal not available (SNA)";
CM_ BO_ 806 "Parking assist sensors message: info; frame length from the layout, not yet observed on a vehicle bus";
CM_ SG_ 806 PARK_infoIndex "Parking assist sensors: info index";
CM_ SG_ 806 PARK_infoBuildType "Parking assist sensors: info build type";
CM_ SG_ 806 PARK_infoComponentID "Parking assist sensors: info component ID";
CM_ SG_ 806 PARK_infoPcbaID "Parking assist sensors: info pcba ID";
CM_ SG_ 806 PARK_infoAssemblyID "Parking assist sensors: info assembly ID";
CM_ SG_ 806 PARK_infoUsageID "Parking assist sensors: info usage ID";
CM_ SG_ 806 PARK_infoApplicationCRC "Parking assist sensors: info application CRC";
CM_ SG_ 806 PARK_infoBootUdsProtoVersion "Parking assist sensors: info boot uds proto version";
CM_ SG_ 806 PARK_infoBootloaderCRC "Parking assist sensors: info bootloader CRC";
CM_ BO_ 846 "Parking assist sensors message: pas front middle; frame length from the layout, not yet observed on a vehicle bus";
CM_ SG_ 846 PARK_frontLeftMiddleRawDistData "Zone defined as -38 degrees -> +12 degrees, distance to object in units of centimeters; raw 255 = signal not available (SNA)";
CM_ SG_ 846 PARK_frontMiddleRawDistData "Zone defined as -12 degrees to +12 degrees, distance to object in units of centimeters; raw 255 = signal not available (SNA)";
CM_ SG_ 846 PARK_frontRightMiddleRawDistData "Zone defined +12 degrees to +38 degreees, distance to object in units of centimeters; raw 255 = signal not available (SNA)";
CM_ SG_ 846 PARK_pasFrontMiddleCounter "Parking assist sensors: pas front middle counter";
CM_ SG_ 846 PARK_pasFrontMiddleChecksum "Parking assist sensors: pas front middle checksum";
CM_ BO_ 862 "Parking assist sensors message: pas rear middle; frame length from the layout, not yet observed on a vehicle bus";
CM_ SG_ 862 PARK_rearLeftMiddleRawDistData "Zone defined as -124 degrees to -166 degrees, distance to object in units of centimeters; raw 255 = signal not available (SNA)";
CM_ SG_ 862 PARK_rearMiddleRawDistData "Zone defined as -166 degrees to +166 degrees, distance to object in units of centimeters; raw 255 = signal not available (SNA)";
CM_ SG_ 862 PARK_rearRightMiddleRawDistData "Zone defined as +166 degrees to +124 degrees, distance to object in units of centimeters; raw 255 = signal not available (SNA)";
CM_ SG_ 862 PARK_pasRearMiddleCounter "Parking assist sensors: pas rear middle counter";
CM_ SG_ 862 PARK_pasRearMiddleChecksum "Parking assist sensors: pas rear middle checksum";
CM_ BO_ 926 "Parking assist sensors message: pas sides; frame length from the layout, not yet observed on a vehicle bus";
CM_ SG_ 926 PARK_rightSideFrontRawDistData "Right side (from inside the car) towards the front of the car (split evenly between axles); raw 255 = signal not available (SNA)";
CM_ SG_ 926 PARK_rightSideRearRawDistData "Right side (from inside the car) towards the rear of the car (split evenly between axles); raw 255 = signal not available (SNA)";
CM_ SG_ 926 PARK_leftSideFrontRawDistData "Left side (from inside the car) towards the front of the car (split evenly between axles); raw 255 = signal not available (SNA)";
CM_ SG_ 926 PARK_leftSideRearRawDistData "Left side (from inside the car) towards the rear of the car (split evenly between axles); raw 255 = signal not available (SNA)";
CM_ SG_ 926 PARK_pasSidesCounter "Parking assist sensors: pas sides counter";
CM_ SG_ 926 PARK_pasSidesChecksum "Parking assist sensors: pas sides checksum";
CM_ BO_ 606 "Parking assist sensors message: psc env slot; frame length from the layout, not yet observed on a vehicle bus";
CM_ SG_ 606 PARK_pscEnvSlotType "Parking assist sensors: psc env slot type";
CM_ SG_ 606 PARK_pscLeftParallelObj1X "Parking assist sensors: psc left parallel obj1 x; raw 2047 = signal not available (SNA)";
CM_ SG_ 606 PARK_pscLeftParallelObj1Y "Parking assist sensors: psc left parallel obj1 y; raw 2047 = signal not available (SNA)";
CM_ SG_ 606 PARK_pscLeftParallelObj1Alpha "Parking assist sensors: psc left parallel obj1 alpha; raw 127 = signal not available (SNA)";
CM_ SG_ 606 PARK_pscLeftParallelObj2Y "Parking assist sensors: psc left parallel obj2 y; raw 2047 = signal not available (SNA)";
CM_ SG_ 606 PARK_pscLeftParallelObj2X "Parking assist sensors: psc left parallel obj2 x; raw 2047 = signal not available (SNA)";
CM_ SG_ 606 PARK_pscLeftParallelObj2Alpha "Parking assist sensors: psc left parallel obj2 alpha; raw 127 = signal not available (SNA)";
CM_ SG_ 606 PARK_pscLeftCrossObj1X "Parking assist sensors: psc left cross obj1 x; raw 2047 = signal not available (SNA)";
CM_ SG_ 606 PARK_pscLeftCrossObj1Y "Parking assist sensors: psc left cross obj1 y; raw 2047 = signal not available (SNA)";
CM_ SG_ 606 PARK_pscLeftCrossObj1Alpha "Parking assist sensors: psc left cross obj1 alpha; raw 127 = signal not available (SNA)";
CM_ SG_ 606 PARK_pscLeftCrossObj2Y "Parking assist sensors: psc left cross obj2 y; raw 2047 = signal not available (SNA)";
CM_ SG_ 606 PARK_pscLeftCrossObj2X "Parking assist sensors: psc left cross obj2 x; raw 2047 = signal not available (SNA)";
CM_ SG_ 606 PARK_pscLeftCrossObj2Alpha "Parking assist sensors: psc left cross obj2 alpha; raw 127 = signal not available (SNA)";
CM_ SG_ 606 PARK_pscRightParallelObj1X "Parking assist sensors: psc right parallel obj1 x; raw 2047 = signal not available (SNA)";
CM_ SG_ 606 PARK_pscRightParallelObj1Y "Parking assist sensors: psc right parallel obj1 y; raw 2047 = signal not available (SNA)";
CM_ SG_ 606 PARK_pscRightParallelObj1Alpha "Parking assist sensors: psc right parallel obj1 alpha; raw 127 = signal not available (SNA)";
CM_ SG_ 606 PARK_pscRightParallelObj2Y "Parking assist sensors: psc right parallel obj2 y; raw 2047 = signal not available (SNA)";
CM_ SG_ 606 PARK_pscRightParallelObj2X "Parking assist sensors: psc right parallel obj2 x; raw 2047 = signal not available (SNA)";
CM_ SG_ 606 PARK_pscRightParallelObj2Alpha "Parking assist sensors: psc right parallel obj2 alpha; raw 127 = signal not available (SNA)";
CM_ SG_ 606 PARK_pscRightCrossObj1X "Parking assist sensors: psc right cross obj1 x; raw 2047 = signal not available (SNA)";
CM_ SG_ 606 PARK_pscRightCrossObj1Y "Parking assist sensors: psc right cross obj1 y; raw 2047 = signal not available (SNA)";
CM_ SG_ 606 PARK_pscRightCrossObj1Alpha "Parking assist sensors: psc right cross obj1 alpha; raw 127 = signal not available (SNA)";
CM_ SG_ 606 PARK_pscRightCrossObj2Y "Parking assist sensors: psc right cross obj2 y; raw 2047 = signal not available (SNA)";
CM_ SG_ 606 PARK_pscRightCrossObj2X "Parking assist sensors: psc right cross obj2 x; raw 2047 = signal not available (SNA)";
CM_ SG_ 606 PARK_pscRightCrossObj2Alpha "Parking assist sensors: psc right cross obj2 alpha; raw 127 = signal not available (SNA)";
CM_ BO_ 542 "Parking assist sensors message: psc status; frame length from the layout, not yet observed on a vehicle bus";
CM_ SG_ 542 PARK_pscParkStatus "Parking assist sensors: psc park status; raw 7 = signal not available (SNA)";
CM_ SG_ 542 PARK_pscParkAbortReason "Parking assist sensors: psc park abort reason; raw 31 = signal not available (SNA)";
CM_ SG_ 542 PARK_pscParallelSpace "The existence and type of a parallel parking slot identified by the ultrasonics.";
CM_ SG_ 542 PARK_pscCrossSpace "The type and existence of perpendicular parking slot identified through the ultrasonics";
CM_ SG_ 542 PARK_pscParallelRightParkable "Whether or not there is a valid path into a parallel parking slot on the right; raw 3 = signal not available (SNA)";
CM_ SG_ 542 PARK_pscParallelLeftParkable "Whether or not there is a valid path into a parallel parking slot on the left; raw 3 = signal not available (SNA)";
CM_ SG_ 542 PARK_pscCrossRightParkable "Parking assist sensors: psc cross right parkable; raw 3 = signal not available (SNA)";
CM_ SG_ 542 PARK_pscMaxVelocity "Parking assist sensors: psc max velocity; raw 63 = signal not available (SNA)";
CM_ SG_ 542 PARK_pscCrossLeftParkable "Parking assist sensors: psc cross left parkable; raw 3 = signal not available (SNA)";
CM_ SG_ 542 PARK_pscParkInstruction "The control request from PARK ECU during autopark manuever; raw 7 = signal not available (SNA)";
CM_ SG_ 542 PARK_pscManeuverDistance "Real time updated path length from center of vehicle reference frame to desired center of vehicle at end of current parking manuever; raw 2047 = signal not available (SNA)";
CM_ SG_ 542 PARK_pscAngleActive "Parking assist sensors: psc angle active";
CM_ SG_ 542 PARK_pscAngleRequest "Parking assist sensors: psc angle request";
CM_ SG_ 542 PARK_pscStatusCounter "Parking assist sensors: psc status counter";
CM_ SG_ 542 PARK_pscStatusChecksum "Parking assist sensors: psc status checksum";
CM_ BO_ 590 "Parking assist sensors message: psc veh slot; frame length from the layout, not yet observed on a vehicle bus";
CM_ SG_ 590 PARK_pscVehSlotType "Parking assist sensors: psc veh slot type";
CM_ SG_ 590 PARK_pscLeftParallelVehX "Parking assist sensors: psc left parallel veh x; raw 2047 = signal not available (SNA)";
CM_ SG_ 590 PARK_pscLeftParallelVehY "Parking assist sensors: psc left parallel veh y; raw 2047 = signal not available (SNA)";
CM_ SG_ 590 PARK_pscLeftParallelPsi "Parking assist sensors: psc left parallel psi; raw 8191 = signal not available (SNA)";
CM_ SG_ 590 PARK_pscLeftParallelSizeX "Parking assist sensors: psc left parallel size x; raw 255 = signal not available (SNA)";
CM_ SG_ 590 PARK_pscLeftParallelSizeY "Parking assist sensors: psc left parallel size y; raw 255 = signal not available (SNA)";
CM_ SG_ 590 PARK_pscLeftCrossVehX "Parking assist sensors: psc left cross veh x; raw 2047 = signal not available (SNA)";
CM_ SG_ 590 PARK_pscLeftCrossVehY "Parking assist sensors: psc left cross veh y; raw 2047 = signal not available (SNA)";
CM_ SG_ 590 PARK_pscLeftCrossPsi "Parking assist sensors: psc left cross psi; raw 8191 = signal not available (SNA)";
CM_ SG_ 590 PARK_pscLeftCrossSizeX "Parking assist sensors: psc left cross size x; raw 255 = signal not available (SNA)";
CM_ SG_ 590 PARK_pscLeftCrossSizeY "Parking assist sensors: psc left cross size y; raw 255 = signal not available (SNA)";
CM_ SG_ 590 PARK_pscRightParallelVehX "Parking assist sensors: psc right parallel veh x; raw 2047 = signal not available (SNA)";
CM_ SG_ 590 PARK_pscRightParallelVehY "Parking assist sensors: psc right parallel veh y; raw 2047 = signal not available (SNA)";
CM_ SG_ 590 PARK_pscRightParallelPsi "Parking assist sensors: psc right parallel psi; raw 8191 = signal not available (SNA)";
CM_ SG_ 590 PARK_pscRightParallelSizeX "Parking assist sensors: psc right parallel size x; raw 255 = signal not available (SNA)";
CM_ SG_ 590 PARK_pscRightParallelSizeY "Parking assist sensors: psc right parallel size y; raw 255 = signal not available (SNA)";
CM_ SG_ 590 PARK_pscRightCrossVehX "Parking assist sensors: psc right cross veh x; raw 2047 = signal not available (SNA)";
CM_ SG_ 590 PARK_pscRightCrossVehY "Parking assist sensors: psc right cross veh y; raw 2047 = signal not available (SNA)";
CM_ SG_ 590 PARK_pscRightCrossPsi "Parking assist sensors: psc right cross psi; raw 8191 = signal not available (SNA)";
CM_ SG_ 590 PARK_pscRightCrossSizeX "Parking assist sensors: psc right cross size x; raw 255 = signal not available (SNA)";
CM_ SG_ 590 PARK_pscRightCrossSizeY "Parking assist sensors: psc right cross size y; raw 255 = signal not available (SNA)";
CM_ BO_ 526 "Parking assist sensors message: sdi front; frame length from the layout, not yet observed on a vehicle bus";
CM_ SG_ 526 PARK_sdiSensor1RawDistData "Parking assist sensors: sdi sensor1 raw dist data; raw 511 = signal not available (SNA)";
CM_ SG_ 526 PARK_sdiSensor2RawDistData "Parking assist sensors: sdi sensor2 raw dist data; raw 511 = signal not available (SNA)";
CM_ SG_ 526 PARK_sdiSensor3RawDistData "Parking assist sensors: sdi sensor3 raw dist data; raw 511 = signal not available (SNA)";
CM_ SG_ 526 PARK_sdiSensor4RawDistData "Parking assist sensors: sdi sensor4 raw dist data; raw 511 = signal not available (SNA)";
CM_ SG_ 526 PARK_sdiSensor5RawDistData "Parking assist sensors: sdi sensor5 raw dist data; raw 511 = signal not available (SNA)";
CM_ SG_ 526 PARK_sdiSensor6RawDistData "Parking assist sensors: sdi sensor6 raw dist data; raw 511 = signal not available (SNA)";
CM_ SG_ 526 PARK_sdiFrontCounter "Parking assist sensors: sdi front counter";
CM_ SG_ 526 PARK_sdiFrontChecksum "Parking assist sensors: sdi front checksum";
CM_ BO_ 558 "Parking assist sensors message: sdi rear; frame length from the layout, not yet observed on a vehicle bus";
CM_ SG_ 558 PARK_sdiSensor7RawDistData "Parking assist sensors: sdi sensor7 raw dist data; raw 511 = signal not available (SNA)";
CM_ SG_ 558 PARK_sdiSensor8RawDistData "Parking assist sensors: sdi sensor8 raw dist data; raw 511 = signal not available (SNA)";
CM_ SG_ 558 PARK_sdiSensor9RawDistData "Parking assist sensors: sdi sensor9 raw dist data; raw 511 = signal not available (SNA)";
CM_ SG_ 558 PARK_sdiSensor10RawDistData "Parking assist sensors: sdi sensor10 raw dist data; raw 511 = signal not available (SNA)";
CM_ SG_ 558 PARK_sdiSensor11RawDistData "Parking assist sensors: sdi sensor11 raw dist data; raw 511 = signal not available (SNA)";
CM_ SG_ 558 PARK_sdiSensor12RawDistData "Parking assist sensors: sdi sensor12 raw dist data; raw 511 = signal not available (SNA)";
CM_ SG_ 558 PARK_sdiRearCounter "Parking assist sensors: sdi rear counter";
CM_ SG_ 558 PARK_sdiRearChecksum "Parking assist sensors: sdi rear checksum";
CM_ BO_ 814 "Parking assist sensors message: sensor status front; frame length from the layout, not yet observed on a vehicle bus";
CM_ SG_ 814 PARK_frontRightSensorState "Reports the state of the front right ultrasonic sensor; raw 3 = signal not available (SNA)";
CM_ SG_ 814 PARK_frontRightMiddleSensorState "Reports the state of the front right middle ultrasonic sensor; raw 3 = signal not available (SNA)";
CM_ SG_ 814 PARK_frontLeftMiddleSensorState "Reports the state of the front left middle ultrasonic sensor; raw 3 = signal not available (SNA)";
CM_ SG_ 814 PARK_frontLeftSensorState "Reports the state of the front left ultrasonic sensor; raw 3 = signal not available (SNA)";
CM_ SG_ 814 PARK_frontLeftRawDistData "Zone defined as -90 degrees -> -38 degrees, distance to object in units of centimeters; raw 255 = signal not available (SNA)";
CM_ SG_ 814 PARK_frontRightRawDistData "Zone defined as +38 degrees -> +90 degrees, distance to object in units of centimeters; raw 255 = signal not available (SNA)";
CM_ SG_ 814 PARK_systemStatusFront "Parking assist sensors: system status front; raw 3 = signal not available (SNA)";
CM_ SG_ 814 PARK_frontDtcPresent "Parking assist sensors: front dtc present; raw 3 = signal not available (SNA)";
CM_ SG_ 814 PARK_sensorStatusFrontCounter "Parking assist sensors: sensor status front counter";
CM_ SG_ 814 PARK_sensorStatusFrontChecksum "Parking assist sensors: sensor status front checksum";
CM_ BO_ 830 "Parking assist sensors message: sensor status rear; frame length from the layout, not yet observed on a vehicle bus";
CM_ SG_ 830 PARK_rearRightSensorState "Reports the state of the rear right ultrasonic sensor; raw 3 = signal not available (SNA)";
CM_ SG_ 830 PARK_rearRightMiddleSensorState "Reports the state of the rear right middle ultrasonic sensor; raw 3 = signal not available (SNA)";
CM_ SG_ 830 PARK_rearLeftMiddleSensorState "Reports the state of the rear left middle ultrasonic sensor; raw 3 = signal not available (SNA)";
CM_ SG_ 830 PARK_rearLeftSensorState "Reports the state of the rear left ultrasonic sensor; raw 3 = signal not available (SNA)";
CM_ SG_ 830 PARK_rearLeftRawDistData "Zone defined as -90 degrees to -125 degrees, distance to object in units of centimeters; raw 255 = signal not available (SNA)";
CM_ SG_ 830 PARK_rearRightRawDistData "Zone defined as +125 degrees to +90 degrees, distance to object in units of centimeters; raw 255 = signal not available (SNA)";
CM_ SG_ 830 PARK_systemStatusRear "Parking assist sensors: system status rear; raw 3 = signal not available (SNA)";
CM_ SG_ 830 PARK_rearDtcPresent "Parking assist sensors: rear dtc present; raw 3 = signal not available (SNA)";
CM_ SG_ 830 PARK_sensorStatusRearCounter "Parking assist sensors: sensor status rear counter";
CM_ SG_ 830 PARK_sensorStatusRearChecksum "Parking assist sensors: sensor status rear checksum";
CM_ BO_ 798 "Parking assist sensors message: status; frame length from the layout, not yet observed on a vehicle bus";
CM_ SG_ 798 PARK_status "Indicates status of park assist function; raw 3 = signal not available (SNA)";
CM_ SG_ 798 PARK_serviceRequest "Indicates whether or not PARK sensors/ECU require service; raw 3 = signal not available (SNA)";
CM_ SG_ 798 PARK_systemDtcPresent "Boolean indicating whether or not there is a DTC present; raw 3 = signal not available (SNA)";
CM_ SG_ 798 PARK_statusCounter "Parking assist sensors: status counter";
CM_ SG_ 798 PARK_statusChecksum "Parking assist sensors: status checksum";
CM_ SG_ 798 PARK_majorVersion "Parking assist sensors: major version; raw 255 = signal not available (SNA)";
CM_ SG_ 798 PARK_minorVersion "Parking assist sensors: minor version; raw 255 = signal not available (SNA)";
CM_ SG_ 798 PARK_subMinorVersion "Parking assist sensors: sub minor version; raw 255 = signal not available (SNA)";
CM_ BO_ 782 "Parking assist sensors message: status2; frame length from the layout, not yet observed on a vehicle bus";
CM_ SG_ 782 PARK_frontSVACharID "Parking assist sensors: front SVA char ID";
CM_ SG_ 782 PARK_pscRightCurbType "The type of curb for the parallel parking slot on the right side.";
CM_ SG_ 782 PARK_rearSVACharID "Parking assist sensors: rear SVA char ID";
CM_ SG_ 782 PARK_pscLeftCurbType "The type of curb identified for a parallel parking space on the left.";
CM_ SG_ 782 PARK_autoCalComplete "Parking assist sensors: auto cal complete";
CM_ SG_ 782 PARK_geometryType "Parking assist sensors: geometry type";
CM_ SG_ 782 PARK_tireFitment "Parking assist sensors: tire fitment; raw 3 = signal not available (SNA)";
CM_ SG_ 782 PARK_rackDetected "Parking assist sensors: rack detected; raw 3 = signal not available (SNA)";
CM_ SG_ 782 PARK_sdiActive "Whether or not the raw sensor measurements from the ultrasonics are present and valid";
CM_ SG_ 782 PARK_sdiNoise "The output of the noise detection algorithm for raw sensor measurements, indicates if the measurements are degraded due to ambient noise; raw 3 = signal not available (SNA)";
CM_ SG_ 782 PARK_sdiBlindSpotRight "The output of the PARK ECU blindspot algorithm on the right side of the car, indicates the presence of a vehicle; raw 3 = signal not available (SNA)";
CM_ SG_ 782 PARK_sdiBlindSpotLeft "The output of the PARK ECU blindspot algorithm on the left side of the car, indicates the presence of a vehicle; raw 3 = signal not available (SNA)";
CM_ SG_ 782 PARK_sensorType "Parking assist sensors: sensor type; raw 3 = signal not available (SNA)";
CM_ SG_ 782 PARK_status2Counter "Parking assist sensors: status2 counter";
CM_ SG_ 782 PARK_status2Checksum "Parking assist sensors: status2 checksum";
CM_ BO_ 894 "Parking assist sensors message: warning matrix; frame length from the layout, not yet observed on a vehicle bus";
CM_ SG_ 894 PARK_matrixIndex "Parking assist sensors: matrix index";
CM_ SG_ 894 PARK_a001_s1_overTemp "Parking assist sensors: a001 s1 over temp";
CM_ SG_ 894 PARK_a002_s1_internalFail "Parking assist sensors: a002 s1 internal fail";
CM_ SG_ 894 PARK_a003_s1_linCommError "Parking assist sensors: a003 s1 lin comm error";
CM_ SG_ 894 PARK_a004_s1_blocked "Parking assist sensors: a004 s1 blocked";
CM_ SG_ 894 PARK_a005_s1_crossTalk "Parking assist sensors: a005 s1 cross talk";
CM_ SG_ 894 PARK_a006_s2_overTemp "Parking assist sensors: a006 s2 over temp";
CM_ SG_ 894 PARK_a007_s2_internalFail "Parking assist sensors: a007 s2 internal fail";
CM_ SG_ 894 PARK_a008_s2_linCommError "Parking assist sensors: a008 s2 lin comm error";
CM_ SG_ 894 PARK_a009_s2_blocked "Parking assist sensors: a009 s2 blocked";
CM_ SG_ 894 PARK_a010_s2_crossTalk "Parking assist sensors: a010 s2 cross talk";
CM_ SG_ 894 PARK_a011_s3_overTemp "Parking assist sensors: a011 s3 over temp";
CM_ SG_ 894 PARK_a012_s3_internalFail "Parking assist sensors: a012 s3 internal fail";
CM_ SG_ 894 PARK_a013_s3_linCommError "Parking assist sensors: a013 s3 lin comm error";
CM_ SG_ 894 PARK_a014_s3_blocked "Parking assist sensors: a014 s3 blocked";
CM_ SG_ 894 PARK_a015_s3_crossTalk "Parking assist sensors: a015 s3 cross talk";
CM_ SG_ 894 PARK_a016_s4_overTemp "Parking assist sensors: a016 s4 over temp";
CM_ SG_ 894 PARK_a017_s4_internalFail "Parking assist sensors: a017 s4 internal fail";
CM_ SG_ 894 PARK_a018_s4_linCommError "Parking assist sensors: a018 s4 lin comm error";
CM_ SG_ 894 PARK_a019_s4_blocked "Parking assist sensors: a019 s4 blocked";
CM_ SG_ 894 PARK_a020_s4_crossTalk "Parking assist sensors: a020 s4 cross talk";
CM_ SG_ 894 PARK_a021_s5_overTemp "Parking assist sensors: a021 s5 over temp";
CM_ SG_ 894 PARK_a022_s5_internalFail "Parking assist sensors: a022 s5 internal fail";
CM_ SG_ 894 PARK_a023_s5_linCommError "Parking assist sensors: a023 s5 lin comm error";
CM_ SG_ 894 PARK_a024_s5_blocked "Parking assist sensors: a024 s5 blocked";
CM_ SG_ 894 PARK_a025_s5_crossTalk "Parking assist sensors: a025 s5 cross talk";
CM_ SG_ 894 PARK_a026_s6_overTemp "Parking assist sensors: a026 s6 over temp";
CM_ SG_ 894 PARK_a027_s6_internalFail "Parking assist sensors: a027 s6 internal fail";
CM_ SG_ 894 PARK_a028_s6_linCommError "Parking assist sensors: a028 s6 lin comm error";
CM_ SG_ 894 PARK_a029_s6_blocked "Parking assist sensors: a029 s6 blocked";
CM_ SG_ 894 PARK_a030_s6_crossTalk "Parking assist sensors: a030 s6 cross talk";
CM_ SG_ 894 PARK_a031_s7_overTemp "Parking assist sensors: a031 s7 over temp";
CM_ SG_ 894 PARK_a032_s7_internalFail "Parking assist sensors: a032 s7 internal fail";
CM_ SG_ 894 PARK_a033_s7_linCommError "Parking assist sensors: a033 s7 lin comm error";
CM_ SG_ 894 PARK_a034_s7_blocked "Parking assist sensors: a034 s7 blocked";
CM_ SG_ 894 PARK_a035_s7_crossTalk "Parking assist sensors: a035 s7 cross talk";
CM_ SG_ 894 PARK_a036_s8_overTemp "Parking assist sensors: a036 s8 over temp";
CM_ SG_ 894 PARK_a037_s8_internalFail "Parking assist sensors: a037 s8 internal fail";
CM_ SG_ 894 PARK_a038_s8_linCommError "Parking assist sensors: a038 s8 lin comm error";
CM_ SG_ 894 PARK_a039_s8_blocked "Parking assist sensors: a039 s8 blocked";
CM_ SG_ 894 PARK_a040_s8_crossTalk "Parking assist sensors: a040 s8 cross talk";
CM_ SG_ 894 PARK_a041_s9_overTemp "Parking assist sensors: a041 s9 over temp";
CM_ SG_ 894 PARK_a042_s9_internalFail "Parking assist sensors: a042 s9 internal fail";
CM_ SG_ 894 PARK_a043_s9_linCommError "Parking assist sensors: a043 s9 lin comm error";
CM_ SG_ 894 PARK_a044_s9_blocked "Parking assist sensors: a044 s9 blocked";
CM_ SG_ 894 PARK_a045_s9_crossTalk "Parking assist sensors: a045 s9 cross talk";
CM_ SG_ 894 PARK_a046_s10_overTemp "Parking assist sensors: a046 s10 over temp";
CM_ SG_ 894 PARK_a047_s10_internalFail "Parking assist sensors: a047 s10 internal fail";
CM_ SG_ 894 PARK_a048_s10_linCommError "Parking assist sensors: a048 s10 lin comm error";
CM_ SG_ 894 PARK_a049_s10_blocked "Parking assist sensors: a049 s10 blocked";
CM_ SG_ 894 PARK_a050_s10_crossTalk "Parking assist sensors: a050 s10 cross talk";
CM_ SG_ 894 PARK_a051_s11_overTemp "Parking assist sensors: a051 s11 over temp";
CM_ SG_ 894 PARK_a052_s11_internalFail "Parking assist sensors: a052 s11 internal fail";
CM_ SG_ 894 PARK_a053_s11_linCommError "Parking assist sensors: a053 s11 lin comm error";
CM_ SG_ 894 PARK_a054_s11_blocked "Parking assist sensors: a054 s11 blocked";
CM_ SG_ 894 PARK_a055_s11_crossTalk "Parking assist sensors: a055 s11 cross talk";
CM_ SG_ 894 PARK_a056_s12_overTemp "Parking assist sensors: a056 s12 over temp";
CM_ SG_ 894 PARK_a057_s12_internalFail "Parking assist sensors: a057 s12 internal fail";
CM_ SG_ 894 PARK_a058_s12_linCommError "Parking assist sensors: a058 s12 lin comm error";
CM_ SG_ 894 PARK_a059_s12_blocked "Parking assist sensors: a059 s12 blocked";
CM_ SG_ 894 PARK_a060_s12_crossTalk "Parking assist sensors: a060 s12 cross talk";
CM_ SG_ 894 PARK_a061_ecuUnderVoltage "Parking assist sensors: a061 ecu under voltage";
CM_ SG_ 894 PARK_a062_ecuOverVoltage "Parking assist sensors: a062 ecu over voltage";
CM_ SG_ 894 PARK_a063_sensorVoltage "Parking assist sensors: a063 sensor voltage";
CM_ SG_ 894 PARK_a064_ecuFault "Parking assist sensors: a064 ecu fault";
CM_ SG_ 894 PARK_a065_crcFault "Parking assist sensors: a065 crc fault";
CM_ SG_ 894 PARK_a066_calibrationMissing "Parking assist sensors: a066 calibration missing";
CM_ SG_ 894 PARK_a067_privateCANBusOff "Parking assist sensors: a067 private CAN bus off";
CM_ SG_ 894 PARK_a068_hardwareWatchDog "Parking assist sensors: a068 hardware watch dog";
CM_ SG_ 894 PARK_a069_dasMia "Parking assist sensors: a069 das mia";
CM_ SG_ 894 PARK_a070_sccmMia "Parking assist sensors: a070 sccm mia";
CM_ SG_ 894 PARK_a071_diMia "Parking assist sensors: a071 di mia";
CM_ SG_ 894 PARK_a072_epasMia "Parking assist sensors: a072 epas mia";
CM_ SG_ 894 PARK_a073_epbMia "Parking assist sensors: a073 epb mia";
CM_ SG_ 894 PARK_a074_espMia "Parking assist sensors: a074 esp mia";
CM_ SG_ 894 PARK_a075_rcmMia "Parking assist sensors: a075 rcm mia";
CM_ SG_ 894 PARK_a076_vcFrontMia "Parking assist sensors: a076 vc front mia";
CM_ SG_ 894 PARK_a077_dasError "Parking assist sensors: a077 das error";
CM_ SG_ 894 PARK_a078_diError "Parking assist sensors: a078 di error";
CM_ SG_ 894 PARK_a079_epasError "Parking assist sensors: a079 epas error";
CM_ SG_ 894 PARK_a080_epbError "Parking assist sensors: a080 epb error";
CM_ SG_ 894 PARK_a081_espError "Parking assist sensors: a081 esp error";
CM_ SG_ 894 PARK_a082_rcmError "Parking assist sensors: a082 rcm error";
CM_ SG_ 894 PARK_a083_vcFrontError "Parking assist sensors: a083 vc front error";
CM_ SG_ 894 PARK_a084_sccmError "Parking assist sensors: a084 sccm error";
CM_ SG_ 894 PARK_a085_watchdogReset "Parking assist sensors: a085 watchdog reset";
CM_ SG_ 894 PARK_a086_nvmFault "Parking assist sensors: a086 nvm fault";
CM_ SG_ 894 PARK_a087_sensorMismatchError "Parking assist sensors: a087 sensor mismatch error";
BA_DEF_ BO_ "GenMsgCycleTime" INT 0 3600000;
BA_DEF_ BO_ "GenMsgSendType" ENUM "Cyclic","NotUsed","NotUsed","NotUsed","NotUsed","NotUsed","NotUsed","IfActive","NoMsgSendType","NotUsed";
BA_DEF_ BO_ "VFrameFormat" ENUM "StandardCAN","ExtendedCAN","reserved","J1939PG","reserved","reserved","reserved","reserved","reserved","reserved","reserved","reserved","reserved","reserved","StandardCAN_FD","ExtendedCAN_FD";
BA_DEF_ BO_ "CANFD_BRS" ENUM "0","1";
BA_DEF_ SG_ "GenSigSNA" STRING;
BA_DEF_ SG_ "SystemSignalLongSymbol" STRING;
BA_DEF_ SG_ "Confidence" ENUM "validated","plausible","layout-only","contradicted";
BA_DEF_DEF_ "GenMsgCycleTime" 0;
BA_DEF_DEF_ "GenMsgSendType" "NoMsgSendType";
BA_DEF_DEF_ "VFrameFormat" "StandardCAN";
BA_DEF_DEF_ "CANFD_BRS" "1";
BA_DEF_DEF_ "GenSigSNA" "";
BA_DEF_DEF_ "SystemSignalLongSymbol" "";
BA_DEF_DEF_ "Confidence" "layout-only";
BA_ "GenMsgCycleTime" BO_ 586 100;
BA_ "GenMsgSendType" BO_ 586 0;
BA_ "GenMsgCycleTime" BO_ 810 1000;
BA_ "GenMsgSendType" BO_ 810 0;
BA_ "GenMsgCycleTime" BO_ 874 1000;
BA_ "GenMsgSendType" BO_ 874 0;
BA_ "GenMsgCycleTime" BO_ 841 1000;
BA_ "GenMsgSendType" BO_ 841 0;
BA_ "GenMsgCycleTime" BO_ 1082 1000;
BA_ "GenMsgSendType" BO_ 1082 0;
BA_ "GenMsgCycleTime" BO_ 977 1000;
BA_ "GenMsgSendType" BO_ 977 0;
BA_ "GenMsgCycleTime" BO_ 785 1000;
BA_ "GenMsgSendType" BO_ 785 0;
BA_ "GenMsgCycleTime" BO_ 805 10000;
BA_ "GenMsgSendType" BO_ 805 0;
BA_ "GenMsgCycleTime" BO_ 813 10000;
BA_ "GenMsgSendType" BO_ 813 0;
BA_ "GenMsgCycleTime" BO_ 806 1000;
BA_ "GenMsgSendType" BO_ 806 0;
BA_ "GenMsgCycleTime" BO_ 846 100;
BA_ "GenMsgSendType" BO_ 846 0;
BA_ "GenMsgCycleTime" BO_ 862 100;
BA_ "GenMsgSendType" BO_ 862 0;
BA_ "GenMsgCycleTime" BO_ 926 100;
BA_ "GenMsgSendType" BO_ 926 0;
BA_ "GenMsgCycleTime" BO_ 606 100;
BA_ "GenMsgSendType" BO_ 606 0;
BA_ "GenMsgCycleTime" BO_ 542 40;
BA_ "GenMsgSendType" BO_ 542 0;
BA_ "GenMsgCycleTime" BO_ 590 100;
BA_ "GenMsgSendType" BO_ 590 0;
BA_ "GenMsgCycleTime" BO_ 526 40;
BA_ "GenMsgSendType" BO_ 526 0;
BA_ "GenMsgCycleTime" BO_ 558 40;
BA_ "GenMsgSendType" BO_ 558 0;
BA_ "GenMsgCycleTime" BO_ 814 100;
BA_ "GenMsgSendType" BO_ 814 0;
BA_ "GenMsgCycleTime" BO_ 830 100;
BA_ "GenMsgSendType" BO_ 830 0;
BA_ "GenMsgCycleTime" BO_ 798 500;
BA_ "GenMsgSendType" BO_ 798 0;
BA_ "GenMsgCycleTime" BO_ 782 250;
BA_ "GenMsgSendType" BO_ 782 0;
BA_ "GenMsgCycleTime" BO_ 894 1000;
BA_ "GenMsgSendType" BO_ 894 0;
BA_ "Confidence" SG_ 586 DAS_autosteerVehiclesUsage 1;
BA_ "Confidence" SG_ 586 DAS_autosteerHPPUsage 1;
BA_ "Confidence" SG_ 586 DAS_autosteerNavigationUsage 1;
BA_ "Confidence" SG_ 586 DAS_autosteerModelUsage 1;
BA_ "Confidence" SG_ 586 DAS_autosteerBottsDotsUsage 1;
BA_ "Confidence" SG_ 586 DAS_offsetSide 1;
BA_ "Confidence" SG_ 586 DAS_roadSurfaceType 1;
BA_ "GenSigSNA" SG_ 586 DAS_roadSurfaceType "0";
BA_ "Confidence" SG_ 586 DAS_autosteerHealthState 1;
BA_ "Confidence" SG_ 586 DAS_lastLinePreferenceReason 1;
BA_ "Confidence" SG_ 586 DAS_plannerState 1;
BA_ "Confidence" SG_ 586 DAS_lastAutosteerAbortReason 1;
BA_ "Confidence" SG_ 586 DAS_navAvailable 1;
BA_ "Confidence" SG_ 586 DAS_navDistance 1;
BA_ "Confidence" SG_ 586 DAS_accSmartSpeedState 1;
BA_ "GenSigSNA" SG_ 586 DAS_accSmartSpeedState "7";
BA_ "Confidence" SG_ 586 DAS_ulcInProgress 1;
BA_ "Confidence" SG_ 586 DAS_trafficAwareSetSpeedInUse 1;
BA_ "Confidence" SG_ 586 DAS_isaSystemState 1;
BA_ "Confidence" SG_ 586 DAS_behaviorType 1;
BA_ "Confidence" SG_ 586 DAS_ulcType 1;
BA_ "Confidence" SG_ 586 DAS_rearVehDetectedThisCycle 1;
BA_ "Confidence" SG_ 586 DAS_rearLeftVehDetectedCurrent 1;
BA_ "Confidence" SG_ 586 DAS_rearRightVehDetectedTrip 1;
BA_ "Confidence" SG_ 586 DAS_rearLeftVehDetectedTrip 1;
BA_ "Confidence" SG_ 977 EPAS3S_appliedAngleOffset 1;
BA_ "Confidence" SG_ 977 EPAS3S_calculatedAngleOffset 1;
BA_ "Confidence" SG_ 977 EPAS3S_resyncStatus 1;
BA_ "Confidence" SG_ 977 EPAS3S_pullDriftLongTermTrq 1;
BA_ "Confidence" SG_ 977 EPAS3S_pullDriftCompTrq 1;
BA_ "Confidence" SG_ 977 EPAS3S_learnedSCCMOffset 1;
BA_ "Confidence" SG_ 785 EPAS3S_infoIndex 1;
BA_ "Confidence" SG_ 785 EPAS3S_infoBuildType 1;
BA_ "Confidence" SG_ 805 ESP_infoIndex 1;
BA_ "Confidence" SG_ 805 ESP_infoBuildType 1;
BA_ "Confidence" SG_ 805 ESP_vehFlashMode 1;
BA_ "Confidence" SG_ 805 ESP_infoSubUsageID 1;
BA_ "Confidence" SG_ 805 ESP_infoApplicationCRC 1;
BA_ "Confidence" SG_ 805 ESP_infoVehicleVariant 1;
BA_ "Confidence" SG_ 805 ESP_infoVariantCRC 1;
BA_ "Confidence" SG_ 813 IBST_infoIndex 1;
BA_ "Confidence" SG_ 813 IBST_infoBuildType 1;
BA_ "Confidence" SG_ 813 IBST_infoApplicationCRC 1;
BA_ "Confidence" SG_ 813 IBST_infoVariantCRC 1;
BA_ "Confidence" SG_ 1486 PARK_alertID 1;
BA_ "Confidence" SG_ 1486 PARK_alertState 1;
BA_ "Confidence" SG_ 1486 PARK_sw001_sensorTemperature 1;
BA_ "SystemSignalLongSymbol" SG_ 1486 PARK_sw002_diagnosticTransferErr "PARK_sw002_diagnosticTransferError";
BA_ "Confidence" SG_ 1486 PARK_sw004_reverbPeriod 1;
BA_ "Confidence" SG_ 1486 PARK_sw004_reverbTime 1;
BA_ "Confidence" SG_ 1486 PARK_sw006_sensorTemperature 1;
BA_ "SystemSignalLongSymbol" SG_ 1486 PARK_sw007_diagnosticTransferErr "PARK_sw007_diagnosticTransferError";
BA_ "Confidence" SG_ 1486 PARK_sw009_reverbPeriod 1;
BA_ "Confidence" SG_ 1486 PARK_sw009_reverbTime 1;
BA_ "Confidence" SG_ 1486 PARK_sw011_sensorTemperature 1;
BA_ "SystemSignalLongSymbol" SG_ 1486 PARK_sw012_diagnosticTransferErr "PARK_sw012_diagnosticTransferError";
BA_ "Confidence" SG_ 1486 PARK_sw014_reverbPeriod 1;
BA_ "Confidence" SG_ 1486 PARK_sw014_reverbTime 1;
BA_ "Confidence" SG_ 1486 PARK_sw016_sensorTemperature 1;
BA_ "SystemSignalLongSymbol" SG_ 1486 PARK_sw017_diagnosticTransferErr "PARK_sw017_diagnosticTransferError";
BA_ "Confidence" SG_ 1486 PARK_sw019_reverbPeriod 1;
BA_ "Confidence" SG_ 1486 PARK_sw019_reverbTime 1;
BA_ "Confidence" SG_ 1486 PARK_sw021_sensorTemperature 1;
BA_ "SystemSignalLongSymbol" SG_ 1486 PARK_sw022_diagnosticTransferErr "PARK_sw022_diagnosticTransferError";
BA_ "Confidence" SG_ 1486 PARK_sw024_reverbPeriod 1;
BA_ "Confidence" SG_ 1486 PARK_sw024_reverbTime 1;
BA_ "Confidence" SG_ 1486 PARK_sw026_sensorTemperature 1;
BA_ "SystemSignalLongSymbol" SG_ 1486 PARK_sw027_diagnosticTransferErr "PARK_sw027_diagnosticTransferError";
BA_ "Confidence" SG_ 1486 PARK_sw029_reverbPeriod 1;
BA_ "Confidence" SG_ 1486 PARK_sw029_reverbTime 1;
BA_ "Confidence" SG_ 1486 PARK_sw031_sensorTemperature 1;
BA_ "SystemSignalLongSymbol" SG_ 1486 PARK_sw032_diagnosticTransferErr "PARK_sw032_diagnosticTransferError";
BA_ "Confidence" SG_ 1486 PARK_sw034_reverbPeriod 1;
BA_ "Confidence" SG_ 1486 PARK_sw034_reverbTime 1;
BA_ "Confidence" SG_ 1486 PARK_sw036_sensorTemperature 1;
BA_ "SystemSignalLongSymbol" SG_ 1486 PARK_sw037_diagnosticTransferErr "PARK_sw037_diagnosticTransferError";
BA_ "Confidence" SG_ 1486 PARK_sw039_reverbPeriod 1;
BA_ "Confidence" SG_ 1486 PARK_sw039_reverbTime 1;
BA_ "Confidence" SG_ 1486 PARK_sw041_sensorTemperature 1;
BA_ "SystemSignalLongSymbol" SG_ 1486 PARK_sw042_diagnosticTransferErr "PARK_sw042_diagnosticTransferError";
BA_ "Confidence" SG_ 1486 PARK_sw044_reverbPeriod 1;
BA_ "Confidence" SG_ 1486 PARK_sw044_reverbTime 1;
BA_ "Confidence" SG_ 1486 PARK_sw046_sensorTemperature 1;
BA_ "SystemSignalLongSymbol" SG_ 1486 PARK_sw047_diagnosticTransferErr "PARK_sw047_diagnosticTransferError";
BA_ "Confidence" SG_ 1486 PARK_sw049_reverbPeriod 1;
BA_ "Confidence" SG_ 1486 PARK_sw049_reverbTime 1;
BA_ "Confidence" SG_ 1486 PARK_sw051_sensorTemperature 1;
BA_ "SystemSignalLongSymbol" SG_ 1486 PARK_sw052_diagnosticTransferErr "PARK_sw052_diagnosticTransferError";
BA_ "Confidence" SG_ 1486 PARK_sw054_reverbPeriod 1;
BA_ "Confidence" SG_ 1486 PARK_sw054_reverbTime 1;
BA_ "Confidence" SG_ 1486 PARK_sw056_sensorTemperature 1;
BA_ "SystemSignalLongSymbol" SG_ 1486 PARK_sw057_diagnosticTransferErr "PARK_sw057_diagnosticTransferError";
BA_ "Confidence" SG_ 1486 PARK_sw059_reverbPeriod 1;
BA_ "Confidence" SG_ 1486 PARK_sw059_reverbTime 1;
BA_ "Confidence" SG_ 1486 PARK_sw061_voltage 1;
BA_ "Confidence" SG_ 1486 PARK_sw063_voltage 1;
BA_ "Confidence" SG_ 1486 PARK_sw077_errorType 1;
BA_ "Confidence" SG_ 1486 PARK_sw078_errorType 1;
BA_ "Confidence" SG_ 1486 PARK_sw079_errorType 1;
BA_ "Confidence" SG_ 1486 PARK_sw080_errorType 1;
BA_ "Confidence" SG_ 1486 PARK_sw081_errorType 1;
BA_ "Confidence" SG_ 1486 PARK_sw082_errorType 1;
BA_ "Confidence" SG_ 1486 PARK_sw083_errorType 1;
BA_ "Confidence" SG_ 1486 PARK_sw084_errorType 1;
BA_ "Confidence" SG_ 1486 PARK_sw087_s1_sensorType 1;
BA_ "GenSigSNA" SG_ 1486 PARK_sw087_s1_sensorType "3";
BA_ "Confidence" SG_ 1486 PARK_sw087_s2_sensorType 1;
BA_ "GenSigSNA" SG_ 1486 PARK_sw087_s2_sensorType "3";
BA_ "Confidence" SG_ 1486 PARK_sw087_s3_sensorType 1;
BA_ "GenSigSNA" SG_ 1486 PARK_sw087_s3_sensorType "3";
BA_ "Confidence" SG_ 1486 PARK_sw087_s4_sensorType 1;
BA_ "GenSigSNA" SG_ 1486 PARK_sw087_s4_sensorType "3";
BA_ "Confidence" SG_ 1486 PARK_sw087_s5_sensorType 1;
BA_ "GenSigSNA" SG_ 1486 PARK_sw087_s5_sensorType "3";
BA_ "Confidence" SG_ 1486 PARK_sw087_s6_sensorType 1;
BA_ "GenSigSNA" SG_ 1486 PARK_sw087_s6_sensorType "3";
BA_ "Confidence" SG_ 1486 PARK_sw087_s7_sensorType 1;
BA_ "GenSigSNA" SG_ 1486 PARK_sw087_s7_sensorType "3";
BA_ "Confidence" SG_ 1486 PARK_sw087_s8_sensorType 1;
BA_ "GenSigSNA" SG_ 1486 PARK_sw087_s8_sensorType "3";
BA_ "Confidence" SG_ 1486 PARK_sw087_s9_sensorType 1;
BA_ "GenSigSNA" SG_ 1486 PARK_sw087_s9_sensorType "3";
BA_ "Confidence" SG_ 1486 PARK_sw087_s10_sensorType 1;
BA_ "GenSigSNA" SG_ 1486 PARK_sw087_s10_sensorType "3";
BA_ "Confidence" SG_ 1486 PARK_sw087_s11_sensorType 1;
BA_ "GenSigSNA" SG_ 1486 PARK_sw087_s11_sensorType "3";
BA_ "Confidence" SG_ 1486 PARK_sw087_s12_sensorType 1;
BA_ "GenSigSNA" SG_ 1486 PARK_sw087_s12_sensorType "3";
BA_ "Confidence" SG_ 806 PARK_infoIndex 1;
BA_ "Confidence" SG_ 806 PARK_infoBuildType 1;
BA_ "Confidence" SG_ 846 PARK_frontLeftMiddleRawDistData 1;
BA_ "GenSigSNA" SG_ 846 PARK_frontLeftMiddleRawDistData "255";
BA_ "Confidence" SG_ 846 PARK_frontMiddleRawDistData 1;
BA_ "GenSigSNA" SG_ 846 PARK_frontMiddleRawDistData "255";
BA_ "Confidence" SG_ 846 PARK_frontRightMiddleRawDistData 1;
BA_ "GenSigSNA" SG_ 846 PARK_frontRightMiddleRawDistData "255";
BA_ "Confidence" SG_ 862 PARK_rearLeftMiddleRawDistData 1;
BA_ "GenSigSNA" SG_ 862 PARK_rearLeftMiddleRawDistData "255";
BA_ "Confidence" SG_ 862 PARK_rearMiddleRawDistData 1;
BA_ "GenSigSNA" SG_ 862 PARK_rearMiddleRawDistData "255";
BA_ "Confidence" SG_ 862 PARK_rearRightMiddleRawDistData 1;
BA_ "GenSigSNA" SG_ 862 PARK_rearRightMiddleRawDistData "255";
BA_ "Confidence" SG_ 926 PARK_rightSideFrontRawDistData 1;
BA_ "GenSigSNA" SG_ 926 PARK_rightSideFrontRawDistData "255";
BA_ "Confidence" SG_ 926 PARK_rightSideRearRawDistData 1;
BA_ "GenSigSNA" SG_ 926 PARK_rightSideRearRawDistData "255";
BA_ "Confidence" SG_ 926 PARK_leftSideFrontRawDistData 1;
BA_ "GenSigSNA" SG_ 926 PARK_leftSideFrontRawDistData "255";
BA_ "Confidence" SG_ 926 PARK_leftSideRearRawDistData 1;
BA_ "GenSigSNA" SG_ 926 PARK_leftSideRearRawDistData "255";
BA_ "Confidence" SG_ 606 PARK_pscEnvSlotType 1;
BA_ "Confidence" SG_ 606 PARK_pscLeftParallelObj1X 1;
BA_ "GenSigSNA" SG_ 606 PARK_pscLeftParallelObj1X "2047";
BA_ "Confidence" SG_ 606 PARK_pscLeftParallelObj1Y 1;
BA_ "GenSigSNA" SG_ 606 PARK_pscLeftParallelObj1Y "2047";
BA_ "Confidence" SG_ 606 PARK_pscLeftParallelObj1Alpha 1;
BA_ "GenSigSNA" SG_ 606 PARK_pscLeftParallelObj1Alpha "127";
BA_ "Confidence" SG_ 606 PARK_pscLeftParallelObj2Y 1;
BA_ "GenSigSNA" SG_ 606 PARK_pscLeftParallelObj2Y "2047";
BA_ "Confidence" SG_ 606 PARK_pscLeftParallelObj2X 1;
BA_ "GenSigSNA" SG_ 606 PARK_pscLeftParallelObj2X "2047";
BA_ "Confidence" SG_ 606 PARK_pscLeftParallelObj2Alpha 1;
BA_ "GenSigSNA" SG_ 606 PARK_pscLeftParallelObj2Alpha "127";
BA_ "Confidence" SG_ 606 PARK_pscLeftCrossObj1X 1;
BA_ "GenSigSNA" SG_ 606 PARK_pscLeftCrossObj1X "2047";
BA_ "Confidence" SG_ 606 PARK_pscLeftCrossObj1Y 1;
BA_ "GenSigSNA" SG_ 606 PARK_pscLeftCrossObj1Y "2047";
BA_ "Confidence" SG_ 606 PARK_pscLeftCrossObj1Alpha 1;
BA_ "GenSigSNA" SG_ 606 PARK_pscLeftCrossObj1Alpha "127";
BA_ "Confidence" SG_ 606 PARK_pscLeftCrossObj2Y 1;
BA_ "GenSigSNA" SG_ 606 PARK_pscLeftCrossObj2Y "2047";
BA_ "Confidence" SG_ 606 PARK_pscLeftCrossObj2X 1;
BA_ "GenSigSNA" SG_ 606 PARK_pscLeftCrossObj2X "2047";
BA_ "Confidence" SG_ 606 PARK_pscLeftCrossObj2Alpha 1;
BA_ "GenSigSNA" SG_ 606 PARK_pscLeftCrossObj2Alpha "127";
BA_ "Confidence" SG_ 606 PARK_pscRightParallelObj1X 1;
BA_ "GenSigSNA" SG_ 606 PARK_pscRightParallelObj1X "2047";
BA_ "Confidence" SG_ 606 PARK_pscRightParallelObj1Y 1;
BA_ "GenSigSNA" SG_ 606 PARK_pscRightParallelObj1Y "2047";
BA_ "Confidence" SG_ 606 PARK_pscRightParallelObj1Alpha 1;
BA_ "GenSigSNA" SG_ 606 PARK_pscRightParallelObj1Alpha "127";
BA_ "Confidence" SG_ 606 PARK_pscRightParallelObj2Y 1;
BA_ "GenSigSNA" SG_ 606 PARK_pscRightParallelObj2Y "2047";
BA_ "Confidence" SG_ 606 PARK_pscRightParallelObj2X 1;
BA_ "GenSigSNA" SG_ 606 PARK_pscRightParallelObj2X "2047";
BA_ "Confidence" SG_ 606 PARK_pscRightParallelObj2Alpha 1;
BA_ "GenSigSNA" SG_ 606 PARK_pscRightParallelObj2Alpha "127";
BA_ "Confidence" SG_ 606 PARK_pscRightCrossObj1X 1;
BA_ "GenSigSNA" SG_ 606 PARK_pscRightCrossObj1X "2047";
BA_ "Confidence" SG_ 606 PARK_pscRightCrossObj1Y 1;
BA_ "GenSigSNA" SG_ 606 PARK_pscRightCrossObj1Y "2047";
BA_ "Confidence" SG_ 606 PARK_pscRightCrossObj1Alpha 1;
BA_ "GenSigSNA" SG_ 606 PARK_pscRightCrossObj1Alpha "127";
BA_ "Confidence" SG_ 606 PARK_pscRightCrossObj2Y 1;
BA_ "GenSigSNA" SG_ 606 PARK_pscRightCrossObj2Y "2047";
BA_ "Confidence" SG_ 606 PARK_pscRightCrossObj2X 1;
BA_ "GenSigSNA" SG_ 606 PARK_pscRightCrossObj2X "2047";
BA_ "Confidence" SG_ 606 PARK_pscRightCrossObj2Alpha 1;
BA_ "GenSigSNA" SG_ 606 PARK_pscRightCrossObj2Alpha "127";
BA_ "Confidence" SG_ 542 PARK_pscParkStatus 1;
BA_ "GenSigSNA" SG_ 542 PARK_pscParkStatus "7";
BA_ "Confidence" SG_ 542 PARK_pscParkAbortReason 1;
BA_ "GenSigSNA" SG_ 542 PARK_pscParkAbortReason "31";
BA_ "Confidence" SG_ 542 PARK_pscParallelSpace 1;
BA_ "Confidence" SG_ 542 PARK_pscCrossSpace 1;
BA_ "Confidence" SG_ 542 PARK_pscParallelRightParkable 1;
BA_ "GenSigSNA" SG_ 542 PARK_pscParallelRightParkable "3";
BA_ "Confidence" SG_ 542 PARK_pscParallelLeftParkable 1;
BA_ "GenSigSNA" SG_ 542 PARK_pscParallelLeftParkable "3";
BA_ "Confidence" SG_ 542 PARK_pscCrossRightParkable 1;
BA_ "GenSigSNA" SG_ 542 PARK_pscCrossRightParkable "3";
BA_ "Confidence" SG_ 542 PARK_pscMaxVelocity 1;
BA_ "GenSigSNA" SG_ 542 PARK_pscMaxVelocity "63";
BA_ "Confidence" SG_ 542 PARK_pscCrossLeftParkable 1;
BA_ "GenSigSNA" SG_ 542 PARK_pscCrossLeftParkable "3";
BA_ "Confidence" SG_ 542 PARK_pscParkInstruction 1;
BA_ "GenSigSNA" SG_ 542 PARK_pscParkInstruction "7";
BA_ "Confidence" SG_ 542 PARK_pscManeuverDistance 1;
BA_ "GenSigSNA" SG_ 542 PARK_pscManeuverDistance "2047";
BA_ "Confidence" SG_ 542 PARK_pscAngleActive 1;
BA_ "Confidence" SG_ 542 PARK_pscAngleRequest 1;
BA_ "Confidence" SG_ 590 PARK_pscVehSlotType 1;
BA_ "Confidence" SG_ 590 PARK_pscLeftParallelVehX 1;
BA_ "GenSigSNA" SG_ 590 PARK_pscLeftParallelVehX "2047";
BA_ "Confidence" SG_ 590 PARK_pscLeftParallelVehY 1;
BA_ "GenSigSNA" SG_ 590 PARK_pscLeftParallelVehY "2047";
BA_ "Confidence" SG_ 590 PARK_pscLeftParallelPsi 1;
BA_ "GenSigSNA" SG_ 590 PARK_pscLeftParallelPsi "8191";
BA_ "Confidence" SG_ 590 PARK_pscLeftParallelSizeX 1;
BA_ "GenSigSNA" SG_ 590 PARK_pscLeftParallelSizeX "255";
BA_ "Confidence" SG_ 590 PARK_pscLeftParallelSizeY 1;
BA_ "GenSigSNA" SG_ 590 PARK_pscLeftParallelSizeY "255";
BA_ "Confidence" SG_ 590 PARK_pscLeftCrossVehX 1;
BA_ "GenSigSNA" SG_ 590 PARK_pscLeftCrossVehX "2047";
BA_ "Confidence" SG_ 590 PARK_pscLeftCrossVehY 1;
BA_ "GenSigSNA" SG_ 590 PARK_pscLeftCrossVehY "2047";
BA_ "Confidence" SG_ 590 PARK_pscLeftCrossPsi 1;
BA_ "GenSigSNA" SG_ 590 PARK_pscLeftCrossPsi "8191";
BA_ "Confidence" SG_ 590 PARK_pscLeftCrossSizeX 1;
BA_ "GenSigSNA" SG_ 590 PARK_pscLeftCrossSizeX "255";
BA_ "Confidence" SG_ 590 PARK_pscLeftCrossSizeY 1;
BA_ "GenSigSNA" SG_ 590 PARK_pscLeftCrossSizeY "255";
BA_ "Confidence" SG_ 590 PARK_pscRightParallelVehX 1;
BA_ "GenSigSNA" SG_ 590 PARK_pscRightParallelVehX "2047";
BA_ "Confidence" SG_ 590 PARK_pscRightParallelVehY 1;
BA_ "GenSigSNA" SG_ 590 PARK_pscRightParallelVehY "2047";
BA_ "Confidence" SG_ 590 PARK_pscRightParallelPsi 1;
BA_ "GenSigSNA" SG_ 590 PARK_pscRightParallelPsi "8191";
BA_ "Confidence" SG_ 590 PARK_pscRightParallelSizeX 1;
BA_ "GenSigSNA" SG_ 590 PARK_pscRightParallelSizeX "255";
BA_ "Confidence" SG_ 590 PARK_pscRightParallelSizeY 1;
BA_ "GenSigSNA" SG_ 590 PARK_pscRightParallelSizeY "255";
BA_ "Confidence" SG_ 590 PARK_pscRightCrossVehX 1;
BA_ "GenSigSNA" SG_ 590 PARK_pscRightCrossVehX "2047";
BA_ "Confidence" SG_ 590 PARK_pscRightCrossVehY 1;
BA_ "GenSigSNA" SG_ 590 PARK_pscRightCrossVehY "2047";
BA_ "Confidence" SG_ 590 PARK_pscRightCrossPsi 1;
BA_ "GenSigSNA" SG_ 590 PARK_pscRightCrossPsi "8191";
BA_ "Confidence" SG_ 590 PARK_pscRightCrossSizeX 1;
BA_ "GenSigSNA" SG_ 590 PARK_pscRightCrossSizeX "255";
BA_ "Confidence" SG_ 590 PARK_pscRightCrossSizeY 1;
BA_ "GenSigSNA" SG_ 590 PARK_pscRightCrossSizeY "255";
BA_ "Confidence" SG_ 526 PARK_sdiSensor1RawDistData 1;
BA_ "GenSigSNA" SG_ 526 PARK_sdiSensor1RawDistData "511";
BA_ "Confidence" SG_ 526 PARK_sdiSensor2RawDistData 1;
BA_ "GenSigSNA" SG_ 526 PARK_sdiSensor2RawDistData "511";
BA_ "Confidence" SG_ 526 PARK_sdiSensor3RawDistData 1;
BA_ "GenSigSNA" SG_ 526 PARK_sdiSensor3RawDistData "511";
BA_ "Confidence" SG_ 526 PARK_sdiSensor4RawDistData 1;
BA_ "GenSigSNA" SG_ 526 PARK_sdiSensor4RawDistData "511";
BA_ "Confidence" SG_ 526 PARK_sdiSensor5RawDistData 1;
BA_ "GenSigSNA" SG_ 526 PARK_sdiSensor5RawDistData "511";
BA_ "Confidence" SG_ 526 PARK_sdiSensor6RawDistData 1;
BA_ "GenSigSNA" SG_ 526 PARK_sdiSensor6RawDistData "511";
BA_ "Confidence" SG_ 558 PARK_sdiSensor7RawDistData 1;
BA_ "GenSigSNA" SG_ 558 PARK_sdiSensor7RawDistData "511";
BA_ "Confidence" SG_ 558 PARK_sdiSensor8RawDistData 1;
BA_ "GenSigSNA" SG_ 558 PARK_sdiSensor8RawDistData "511";
BA_ "Confidence" SG_ 558 PARK_sdiSensor9RawDistData 1;
BA_ "GenSigSNA" SG_ 558 PARK_sdiSensor9RawDistData "511";
BA_ "Confidence" SG_ 558 PARK_sdiSensor10RawDistData 1;
BA_ "GenSigSNA" SG_ 558 PARK_sdiSensor10RawDistData "511";
BA_ "Confidence" SG_ 558 PARK_sdiSensor11RawDistData 1;
BA_ "GenSigSNA" SG_ 558 PARK_sdiSensor11RawDistData "511";
BA_ "Confidence" SG_ 558 PARK_sdiSensor12RawDistData 1;
BA_ "GenSigSNA" SG_ 558 PARK_sdiSensor12RawDistData "511";
BA_ "Confidence" SG_ 814 PARK_frontRightSensorState 1;
BA_ "GenSigSNA" SG_ 814 PARK_frontRightSensorState "3";
BA_ "Confidence" SG_ 814 PARK_frontRightMiddleSensorState 1;
BA_ "GenSigSNA" SG_ 814 PARK_frontRightMiddleSensorState "3";
BA_ "Confidence" SG_ 814 PARK_frontLeftMiddleSensorState 1;
BA_ "GenSigSNA" SG_ 814 PARK_frontLeftMiddleSensorState "3";
BA_ "Confidence" SG_ 814 PARK_frontLeftSensorState 1;
BA_ "GenSigSNA" SG_ 814 PARK_frontLeftSensorState "3";
BA_ "Confidence" SG_ 814 PARK_frontLeftRawDistData 1;
BA_ "GenSigSNA" SG_ 814 PARK_frontLeftRawDistData "255";
BA_ "Confidence" SG_ 814 PARK_frontRightRawDistData 1;
BA_ "GenSigSNA" SG_ 814 PARK_frontRightRawDistData "255";
BA_ "Confidence" SG_ 814 PARK_systemStatusFront 1;
BA_ "GenSigSNA" SG_ 814 PARK_systemStatusFront "3";
BA_ "Confidence" SG_ 814 PARK_frontDtcPresent 1;
BA_ "GenSigSNA" SG_ 814 PARK_frontDtcPresent "3";
BA_ "Confidence" SG_ 830 PARK_rearRightSensorState 1;
BA_ "GenSigSNA" SG_ 830 PARK_rearRightSensorState "3";
BA_ "Confidence" SG_ 830 PARK_rearRightMiddleSensorState 1;
BA_ "GenSigSNA" SG_ 830 PARK_rearRightMiddleSensorState "3";
BA_ "Confidence" SG_ 830 PARK_rearLeftMiddleSensorState 1;
BA_ "GenSigSNA" SG_ 830 PARK_rearLeftMiddleSensorState "3";
BA_ "Confidence" SG_ 830 PARK_rearLeftSensorState 1;
BA_ "GenSigSNA" SG_ 830 PARK_rearLeftSensorState "3";
BA_ "Confidence" SG_ 830 PARK_rearLeftRawDistData 1;
BA_ "GenSigSNA" SG_ 830 PARK_rearLeftRawDistData "255";
BA_ "Confidence" SG_ 830 PARK_rearRightRawDistData 1;
BA_ "GenSigSNA" SG_ 830 PARK_rearRightRawDistData "255";
BA_ "Confidence" SG_ 830 PARK_systemStatusRear 1;
BA_ "GenSigSNA" SG_ 830 PARK_systemStatusRear "3";
BA_ "Confidence" SG_ 830 PARK_rearDtcPresent 1;
BA_ "GenSigSNA" SG_ 830 PARK_rearDtcPresent "3";
BA_ "Confidence" SG_ 798 PARK_status 1;
BA_ "GenSigSNA" SG_ 798 PARK_status "3";
BA_ "Confidence" SG_ 798 PARK_serviceRequest 1;
BA_ "GenSigSNA" SG_ 798 PARK_serviceRequest "3";
BA_ "Confidence" SG_ 798 PARK_systemDtcPresent 1;
BA_ "GenSigSNA" SG_ 798 PARK_systemDtcPresent "3";
BA_ "Confidence" SG_ 798 PARK_majorVersion 1;
BA_ "GenSigSNA" SG_ 798 PARK_majorVersion "255";
BA_ "Confidence" SG_ 798 PARK_minorVersion 1;
BA_ "GenSigSNA" SG_ 798 PARK_minorVersion "255";
BA_ "Confidence" SG_ 798 PARK_subMinorVersion 1;
BA_ "GenSigSNA" SG_ 798 PARK_subMinorVersion "255";
BA_ "Confidence" SG_ 782 PARK_pscRightCurbType 1;
BA_ "Confidence" SG_ 782 PARK_pscLeftCurbType 1;
BA_ "Confidence" SG_ 782 PARK_autoCalComplete 1;
BA_ "Confidence" SG_ 782 PARK_geometryType 1;
BA_ "Confidence" SG_ 782 PARK_tireFitment 1;
BA_ "GenSigSNA" SG_ 782 PARK_tireFitment "3";
BA_ "Confidence" SG_ 782 PARK_rackDetected 1;
BA_ "GenSigSNA" SG_ 782 PARK_rackDetected "3";
BA_ "Confidence" SG_ 782 PARK_sdiActive 1;
BA_ "Confidence" SG_ 782 PARK_sdiNoise 1;
BA_ "GenSigSNA" SG_ 782 PARK_sdiNoise "3";
BA_ "Confidence" SG_ 782 PARK_sdiBlindSpotRight 1;
BA_ "GenSigSNA" SG_ 782 PARK_sdiBlindSpotRight "3";
BA_ "Confidence" SG_ 782 PARK_sdiBlindSpotLeft 1;
BA_ "GenSigSNA" SG_ 782 PARK_sdiBlindSpotLeft "3";
BA_ "Confidence" SG_ 782 PARK_sensorType 1;
BA_ "GenSigSNA" SG_ 782 PARK_sensorType "3";
BA_ "Confidence" SG_ 894 PARK_matrixIndex 1;
VAL_ 586 DAS_autosteerVehiclesUsage 3 "BLACKLISTED" 2 "FUSED" 1 "AVAILABLE" 0 "REJECTED_UNAVAILABLE" ;
VAL_ 586 DAS_autosteerHPPUsage 3 "BLACKLISTED" 2 "FUSED" 1 "AVAILABLE" 0 "REJECTED_UNAVAILABLE" ;
VAL_ 586 DAS_autosteerNavigationUsage 3 "BLACKLISTED" 2 "FUSED" 1 "AVAILABLE" 0 "REJECTED_UNAVAILABLE" ;
VAL_ 586 DAS_autosteerModelUsage 3 "BLACKLISTED" 2 "FUSED" 1 "AVAILABLE" 0 "REJECTED_UNAVAILABLE" ;
VAL_ 586 DAS_autosteerBottsDotsUsage 3 "BLACKLISTED" 2 "FUSED" 1 "AVAILABLE" 0 "REJECTED_UNAVAILABLE" ;
VAL_ 586 DAS_offsetSide 3 "OFFSET_BOTH_OBJECTS" 2 "OFFSET_LEFT_OBJECT" 1 "OFFSET_RIGHT_OBJECT" 0 "NO_OFFSET" ;
VAL_ 586 DAS_roadSurfaceType 2 "ROAD_SURFACE_ENHANCED" 1 "ROAD_SURFACE_NORMAL" 0 "ROAD_SURFACE_SNA" ;
VAL_ 586 DAS_autosteerHealthState 5 "HEALTH_FAULT" 4 "HEALTH_ABORTING" 3 "HEALTH_SEVERELY_DEGRADED" 2 "HEALTH_DEGRADED" 1 "HEALTH_NOMINAL" 0 "HEALTH_UNAVAILABLE" ;
VAL_ 586 DAS_lastLinePreferenceReason 15 "NONE" 5 "COUNTRY_DRIVING_SIDE" 4 "AVOID_ONCOMING_LANES" 3 "NAVIGATION_BRANCH" 2 "NEIGHBOR_LANE_PROBABILIY" 1 "AGREEMENT_WITH_NEIGHBOR_LANES" 0 "OTHER_LANE_DISAGREES_WITH_MODEL" ;
VAL_ 586 DAS_plannerState 7 "TP_EXTSTATE_LANECHANGE_ABORT" 6 "TP_EXTSTATE_LANECHANGE_WAIT_FOR_FWD_OBSTACLE" 5 "TP_EXTSTATE_LANECHANGE_WAIT_FOR_SIDE_OBSTACLE" 4 "TP_EXTSTATE_LANECHANGE_IN_PROGRESS" 3 "TP_EXTSTATE_LANECHANGE_REQUESTED" 2 "TP_EXTSTATE_FOLLOW" 1 "TP_EXTSTATE_VL" 0 "TP_EXTSTATE_DISABLED" ;
VAL_ 586 DAS_lastAutosteerAbortReason 36 "UI_ABORT_REASON_AHB_MANUAL_OVERRIDE" 35 "UI_ABORT_REASON_DRIVER_NOT_PRESENT" 34 "UI_ABORT_REASON_USER_OVERRIDE_STRIKEOUT" 33 "UI_ABORT_REASON_SEATBELT_UNBUCKLED" 32 "UI_ABORT_REASON_AEB" 31 "UI_ABORT_REASON_NO_ABORT" 30 "UI_ABORT_REASON_CAMERA_FAILSAFES" 29 "UI_ABORT_REASON_ACC_CANCEL" 28 "UI_ABORT_REASON_EPAS_ERROR_CODE" 27 "UI_ABORT_REASON_PLANNER_OUTPUT_INVALID" 26 "UI_ABORT_REASON_FOLLOWER_OUTPUT_INVALID" 25 "UI_ABORT_REASON_VEHICLE_SPEED_ABOVE_MAX" 24 "UI_ABORT_REASON_DRIVING_OFF_NAV" 23 "UI_ABORT_REASON_CID_SWITCH_DISABLED" 22 "UI_ABORT_REASON_CRUISE_FAULT" 21 "UI_ABORT_REASON_COMPONENT_MIA" 20 "UI_ABORT_REASON_EPAS_EAC_DENIED" 19 "UI_ABORT_REASON_SIDE_COLLISION_IMMINENT" 18 "UI_ABORT_REASON_TRAILER_MODE" 17 "UI_ABORT_REASON_CAM_WATCHDOG" 16 "UI_ABORT_REASON_CAM_MSG_MIA" 15 "UI_ABORT_REASON_ME_MAIN_STATE_NOT_VISION" 14 "UI_ABORT_REASON_APP_ME_STATE_NOT_VISION" 2 "UI_ABORT_REASON_HM_STEERING_ERROR" 1 "UI_ABORT_REASON_HM_VIRTUAL_LANE_NO_INPUTS" 0 "UI_ABORT_REASON_HM_LANE_VIEW_RANGE" ;
VAL_ 586 DAS_navAvailable 1 "DAS_NAV_AVAILABLE" 0 "DAS_NAV_UNAVAILABLE" ;
VAL_ 586 DAS_accSmartSpeedState 7 "SNA" 5 "OFFRAMP_DELAY" 4 "SET_SPEED_SET_REQUESTED" 3 "ACTIVE_ONRAMP" 2 "ACTIVE_INTEGRATING" 1 "ACTIVE_OFFRAMP" 0 "NOT_ACTIVE" ;
VAL_ 586 DAS_ulcInProgress 1 "ULC_ACTIVE" 0 "ULC_INACTIVE" ;
VAL_ 586 DAS_isaSystemState 3 "ISA_UNAVAILABLE" 2 "ISA_INVALID" 1 "ISA_ASSUMED_LIMITS" 0 "ISA_NOMINAL" ;
VAL_ 586 DAS_behaviorType 3 "DAS_BEHAVIOR_LANE_CHANGE_RIGHT" 2 "DAS_BEHAVIOR_LANE_CHANGE_LEFT" 1 "DAS_BEHAVIOR_IN_LANE" 0 "DAS_BEHAVIOR_INVALID" ;
VAL_ 586 DAS_ulcType 2 "ULC_TYPE_SPEED" 1 "ULC_TYPE_NAV" 0 "ULC_TYPE_NONE" ;
VAL_ 586 DAS_rearVehDetectedThisCycle 1 "VEHICLE_DETECTED" 0 "VEHICLE_NOT_DETECTED" ;
VAL_ 586 DAS_rearLeftVehDetectedCurrent 1 "VEHICLE_DETECTED" 0 "VEHICLE_NOT_DETECTED" ;
VAL_ 586 DAS_rearRightVehDetectedTrip 1 "VEHICLE_DETECTED" 0 "VEHICLE_NOT_DETECTED" ;
VAL_ 586 DAS_rearLeftVehDetectedTrip 1 "VEHICLE_DETECTED" 0 "VEHICLE_NOT_DETECTED" ;
VAL_ 977 EPAS3S_resyncStatus 1 "RESYNC_COMPLETE" 0 "RESYNC_PENDING" ;
VAL_ 785 EPAS3S_infoIndex 255 "END" 31 "SUBCOMPONENT_GITHASH" 30 "PACKAGE_SN_8_14" 29 "PACKAGE_SN_1_7" 27 "PACKAGE_PN_15_20" 26 "PACKAGE_PN_8_14" 25 "PACKAGE_PN_1_7" 23 "SUBCOMPONENT2" 22 "VARIANTCRC" 20 "UDS_PROTOCOL_BOOTCRC" 19 "VERSION_DEPRECATED" 18 "BOOTLOADER_GITHASH" 17 "APP_GITHASH" 16 "SUBCOMPONENT" 15 "BOOTLOADER_CRC" 14 "BOOTLOADER_SVN" 13 "APP_CRC" 11 "PCBAID_ASSYID_USAGEID" 10 "BUILD_HWID_COMPONENTID" 9 "DEPRECATED_9" 8 "DEPRECATED_8" 7 "DEPRECATED_7" 6 "DEPRECATED_6" 5 "DEPRECATED_5" 4 "DEPRECATED_4" 3 "DEPRECATED_3" 2 "DEPRECATED_2" 1 "DEPRECATED_1" 0 "DEPRECATED_0" ;
VAL_ 785 EPAS3S_infoBuildType 4 "INFO_MFG_BUILD" 3 "INFO_TRACEABLE_CI_BUILD" 2 "INFO_LOCAL_BUILD" 1 "INFO_PLATFORM_BUILD" 0 "INFO_UNKNOWN_BUILD" ;
VAL_ 805 ESP_infoIndex 255 "END" 31 "SUBCOMPONENT_GITHASH" 30 "PACKAGE_SN_8_14" 29 "PACKAGE_SN_1_7" 27 "PACKAGE_PN_15_20" 26 "PACKAGE_PN_8_14" 25 "PACKAGE_PN_1_7" 23 "SUBCOMPONENT2" 22 "VARIANTCRC" 20 "UDS_PROTOCOL_BOOTCRC" 19 "VERSION_DEPRECATED" 18 "BOOTLOADER_GITHASH" 17 "APP_GITHASH" 16 "SUBCOMPONENT" 15 "BOOTLOADER_CRC" 14 "BOOTLOADER_SVN" 13 "APP_CRC" 11 "PCBAID_ASSYID_USAGEID" 10 "BUILD_HWID_COMPONENTID" 9 "DEPRECATED_9" 8 "DEPRECATED_8" 7 "DEPRECATED_7" 6 "DEPRECATED_6" 5 "DEPRECATED_5" 4 "DEPRECATED_4" 3 "DEPRECATED_3" 2 "DEPRECATED_2" 1 "DEPRECATED_1" 0 "DEPRECATED_0" ;
VAL_ 805 ESP_infoBuildType 4 "INFO_MFG_BUILD" 3 "INFO_TRACEABLE_CI_BUILD" 2 "INFO_LOCAL_BUILD" 1 "INFO_PLATFORM_BUILD" 0 "INFO_UNKNOWN_BUILD" ;
VAL_ 805 ESP_vehFlashMode 1 "Development_Mode" 0 "Production_Mode" ;
VAL_ 805 ESP_infoSubUsageID 16 "XCP_Dfive_ESP_CP_CB" 8 "nonXCP_Dfour_ESP_CP_CB" 4 "XCP_Gladiator_ESP" 2 "nonXCP_Rev_C_ESP_Cappella" 0 "nonXCP_Rev_B_ESP_Cappella" ;
VAL_ 805 ESP_infoVehicleVariant 9 "MODEL_3_VARIANT_09" 8 "MODEL_3_VARIANT_08" 7 "MODEL_3_VARIANT_07" 6 "MODEL_3_VARIANT_06" 5 "MODEL_3_VARIANT_05" 4 "MODEL_3_VARIANT_04" 3 "MODEL_3_VARIANT_03" 2 "MODEL_3_VARIANT_02" 1 "MODEL_3_VARIANT_01" ;
VAL_ 813 IBST_infoIndex 255 "END" 31 "SUBCOMPONENT_GITHASH" 30 "PACKAGE_SN_8_14" 29 "PACKAGE_SN_1_7" 27 "PACKAGE_PN_15_20" 26 "PACKAGE_PN_8_14" 25 "PACKAGE_PN_1_7" 23 "SUBCOMPONENT2" 22 "VARIANTCRC" 20 "UDS_PROTOCOL_BOOTCRC" 19 "VERSION_DEPRECATED" 18 "BOOTLOADER_GITHASH" 17 "APP_GITHASH" 16 "SUBCOMPONENT" 15 "BOOTLOADER_CRC" 14 "BOOTLOADER_SVN" 13 "APP_CRC" 11 "PCBAID_ASSYID_USAGEID" 10 "BUILD_HWID_COMPONENTID" 9 "DEPRECATED_9" 8 "DEPRECATED_8" 7 "DEPRECATED_7" 6 "DEPRECATED_6" 5 "DEPRECATED_5" 4 "DEPRECATED_4" 3 "DEPRECATED_3" 2 "DEPRECATED_2" 1 "DEPRECATED_1" 0 "DEPRECATED_0" ;
VAL_ 813 IBST_infoBuildType 4 "INFO_MFG_BUILD" 3 "INFO_TRACEABLE_CI_BUILD" 2 "INFO_LOCAL_BUILD" 1 "INFO_PLATFORM_BUILD" 0 "INFO_UNKNOWN_BUILD" ;
VAL_ 1486 PARK_alertID 87 "a087_sensorMismatchError" 86 "a086_nvmFault" 85 "a085_watchdogReset" 84 "a084_sccmError" 83 "a083_vcFrontError" 82 "a082_rcmError" 81 "a081_espError" 80 "a080_epbError" 79 "a079_epasError" 78 "a078_diError" 77 "a077_dasError" 76 "a076_vcFrontMia" 75 "a075_rcmMia" 74 "a074_espMia" 73 "a073_epbMia" 72 "a072_epasMia" 71 "a071_diMia" 70 "a070_sccmMia" 69 "a069_dasMia" 68 "a068_hardwareWatchDog" 67 "a067_privateCANBusOff" 66 "a066_calibrationMissing" 65 "a065_crcFault" 64 "a064_ecuFault" 63 "a063_sensorVoltage" 62 "a062_ecuOverVoltage" 61 "a061_ecuUnderVoltage" 60 "a060_s12_crossTalk" 59 "a059_s12_blocked" 58 "a058_s12_linCommError" 57 "a057_s12_internalFail" 56 "a056_s12_overTemp" 55 "a055_s11_crossTalk" 54 "a054_s11_blocked" 53 "a053_s11_linCommError" 52 "a052_s11_internalFail" 51 "a051_s11_overTemp" 50 "a050_s10_crossTalk" 49 "a049_s10_blocked" 48 "a048_s10_linCommError" 47 "a047_s10_internalFail" 46 "a046_s10_overTemp" 45 "a045_s9_crossTalk" 44 "a044_s9_blocked" 43 "a043_s9_linCommError" 42 "a042_s9_internalFail" 41 "a041_s9_overTemp" 40 "a040_s8_crossTalk" 39 "a039_s8_blocked" 38 "a038_s8_linCommError" 37 "a037_s8_internalFail" 36 "a036_s8_overTemp" 35 "a035_s7_crossTalk" 34 "a034_s7_blocked" 33 "a033_s7_linCommError" 32 "a032_s7_internalFail" 31 "a031_s7_overTemp" 30 "a030_s6_crossTalk" 29 "a029_s6_blocked" 28 "a028_s6_linCommError" 27 "a027_s6_internalFail" 26 "a026_s6_overTemp" 25 "a025_s5_crossTalk" 24 "a024_s5_blocked" 23 "a023_s5_linCommError" 22 "a022_s5_internalFail" 21 "a021_s5_overTemp" 20 "a020_s4_crossTalk" 19 "a019_s4_blocked" 18 "a018_s4_linCommError" 17 "a017_s4_internalFail" 16 "a016_s4_overTemp" 15 "a015_s3_crossTalk" 14 "a014_s3_blocked" 13 "a013_s3_linCommError" 12 "a012_s3_internalFail" 11 "a011_s3_overTemp" 10 "a010_s2_crossTalk" 9 "a009_s2_blocked" 8 "a008_s2_linCommError" 7 "a007_s2_internalFail" 6 "a006_s2_overTemp" 5 "a005_s1_crossTalk" 4 "a004_s1_blocked" 3 "a003_s1_linCommError" 2 "a002_s1_internalFail" 1 "a001_s1_overTemp" 0 "ALERT_DO_NOT_USE_ZERO" ;
VAL_ 1486 PARK_alertState 1 "SET" 0 "CLEARED" ;
VAL_ 1486 PARK_sw077_errorType 5 "OVERRUN" 4 "INVALID_DATA" 3 "SEQUENCE" 2 "CHECKSUM" 1 "LENGTH" 0 "NONE" ;
VAL_ 1486 PARK_sw078_errorType 5 "OVERRUN" 4 "INVALID_DATA" 3 "SEQUENCE" 2 "CHECKSUM" 1 "LENGTH" 0 "NONE" ;
VAL_ 1486 PARK_sw079_errorType 5 "OVERRUN" 4 "INVALID_DATA" 3 "SEQUENCE" 2 "CHECKSUM" 1 "LENGTH" 0 "NONE" ;
VAL_ 1486 PARK_sw080_errorType 5 "OVERRUN" 4 "INVALID_DATA" 3 "SEQUENCE" 2 "CHECKSUM" 1 "LENGTH" 0 "NONE" ;
VAL_ 1486 PARK_sw081_errorType 5 "OVERRUN" 4 "INVALID_DATA" 3 "SEQUENCE" 2 "CHECKSUM" 1 "LENGTH" 0 "NONE" ;
VAL_ 1486 PARK_sw082_errorType 5 "OVERRUN" 4 "INVALID_DATA" 3 "SEQUENCE" 2 "CHECKSUM" 1 "LENGTH" 0 "NONE" ;
VAL_ 1486 PARK_sw083_errorType 5 "OVERRUN" 4 "INVALID_DATA" 3 "SEQUENCE" 2 "CHECKSUM" 1 "LENGTH" 0 "NONE" ;
VAL_ 1486 PARK_sw084_errorType 5 "OVERRUN" 4 "INVALID_DATA" 3 "SEQUENCE" 2 "CHECKSUM" 1 "LENGTH" 0 "NONE" ;
VAL_ 1486 PARK_sw087_s1_sensorType 3 "SNA" 2 "VALEO_HP" 1 "VALEO_HPFL" 0 "NONE" ;
VAL_ 1486 PARK_sw087_s2_sensorType 3 "SNA" 2 "VALEO_HP" 1 "VALEO_HPFL" 0 "NONE" ;
VAL_ 1486 PARK_sw087_s3_sensorType 3 "SNA" 2 "VALEO_HP" 1 "VALEO_HPFL" 0 "NONE" ;
VAL_ 1486 PARK_sw087_s4_sensorType 3 "SNA" 2 "VALEO_HP" 1 "VALEO_HPFL" 0 "NONE" ;
VAL_ 1486 PARK_sw087_s5_sensorType 3 "SNA" 2 "VALEO_HP" 1 "VALEO_HPFL" 0 "NONE" ;
VAL_ 1486 PARK_sw087_s6_sensorType 3 "SNA" 2 "VALEO_HP" 1 "VALEO_HPFL" 0 "NONE" ;
VAL_ 1486 PARK_sw087_s7_sensorType 3 "SNA" 2 "VALEO_HP" 1 "VALEO_HPFL" 0 "NONE" ;
VAL_ 1486 PARK_sw087_s8_sensorType 3 "SNA" 2 "VALEO_HP" 1 "VALEO_HPFL" 0 "NONE" ;
VAL_ 1486 PARK_sw087_s9_sensorType 3 "SNA" 2 "VALEO_HP" 1 "VALEO_HPFL" 0 "NONE" ;
VAL_ 1486 PARK_sw087_s10_sensorType 3 "SNA" 2 "VALEO_HP" 1 "VALEO_HPFL" 0 "NONE" ;
VAL_ 1486 PARK_sw087_s11_sensorType 3 "SNA" 2 "VALEO_HP" 1 "VALEO_HPFL" 0 "NONE" ;
VAL_ 1486 PARK_sw087_s12_sensorType 3 "SNA" 2 "VALEO_HP" 1 "VALEO_HPFL" 0 "NONE" ;
VAL_ 806 PARK_infoIndex 255 "END" 31 "SUBCOMPONENT_GITHASH" 30 "PACKAGE_SN_8_14" 29 "PACKAGE_SN_1_7" 27 "PACKAGE_PN_15_20" 26 "PACKAGE_PN_8_14" 25 "PACKAGE_PN_1_7" 23 "SUBCOMPONENT2" 22 "VARIANTCRC" 20 "UDS_PROTOCOL_BOOTCRC" 19 "VERSION_DEPRECATED" 18 "BOOTLOADER_GITHASH" 17 "APP_GITHASH" 16 "SUBCOMPONENT" 15 "BOOTLOADER_CRC" 14 "BOOTLOADER_SVN" 13 "APP_CRC" 11 "PCBAID_ASSYID_USAGEID" 10 "BUILD_HWID_COMPONENTID" 9 "DEPRECATED_9" 8 "DEPRECATED_8" 7 "DEPRECATED_7" 6 "DEPRECATED_6" 5 "DEPRECATED_5" 4 "DEPRECATED_4" 3 "DEPRECATED_3" 2 "DEPRECATED_2" 1 "DEPRECATED_1" 0 "DEPRECATED_0" ;
VAL_ 806 PARK_infoBuildType 4 "INFO_MFG_BUILD" 3 "INFO_TRACEABLE_CI_BUILD" 2 "INFO_LOCAL_BUILD" 1 "INFO_PLATFORM_BUILD" 0 "INFO_UNKNOWN_BUILD" ;
VAL_ 846 PARK_frontLeftMiddleRawDistData 255 "SNA" ;
VAL_ 846 PARK_frontMiddleRawDistData 255 "SNA" ;
VAL_ 846 PARK_frontRightMiddleRawDistData 255 "SNA" ;
VAL_ 862 PARK_rearLeftMiddleRawDistData 255 "SNA" ;
VAL_ 862 PARK_rearMiddleRawDistData 255 "SNA" ;
VAL_ 862 PARK_rearRightMiddleRawDistData 255 "SNA" ;
VAL_ 926 PARK_rightSideFrontRawDistData 255 "SNA" ;
VAL_ 926 PARK_rightSideRearRawDistData 255 "SNA" ;
VAL_ 926 PARK_leftSideFrontRawDistData 255 "SNA" ;
VAL_ 926 PARK_leftSideRearRawDistData 255 "SNA" ;
VAL_ 606 PARK_pscEnvSlotType 3 "RIGHT_CROSS" 2 "RIGHT_PARALLEL" 1 "LEFT_CROSS" 0 "LEFT_PARALLEL" ;
VAL_ 606 PARK_pscLeftParallelObj1X 2047 "SNA" 2046 "NO_SPACE" ;
VAL_ 606 PARK_pscLeftParallelObj1Y 2047 "SNA" 2046 "NO_SPACE" ;
VAL_ 606 PARK_pscLeftParallelObj1Alpha 127 "SNA" 126 "NO_SPACE" ;
VAL_ 606 PARK_pscLeftParallelObj2Y 2047 "SNA" 2046 "NO_SPACE" ;
VAL_ 606 PARK_pscLeftParallelObj2X 2047 "SNA" 2046 "NO_SPACE" ;
VAL_ 606 PARK_pscLeftParallelObj2Alpha 127 "SNA" 126 "NO_SPACE" ;
VAL_ 606 PARK_pscLeftCrossObj1X 2047 "SNA" 2046 "NO_SPACE" ;
VAL_ 606 PARK_pscLeftCrossObj1Y 2047 "SNA" 2046 "NO_SPACE" ;
VAL_ 606 PARK_pscLeftCrossObj1Alpha 127 "SNA" 126 "NO_SPACE" ;
VAL_ 606 PARK_pscLeftCrossObj2Y 2047 "SNA" 2046 "NO_SPACE" ;
VAL_ 606 PARK_pscLeftCrossObj2X 2047 "SNA" 2046 "NO_SPACE" ;
VAL_ 606 PARK_pscLeftCrossObj2Alpha 127 "SNA" 126 "NO_SPACE" ;
VAL_ 606 PARK_pscRightParallelObj1X 2047 "SNA" 2046 "NO_SPACE" ;
VAL_ 606 PARK_pscRightParallelObj1Y 2047 "SNA" 2046 "NO_SPACE" ;
VAL_ 606 PARK_pscRightParallelObj1Alpha 127 "SNA" 126 "NO_SPACE" ;
VAL_ 606 PARK_pscRightParallelObj2Y 2047 "SNA" 2046 "NO_SPACE" ;
VAL_ 606 PARK_pscRightParallelObj2X 2047 "SNA" 2046 "NO_SPACE" ;
VAL_ 606 PARK_pscRightParallelObj2Alpha 127 "SNA" 126 "NO_SPACE" ;
VAL_ 606 PARK_pscRightCrossObj1X 2047 "SNA" 2046 "NO_SPACE" ;
VAL_ 606 PARK_pscRightCrossObj1Y 2047 "SNA" 2046 "NO_SPACE" ;
VAL_ 606 PARK_pscRightCrossObj1Alpha 127 "SNA" 126 "NO_SPACE" ;
VAL_ 606 PARK_pscRightCrossObj2Y 2047 "SNA" 2046 "NO_SPACE" ;
VAL_ 606 PARK_pscRightCrossObj2X 2047 "SNA" 2046 "NO_SPACE" ;
VAL_ 606 PARK_pscRightCrossObj2Alpha 127 "SNA" 126 "NO_SPACE" ;
VAL_ 542 PARK_pscParkStatus 7 "SNA" 6 "FAULT" 5 "GUIDANCE_FINISHED" 4 "PRE_GUIDANCE" 3 "GUIDANCE_RIGHT" 2 "GUIDANCE_LEFT" 1 "SEARCHING" 0 "NOT_AVAILABLE" ;
VAL_ 542 PARK_pscParkAbortReason 31 "SNA" 25 "PSC_MOVEMENT_AT_ACTIVATION" 24 "PSC_MAX_WAY_BEHIND_HINT" 23 "PSC_PARK_STC_FAILED" 22 "PSC_PARK_PONR_NOT_REACHED" 21 "PSC_VCTL_GENERAL_ABORT" 20 "PSC_HIGH_TORQUE" 19 "PSC_ASYNC_CTRL_SYSTEM" 18 "ERROR" 17 "SYSTEM_SERVICE" 16 "SYSTEM_FAULT" 15 "ECU_INTERNAL_FAULT" 14 "DAS_ABORT" 13 "EPAS_FAULT" 12 "VEHICLE_DYNAMICS_INTERVENTION" 11 "HANDS_ON_DETECTED" 10 "FULL_WARNING_ON_BOTH_SIDES" 9 "PARK_SPACE_TOO_SMALL" 8 "OBSTACLE_ON_PATH" 7 "MAX_YAW_ANGLE_REACHED" 6 "MAX_SWA_DEV_EXCEEDED" 5 "OFF_TRACK" 4 "UNCONTROLLED_TRAVEL_DIST_REACHED" 3 "NO_VALID_PATH" 2 "MAX_NUM_OF_MOVES" 1 "VELOCITY_TOO_HIGH" 0 "NONE" ;
VAL_ 542 PARK_pscParallelSpace 3 "BOTH_AVAILABLE" 2 "LEFT_AVAILABLE" 1 "RIGHT_AVAILABLE" 0 "NONE_AVAILABLE" ;
VAL_ 542 PARK_pscCrossSpace 3 "BOTH_AVAILABLE" 2 "LEFT_AVAILABLE" 1 "RIGHT_AVAILABLE" 0 "NONE_AVAILABLE" ;
VAL_ 542 PARK_pscParallelRightParkable 3 "SNA" 2 "PARKING_SLOT_OK_POSITION_OK" 1 "PARKING_SLOT_OK" 0 "NONE" ;
VAL_ 542 PARK_pscParallelLeftParkable 3 "SNA" 2 "PARKING_SLOT_OK_POSITION_OK" 1 "PARKING_SLOT_OK" 0 "NONE" ;
VAL_ 542 PARK_pscCrossRightParkable 3 "SNA" 2 "PARKING_SLOT_OK_POSITION_OK" 1 "PARKING_SLOT_OK" 0 "NONE" ;
VAL_ 542 PARK_pscMaxVelocity 63 "SNA" ;
VAL_ 542 PARK_pscCrossLeftParkable 3 "SNA" 2 "PARKING_SLOT_OK_POSITION_OK" 1 "PARKING_SLOT_OK" 0 "NONE" ;
VAL_ 542 PARK_pscParkInstruction 7 "SNA" 5 "EXPLORATION" 4 "ABORTED" 3 "DRIVE_BACKWARD" 2 "DRIVE_FORWARD" 1 "STOP" 0 "NO_MESSAGE" ;
VAL_ 542 PARK_pscManeuverDistance 2047 "SNA" ;
VAL_ 542 PARK_pscAngleActive 1 "REQUEST_CONTROL" 0 "INACTIVE" ;
VAL_ 590 PARK_pscVehSlotType 3 "RIGHT_CROSS" 2 "RIGHT_PARALLEL" 1 "LEFT_CROSS" 0 "LEFT_PARALLEL" ;
VAL_ 590 PARK_pscLeftParallelVehX 2047 "SNA" 2046 "NO_SPACE" ;
VAL_ 590 PARK_pscLeftParallelVehY 2047 "SNA" 2046 "NO_SPACE" ;
VAL_ 590 PARK_pscLeftParallelPsi 8191 "SNA" 8190 "NO_SPACE" ;
VAL_ 590 PARK_pscLeftParallelSizeX 255 "SNA" 254 "NO_SPACE" ;
VAL_ 590 PARK_pscLeftParallelSizeY 255 "SNA" 254 "NO_SPACE" ;
VAL_ 590 PARK_pscLeftCrossVehX 2047 "SNA" 2046 "NO_SPACE" ;
VAL_ 590 PARK_pscLeftCrossVehY 2047 "SNA" 2046 "NO_SPACE" ;
VAL_ 590 PARK_pscLeftCrossPsi 8191 "SNA" 8190 "NO_SPACE" ;
VAL_ 590 PARK_pscLeftCrossSizeX 255 "SNA" 254 "NO_SPACE" ;
VAL_ 590 PARK_pscLeftCrossSizeY 255 "SNA" 254 "NO_SPACE" ;
VAL_ 590 PARK_pscRightParallelVehX 2047 "SNA" 2046 "NO_SPACE" ;
VAL_ 590 PARK_pscRightParallelVehY 2047 "SNA" 2046 "NO_SPACE" ;
VAL_ 590 PARK_pscRightParallelPsi 8191 "SNA" 8190 "NO_SPACE" ;
VAL_ 590 PARK_pscRightParallelSizeX 255 "SNA" 254 "NO_SPACE" ;
VAL_ 590 PARK_pscRightParallelSizeY 255 "SNA" 254 "NO_SPACE" ;
VAL_ 590 PARK_pscRightCrossVehX 2047 "SNA" 2046 "NO_SPACE" ;
VAL_ 590 PARK_pscRightCrossVehY 2047 "SNA" 2046 "NO_SPACE" ;
VAL_ 590 PARK_pscRightCrossPsi 8191 "SNA" 8190 "NO_SPACE" ;
VAL_ 590 PARK_pscRightCrossSizeX 255 "SNA" 254 "NO_SPACE" ;
VAL_ 590 PARK_pscRightCrossSizeY 255 "SNA" 254 "NO_SPACE" ;
VAL_ 526 PARK_sdiSensor1RawDistData 511 "SNA" 500 "NO_OBJECT_DETECTED" 1 "NEAR_DETECTION" 0 "BLOCKED" ;
VAL_ 526 PARK_sdiSensor2RawDistData 511 "SNA" 500 "NO_OBJECT_DETECTED" 1 "NEAR_DETECTION" 0 "BLOCKED" ;
VAL_ 526 PARK_sdiSensor3RawDistData 511 "SNA" 500 "NO_OBJECT_DETECTED" 1 "NEAR_DETECTION" 0 "BLOCKED" ;
VAL_ 526 PARK_sdiSensor4RawDistData 511 "SNA" 500 "NO_OBJECT_DETECTED" 1 "NEAR_DETECTION" 0 "BLOCKED" ;
VAL_ 526 PARK_sdiSensor5RawDistData 511 "SNA" 500 "NO_OBJECT_DETECTED" 1 "NEAR_DETECTION" 0 "BLOCKED" ;
VAL_ 526 PARK_sdiSensor6RawDistData 511 "SNA" 500 "NO_OBJECT_DETECTED" 1 "NEAR_DETECTION" 0 "BLOCKED" ;
VAL_ 558 PARK_sdiSensor7RawDistData 511 "SNA" 500 "NO_OBJECT_DETECTED" 1 "NEAR_DETECTION" 0 "BLOCKED" ;
VAL_ 558 PARK_sdiSensor8RawDistData 511 "SNA" 500 "NO_OBJECT_DETECTED" 1 "NEAR_DETECTION" 0 "BLOCKED" ;
VAL_ 558 PARK_sdiSensor9RawDistData 511 "SNA" 500 "NO_OBJECT_DETECTED" 1 "NEAR_DETECTION" 0 "BLOCKED" ;
VAL_ 558 PARK_sdiSensor10RawDistData 511 "SNA" 500 "NO_OBJECT_DETECTED" 1 "NEAR_DETECTION" 0 "BLOCKED" ;
VAL_ 558 PARK_sdiSensor11RawDistData 511 "SNA" 500 "NO_OBJECT_DETECTED" 1 "NEAR_DETECTION" 0 "BLOCKED" ;
VAL_ 558 PARK_sdiSensor12RawDistData 511 "SNA" 500 "NO_OBJECT_DETECTED" 1 "NEAR_DETECTION" 0 "BLOCKED" ;
VAL_ 814 PARK_frontRightSensorState 3 "SNA" 2 "TEMPORARY_FAILURE" 1 "PERMANENT_FAILURE" 0 "NO_FAILURE" ;
VAL_ 814 PARK_frontRightMiddleSensorState 3 "SNA" 2 "TEMPORARY_FAILURE" 1 "PERMANENT_FAILURE" 0 "NO_FAILURE" ;
VAL_ 814 PARK_frontLeftMiddleSensorState 3 "SNA" 2 "TEMPORARY_FAILURE" 1 "PERMANENT_FAILURE" 0 "NO_FAILURE" ;
VAL_ 814 PARK_frontLeftSensorState 3 "SNA" 2 "TEMPORARY_FAILURE" 1 "PERMANENT_FAILURE" 0 "NO_FAILURE" ;
VAL_ 814 PARK_frontLeftRawDistData 255 "SNA" ;
VAL_ 814 PARK_frontRightRawDistData 255 "SNA" ;
VAL_ 814 PARK_systemStatusFront 3 "SNA" 2 "UNUSED" 1 "ENABLED" 0 "DISABLED" ;
VAL_ 814 PARK_frontDtcPresent 3 "SNA" 2 "UNUSED" 1 "TRUE" 0 "FALSE" ;
VAL_ 830 PARK_rearRightSensorState 3 "SNA" 2 "TEMPORARY_FAILURE" 1 "PERMANENT_FAILURE" 0 "NO_FAILURE" ;
VAL_ 830 PARK_rearRightMiddleSensorState 3 "SNA" 2 "TEMPORARY_FAILURE" 1 "PERMANENT_FAILURE" 0 "NO_FAILURE" ;
VAL_ 830 PARK_rearLeftMiddleSensorState 3 "SNA" 2 "TEMPORARY_FAILURE" 1 "PERMANENT_FAILURE" 0 "NO_FAILURE" ;
VAL_ 830 PARK_rearLeftSensorState 3 "SNA" 2 "TEMPORARY_FAILURE" 1 "PERMANENT_FAILURE" 0 "NO_FAILURE" ;
VAL_ 830 PARK_rearLeftRawDistData 255 "SNA" ;
VAL_ 830 PARK_rearRightRawDistData 255 "SNA" ;
VAL_ 830 PARK_systemStatusRear 3 "SNA" 2 "UNUSED" 1 "ENABLED" 0 "DISABLED" ;
VAL_ 830 PARK_rearDtcPresent 3 "SNA" 2 "UNUSED" 1 "TRUE" 0 "FALSE" ;
VAL_ 798 PARK_status 3 "SNA" 2 "TEMPORARY_FAILURE" 1 "ENABLED" 0 "DISABLED" ;
VAL_ 798 PARK_serviceRequest 3 "SNA" 2 "UNUSED" 1 "FAILURE" 0 "NO_FAILURE" ;
VAL_ 798 PARK_systemDtcPresent 3 "SNA" 2 "UNUSED" 1 "TRUE" 0 "FALSE" ;
VAL_ 798 PARK_majorVersion 255 "SNA" ;
VAL_ 798 PARK_minorVersion 255 "SNA" ;
VAL_ 798 PARK_subMinorVersion 255 "SNA" ;
VAL_ 782 PARK_pscRightCurbType 2 "HIGH_CURB" 1 "LOW_CURB" 0 "VIRTUAL_CURB" ;
VAL_ 782 PARK_pscLeftCurbType 2 "HIGH_CURB" 1 "LOW_CURB" 0 "VIRTUAL_CURB" ;
VAL_ 782 PARK_autoCalComplete 1 "COMPLETE" 0 "INCOMPLETE" ;
VAL_ 782 PARK_geometryType 3 "MODELY" 2 "MODEL3" 1 "MODELX" 0 "MODELS" ;
VAL_ 782 PARK_tireFitment 3 "SNA" 2 "NOT_USED" 1 "STAGGERED" 0 "SQUARE" ;
VAL_ 782 PARK_rackDetected 3 "SNA" 2 "RACK_DETECTED" 1 "NO_RACK" 0 "UNKNOWN" ;
VAL_ 782 PARK_sdiActive 1 "SDI_ENABLED" 0 "SDI_DISABLED" ;
VAL_ 782 PARK_sdiNoise 3 "SDI_NOISE_SNA" 2 "SDI_NOISE_RAIN" 1 "SDI_NOISE_HIGH" 0 "SDI_NOISE_NOMINAL" ;
VAL_ 782 PARK_sdiBlindSpotRight 3 "SNA" 2 "UNUSED" 1 "WARNING" 0 "NO_WARNING" ;
VAL_ 782 PARK_sdiBlindSpotLeft 3 "SNA" 2 "UNUSED" 1 "WARNING" 0 "NO_WARNING" ;
VAL_ 782 PARK_sensorType 3 "SNA" 2 "VALEO_HP" 1 "VALEO_HPFL" 0 "NONE" ;
VAL_ 894 PARK_matrixIndex 1 "AlertMatrix1" 0 "AlertMatrix0" ;
